VERSION ""

NS_ :

BS_:

BU_:

BO_ 2364613630 DCDC4OS: 8 Vector__XXX
 SG_ DCDC4HVILStatus : 4|2@1+ (1,0) [0|3] "" Vector__XXX
 SG_ DCDC4LoadshedRequest : 6|2@1+ (1,0) [0|3] "" Vector__XXX
 SG_ DCDC4OperationalStatus : 0|4@1+ (1,0) [0|15] "" Vector__XXX
 SG_ DCDC4PwrLmtdtCnvrtrTmprtr : 20|2@1+ (1,0) [0|3] "" Vector__XXX
 SG_ DCDC4PwrLmtdtEltrnFltrTmprtr : 22|2@1+ (1,0) [0|3] "" Vector__XXX
 SG_ DCDC4PwrLmtdtHghSdCrrnt : 8|2@1+ (1,0) [0|3] "" Vector__XXX
 SG_ DCDC4PwrLmtdtHghSdVltgMnmm : 12|2@1+ (1,0) [0|3] "" Vector__XXX
 SG_ DCDC4PwrLmtdtHghSdVltgMxmm : 14|2@1+ (1,0) [0|3] "" Vector__XXX
 SG_ DCDC4PwrLmtdtLwSdCrrnt : 10|2@1+ (1,0) [0|3] "" Vector__XXX
 SG_ DCDC4PwrLmtdtLwSdVltgMnmm : 16|2@1+ (1,0) [0|3] "" Vector__XXX
 SG_ DCDC4PwrLmtdtLwSdVltgMxmm : 18|2@1+ (1,0) [0|3] "" Vector__XXX
 SG_ DCDC4PwrLmtdtPwrEltrnsTmprtr : 24|2@1+ (1,0) [0|3] "" Vector__XXX
 SG_ DCDC4PwrLmtdtSLIBttrTrmnlCrrnt : 28|2@1+ (1,0) [0|3] "" Vector__XXX
 SG_ DCDC4PwrLmtdtSLIBttrTrmnlTmprtr : 30|2@1+ (1,0) [0|3] "" Vector__XXX
 SG_ DCDC4PwrLmtdtSLIBttrTrmnlVltg : 26|2@1+ (1,0) [0|3] "" Vector__XXX
 SG_ DCDC4PwrLmtdtUndfndRsn : 32|2@1+ (1,0) [0|3] "" Vector__XXX
 SG_ DCDC4OperatingStatusCounter : 52|4@1+ (1,0) [0|15] "" Vector__XXX
 SG_ DCDC4OperatingStatusCRC : 56|8@1+ (1,0) [0|255] "count" Vector__XXX

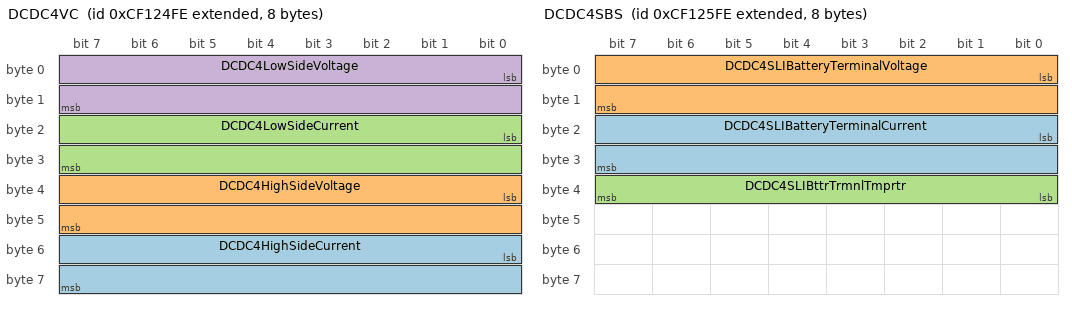
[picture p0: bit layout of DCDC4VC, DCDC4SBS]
BO_ 2364613886 DCDC4VC: 8 Vector__XXX
 SG_ DCDC4HighSideCurrent : 48|16@1+ (0.1,-3212.7) [-3212.7|3212.8] "A" Vector__XXX
 SG_ DCDC4HighSideVoltage : 32|16@1+ (0.05,0) [0|3212.75] "V" Vector__XXX
 SG_ DCDC4LowSideCurrent : 16|16@1+ (0.1,-3212.7) [-3212.7|3212.8] "A" Vector__XXX
 SG_ DCDC4LowSideVoltage : 0|16@1+ (0.01,0) [0|642.55] "V" Vector__XXX

BO_ 2364614142 DCDC4SBS: 8 Vector__XXX
 SG_ DCDC4SLIBatteryTerminalCurrent : 16|16@1+ (0.1,-3212.7) [-3212.7|3212.8] "A" Vector__XXX
 SG_ DCDC4SLIBatteryTerminalVoltage : 0|16@1+ (0.01,0) [0|642.55] "V" Vector__XXX
 SG_ DCDC4SLIBttrTrmnlTmprtr : 32|8@1+ (1,-40) [-40|210] "degC" Vector__XXX

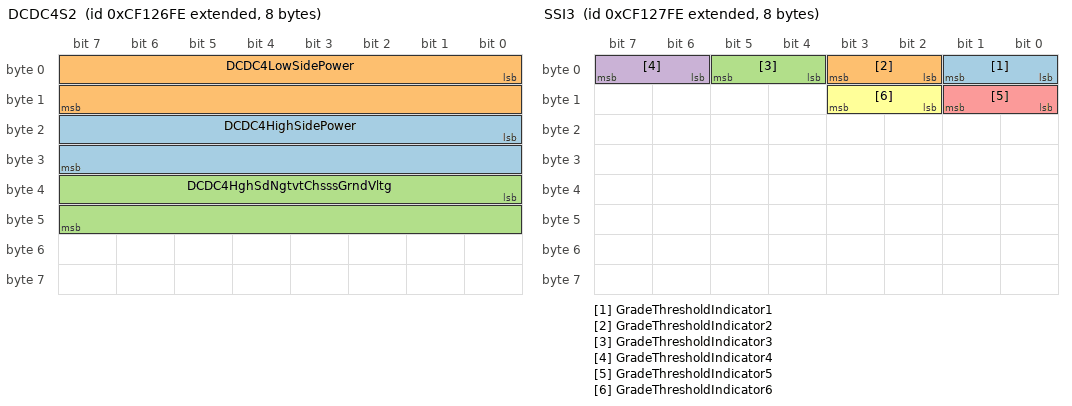
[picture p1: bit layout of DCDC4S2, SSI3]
BO_ 2364614398 DCDC4S2: 8 Vector__XXX
 SG_ DCDC4HighSidePower : 16|16@1+ (0.05,-1600) [-1600|1612.75] "kW" Vector__XXX
 SG_ DCDC4LowSidePower : 0|16@1+ (0.05,-1600) [-1600|1612.75] "kW" Vector__XXX
 SG_ DCDC4HghSdNgtvtChsssGrndVltg : 32|16@1+ (0.05,0) [0|3212.75] "V" Vector__XXX

BO_ 2364614654 SSI3: 8 Vector__XXX
 SG_ GradeThresholdIndicator1 : 0|2@1+ (1,0) [0|3] "" Vector__XXX
 SG_ GradeThresholdIndicator2 : 2|2@1+ (1,0) [0|3] "" Vector__XXX
 SG_ GradeThresholdIndicator3 : 4|2@1+ (1,0) [0|3] "" Vector__XXX
 SG_ GradeThresholdIndicator4 : 6|2@1+ (1,0) [0|3] "" Vector__XXX
 SG_ GradeThresholdIndicator5 : 8|2@1+ (1,0) [0|3] "" Vector__XXX
 SG_ GradeThresholdIndicator6 : 10|2@1+ (1,0) [0|3] "" Vector__XXX

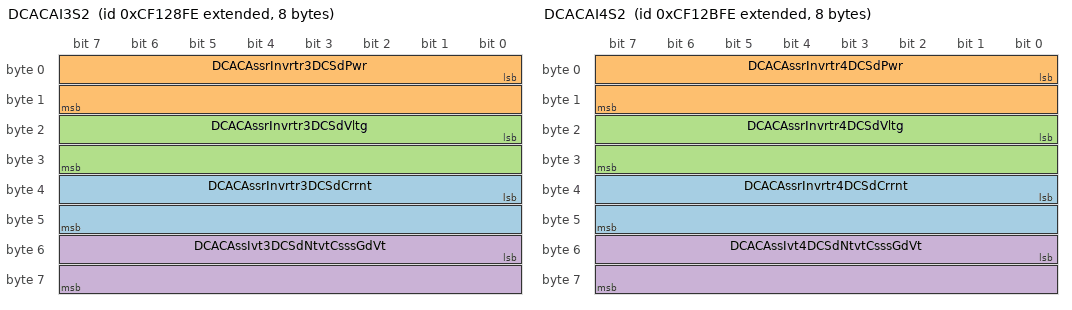
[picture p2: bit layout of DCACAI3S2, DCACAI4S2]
BO_ 2364614910 DCACAI3S2: 8 Vector__XXX
 SG_ DCACAssrInvrtr3DCSdCrrnt : 32|16@1+ (0.0625,0) [0|4015.9375] "A" Vector__XXX
 SG_ DCACAssrInvrtr3DCSdPwr : 0|16@1+ (0.0625,0) [0|4015.9375] "kW" Vector__XXX
 SG_ DCACAssrInvrtr3DCSdVltg : 16|16@1+ (0.05,0) [0|3212.75] "V" Vector__XXX
 SG_ DCACAssIvt3DCSdNtvtCsssGdVt : 48|16@1+ (0.05,0) [0|3212.75] "V" Vector__XXX

BO_ 2364615166 DCACAI3V: 8 Vector__XXX
 SG_ DCACAssrInvrtr3IgntnVltg : 0|16@1+ (0.05,0) [0|3212.75] "V" Vector__XXX
 SG_ DCACAssrInvrtr3UnswthdSLIVltg : 16|16@1+ (0.05,0) [0|3212.75] "V" Vector__XXX

BO_ 2364615678 DCACAI4S2: 8 Vector__XXX
 SG_ DCACAssrInvrtr4DCSdCrrnt : 32|16@1+ (0.0625,0) [0|4015.9375] "A" Vector__XXX
 SG_ DCACAssrInvrtr4DCSdPwr : 0|16@1+ (0.0625,0) [0|4015.9375] "kW" Vector__XXX
 SG_ DCACAssrInvrtr4DCSdVltg : 16|16@1+ (0.05,0) [0|3212.75] "V" Vector__XXX
 SG_ DCACAssIvt4DCSdNtvtCsssGdVt : 48|16@1+ (0.05,0) [0|3212.75] "V" Vector__XXX

BO_ 2364615934 DCACAI4V: 8 Vector__XXX
 SG_ DCACAssrInvrtr4IgntnVltg : 0|16@1+ (0.05,0) [0|3212.75] "V" Vector__XXX
 SG_ DCACAssrInvrtr4UnswthdSLIVltg : 16|16@1+ (0.05,0) [0|3212.75] "V" Vector__XXX

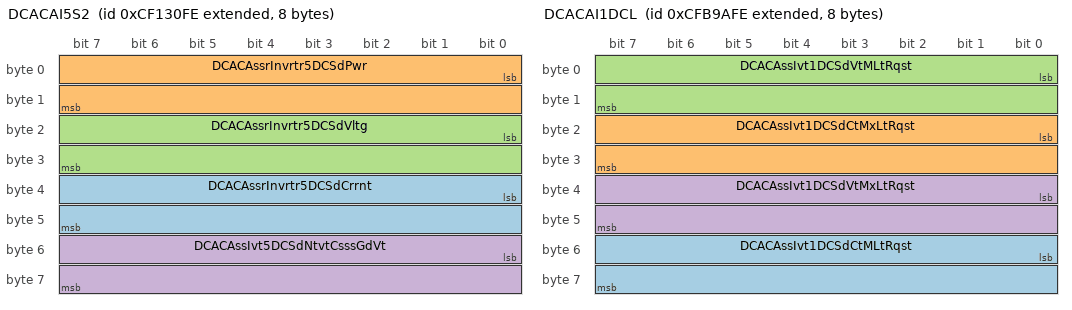
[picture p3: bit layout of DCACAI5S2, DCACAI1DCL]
BO_ 2364616958 DCACAI5S2: 8 Vector__XXX
 SG_ DCACAssrInvrtr5DCSdCrrnt : 32|16@1+ (0.0625,0) [0|4015.9375] "A" Vector__XXX
 SG_ DCACAssrInvrtr5DCSdPwr : 0|16@1+ (0.0625,0) [0|4015.9375] "kW" Vector__XXX
 SG_ DCACAssrInvrtr5DCSdVltg : 16|16@1+ (0.05,0) [0|3212.75] "V" Vector__XXX
 SG_ DCACAssIvt5DCSdNtvtCsssGdVt : 48|16@1+ (0.05,0) [0|3212.75] "V" Vector__XXX

BO_ 2364617214 DCACAI5V: 8 Vector__XXX
 SG_ DCACAssrInvrtr5IgntnVltg : 0|16@1+ (0.05,0) [0|3212.75] "V" Vector__XXX
 SG_ DCACAssrInvrtr5UnswthdSLIVltg : 16|16@1+ (0.05,0) [0|3212.75] "V" Vector__XXX

BO_ 2365296894 DCDC4V: 8 Vector__XXX
 SG_ DCDC4CntrllrInptIgntnVltg : 0|16@1+ (0.05,0) [0|3212.75] "V" Vector__XXX
 SG_ DCDC4CntrllrInptUnswthdSLIVltg : 16|16@1+ (0.05,0) [0|3212.75] "V" Vector__XXX

BO_ 2365297150 DCDC3V: 8 Vector__XXX
 SG_ DCDC3CntrllrInptIgntnVltg : 0|16@1+ (0.05,0) [0|3212.75] "V" Vector__XXX
 SG_ DCDC3CntrllrInptUnswthdSLIVltg : 16|16@1+ (0.05,0) [0|3212.75] "V" Vector__XXX

BO_ 2365297406 DCDC2V: 8 Vector__XXX
 SG_ DCDC2CntrllrInptIgntnVltg : 0|16@1+ (0.05,0) [0|3212.75] "V" Vector__XXX
 SG_ DCDC2CntrllrInptUnswthdSLIVltg : 16|16@1+ (0.05,0) [0|3212.75] "V" Vector__XXX

BO_ 2365297662 DCDC1V: 8 Vector__XXX
 SG_ DCDC1CntrllrInptIgntnVltg : 0|16@1+ (0.05,0) [0|3212.75] "V" Vector__XXX
 SG_ DCDC1CntrllrInptUnswthdSLIVltg : 16|16@1+ (0.05,0) [0|3212.75] "V" Vector__XXX

BO_ 2365299454 DCACAI1DCL: 8 Vector__XXX
 SG_ DCACAssIvt1DCSdCtMLtRqst : 48|16@1+ (0.05,-3212.75) [-3212.75|0] "A" Vector__XXX
 SG_ DCACAssIvt1DCSdCtMxLtRqst : 16|16@1+ (0.05,0) [0|3212.75] "A" Vector__XXX
 SG_ DCACAssIvt1DCSdVtMLtRqst : 0|16@1+ (0.05,0) [0|3212.75] "V" Vector__XXX
 SG_ DCACAssIvt1DCSdVtMxLtRqst : 32|16@1+ (0.05,0) [0|3212.75] "V" Vector__XXX

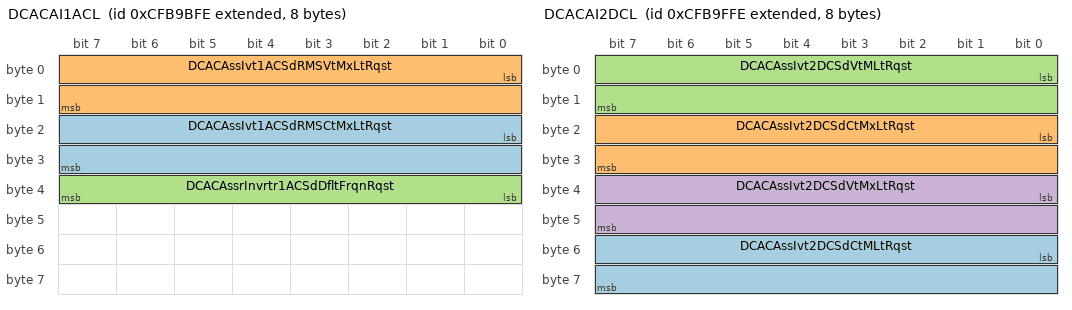
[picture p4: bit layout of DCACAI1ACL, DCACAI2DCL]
BO_ 2365299710 DCACAI1ACL: 8 Vector__XXX
 SG_ DCACAssIvt1ACSdRMSCtMxLtRqst : 16|16@1+ (0.03125,0) [0|2007.96875] "A" Vector__XXX
 SG_ DCACAssIvt1ACSdRMSVtMxLtRqst : 0|16@1+ (0.03125,0) [0|2007.96875] "V" Vector__XXX
 SG_ DCACAssrInvrtr1ACSdDfltFrqnRqst : 32|8@1+ (1,0) [0|250] "Hz" Vector__XXX

BO_ 2365300734 DCACAI2DCL: 8 Vector__XXX
 SG_ DCACAssIvt2DCSdCtMLtRqst : 48|16@1+ (0.05,-3212.75) [-3212.75|0] "A" Vector__XXX
 SG_ DCACAssIvt2DCSdCtMxLtRqst : 16|16@1+ (0.05,0) [0|3212.75] "A" Vector__XXX
 SG_ DCACAssIvt2DCSdVtMLtRqst : 0|16@1+ (0.05,0) [0|3212.75] "V" Vector__XXX
 SG_ DCACAssIvt2DCSdVtMxLtRqst : 32|16@1+ (0.05,0) [0|3212.75] "V" Vector__XXX

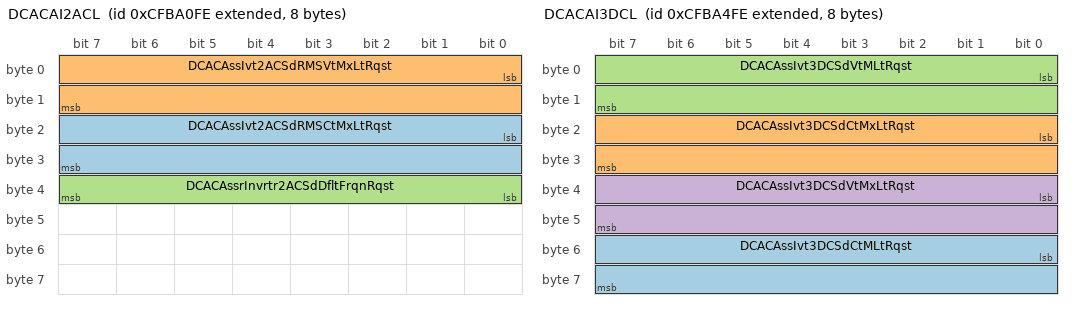
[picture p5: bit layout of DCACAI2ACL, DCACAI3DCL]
BO_ 2365300990 DCACAI2ACL: 8 Vector__XXX
 SG_ DCACAssIvt2ACSdRMSCtMxLtRqst : 16|16@1+ (0.03125,0) [0|2007.96875] "A" Vector__XXX
 SG_ DCACAssIvt2ACSdRMSVtMxLtRqst : 0|16@1+ (0.03125,0) [0|2007.96875] "V" Vector__XXX
 SG_ DCACAssrInvrtr2ACSdDfltFrqnRqst : 32|8@1+ (1,0) [0|250] "Hz" Vector__XXX

BO_ 2365302014 DCACAI3DCL: 8 Vector__XXX
 SG_ DCACAssIvt3DCSdCtMLtRqst : 48|16@1+ (0.05,-3212.75) [-3212.75|0] "A" Vector__XXX
 SG_ DCACAssIvt3DCSdCtMxLtRqst : 16|16@1+ (0.05,0) [0|3212.75] "A" Vector__XXX
 SG_ DCACAssIvt3DCSdVtMLtRqst : 0|16@1+ (0.05,0) [0|3212.75] "V" Vector__XXX
 SG_ DCACAssIvt3DCSdVtMxLtRqst : 32|16@1+ (0.05,0) [0|3212.75] "V" Vector__XXX

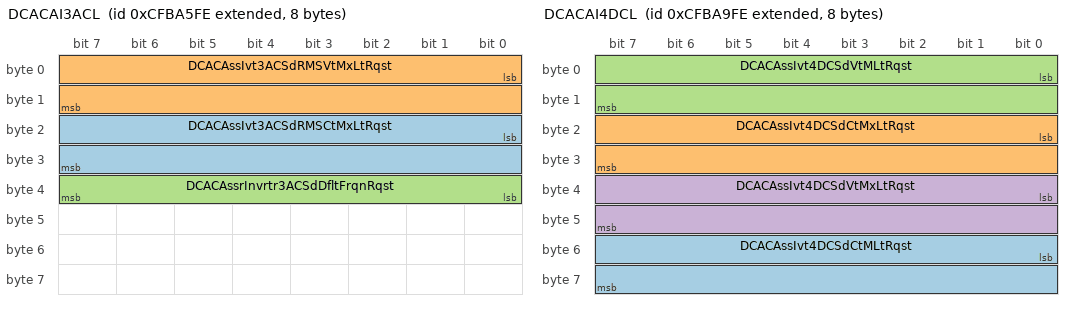
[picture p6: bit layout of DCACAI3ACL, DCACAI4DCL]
BO_ 2365302270 DCACAI3ACL: 8 Vector__XXX
 SG_ DCACAssIvt3ACSdRMSCtMxLtRqst : 16|16@1+ (0.03125,0) [0|2007.96875] "A" Vector__XXX
 SG_ DCACAssIvt3ACSdRMSVtMxLtRqst : 0|16@1+ (0.03125,0) [0|2007.96875] "V" Vector__XXX
 SG_ DCACAssrInvrtr3ACSdDfltFrqnRqst : 32|8@1+ (1,0) [0|250] "Hz" Vector__XXX

BO_ 2365303294 DCACAI4DCL: 8 Vector__XXX
 SG_ DCACAssIvt4DCSdCtMLtRqst : 48|16@1+ (0.05,-3212.75) [-3212.75|0] "A" Vector__XXX
 SG_ DCACAssIvt4DCSdCtMxLtRqst : 16|16@1+ (0.05,0) [0|3212.75] "A" Vector__XXX
 SG_ DCACAssIvt4DCSdVtMLtRqst : 0|16@1+ (0.05,0) [0|3212.75] "V" Vector__XXX
 SG_ DCACAssIvt4DCSdVtMxLtRqst : 32|16@1+ (0.05,0) [0|3212.75] "V" Vector__XXX

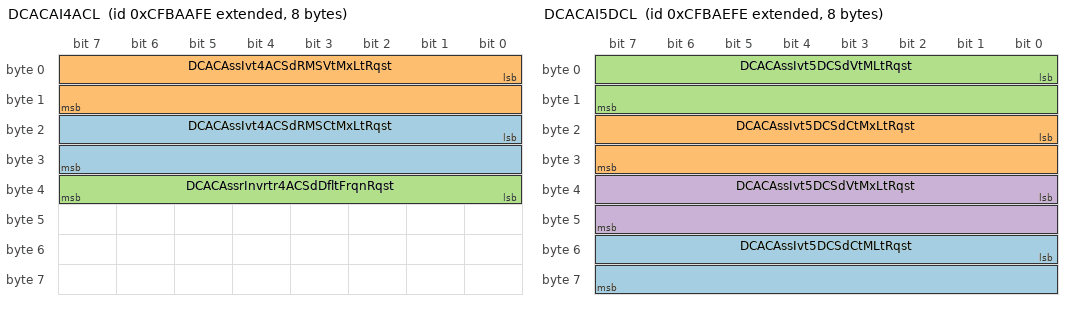
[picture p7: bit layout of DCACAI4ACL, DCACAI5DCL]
BO_ 2365303550 DCACAI4ACL: 8 Vector__XXX
 SG_ DCACAssIvt4ACSdRMSCtMxLtRqst : 16|16@1+ (0.03125,0) [0|2007.96875] "A" Vector__XXX
 SG_ DCACAssIvt4ACSdRMSVtMxLtRqst : 0|16@1+ (0.03125,0) [0|2007.96875] "V" Vector__XXX
 SG_ DCACAssrInvrtr4ACSdDfltFrqnRqst : 32|8@1+ (1,0) [0|250] "Hz" Vector__XXX

BO_ 2365304574 DCACAI5DCL: 8 Vector__XXX
 SG_ DCACAssIvt5DCSdCtMLtRqst : 48|16@1+ (0.05,-3212.75) [-3212.75|0] "A" Vector__XXX
 SG_ DCACAssIvt5DCSdCtMxLtRqst : 16|16@1+ (0.05,0) [0|3212.75] "A" Vector__XXX
 SG_ DCACAssIvt5DCSdVtMLtRqst : 0|16@1+ (0.05,0) [0|3212.75] "V" Vector__XXX
 SG_ DCACAssIvt5DCSdVtMxLtRqst : 32|16@1+ (0.05,0) [0|3212.75] "V" Vector__XXX

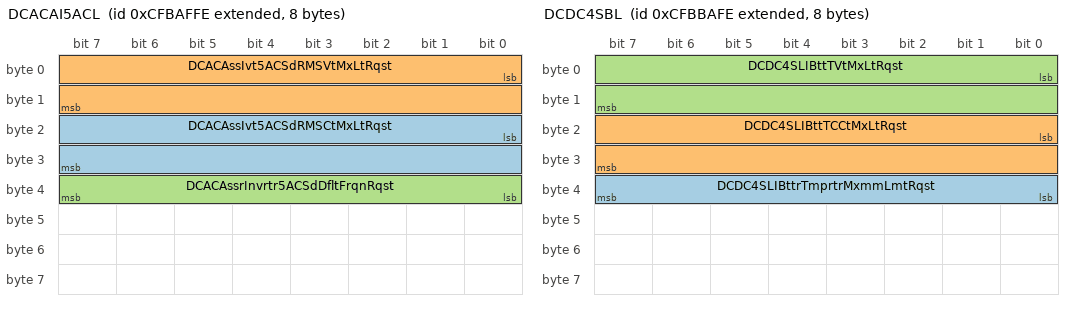
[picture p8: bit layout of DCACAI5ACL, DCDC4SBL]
BO_ 2365304830 DCACAI5ACL: 8 Vector__XXX
 SG_ DCACAssIvt5ACSdRMSCtMxLtRqst : 16|16@1+ (0.03125,0) [0|2007.96875] "A" Vector__XXX
 SG_ DCACAssIvt5ACSdRMSVtMxLtRqst : 0|16@1+ (0.03125,0) [0|2007.96875] "V" Vector__XXX
 SG_ DCACAssrInvrtr5ACSdDfltFrqnRqst : 32|8@1+ (1,0) [0|250] "Hz" Vector__XXX

BO_ 2365307646 DCDC4SBL: 8 Vector__XXX
 SG_ DCDC4SLIBttrTmprtrMxmmLmtRqst : 32|8@1+ (1,-40) [-40|210] "degC" Vector__XXX
 SG_ DCDC4SLIBttTCCtMxLtRqst : 16|16@1+ (0.05,0) [0|3212.75] "A" Vector__XXX
 SG_ DCDC4SLIBttTVtMxLtRqst : 0|16@1+ (0.01,0) [0|642.55] "V" Vector__XXX

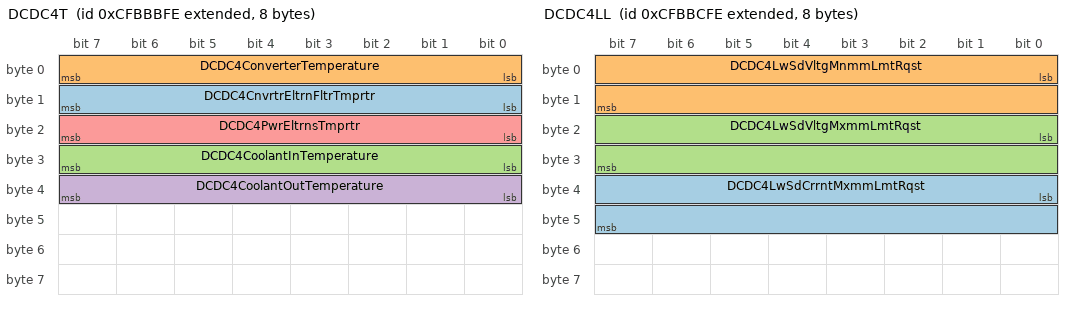
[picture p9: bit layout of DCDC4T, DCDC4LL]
BO_ 2365307902 DCDC4T: 8 Vector__XXX
 SG_ DCDC4CnvrtrEltrnFltrTmprtr : 8|8@1+ (1,-40) [-40|210] "degC" Vector__XXX
 SG_ DCDC4ConverterTemperature : 0|8@1+ (1,-40) [-40|210] "degC" Vector__XXX
 SG_ DCDC4CoolantInTemperature : 24|8@1+ (1,-40) [-40|210] "degC" Vector__XXX
 SG_ DCDC4CoolantOutTemperature : 32|8@1+ (1,-40) [-40|210] "degC" Vector__XXX
 SG_ DCDC4PwrEltrnsTmprtr : 16|8@1+ (1,-40) [-40|210] "degC" Vector__XXX

BO_ 2365308158 DCDC4LL: 8 Vector__XXX
 SG_ DCDC4LwSdCrrntMxmmLmtRqst : 32|16@1+ (0.05,0) [0|3212.75] "A" Vector__XXX
 SG_ DCDC4LwSdVltgMnmmLmtRqst : 0|16@1+ (0.01,0) [0|642.55] "V" Vector__XXX
 SG_ DCDC4LwSdVltgMxmmLmtRqst : 16|16@1+ (0.01,0) [0|642.55] "V" Vector__XXX

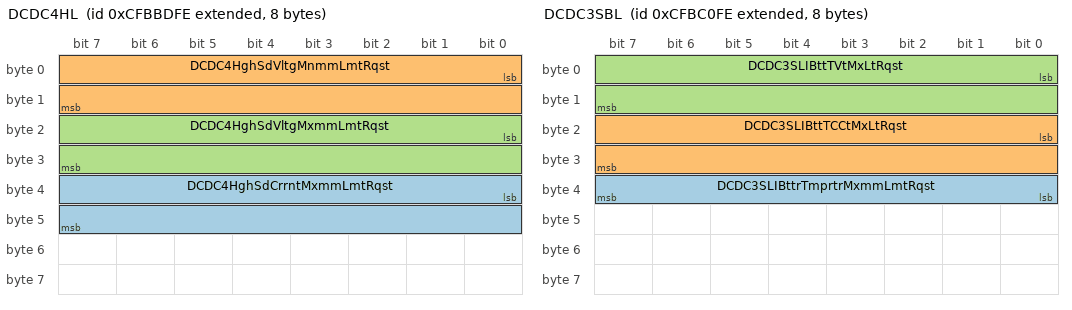
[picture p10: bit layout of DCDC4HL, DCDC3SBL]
BO_ 2365308414 DCDC4HL: 8 Vector__XXX
 SG_ DCDC4HghSdCrrntMxmmLmtRqst : 32|16@1+ (0.05,0) [0|3212.75] "A" Vector__XXX
 SG_ DCDC4HghSdVltgMnmmLmtRqst : 0|16@1+ (0.05,0) [0|3212.75] "V" Vector__XXX
 SG_ DCDC4HghSdVltgMxmmLmtRqst : 16|16@1+ (0.05,0) [0|3212.75] "V" Vector__XXX

BO_ 2365309182 DCDC3SBL: 8 Vector__XXX
 SG_ DCDC3SLIBttrTmprtrMxmmLmtRqst : 32|8@1+ (1,-40) [-40|210] "degC" Vector__XXX
 SG_ DCDC3SLIBttTCCtMxLtRqst : 16|16@1+ (0.05,0) [0|3212.75] "A" Vector__XXX
 SG_ DCDC3SLIBttTVtMxLtRqst : 0|16@1+ (0.01,0) [0|642.55] "V" Vector__XXX

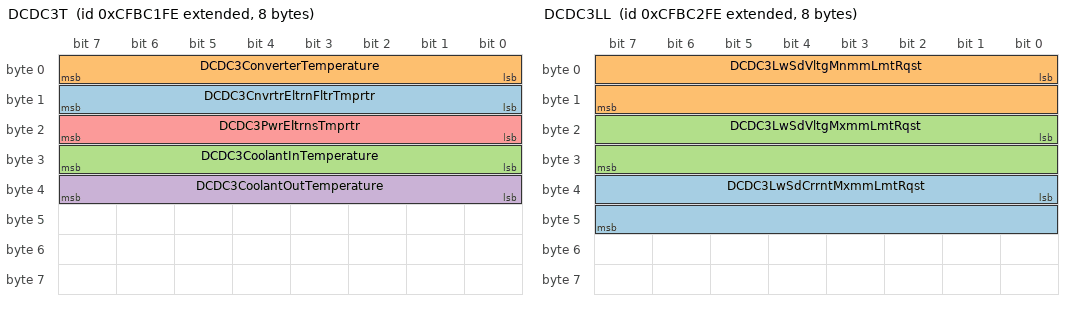
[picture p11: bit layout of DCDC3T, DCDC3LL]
BO_ 2365309438 DCDC3T: 8 Vector__XXX
 SG_ DCDC3CnvrtrEltrnFltrTmprtr : 8|8@1+ (1,-40) [-40|210] "degC" Vector__XXX
 SG_ DCDC3ConverterTemperature : 0|8@1+ (1,-40) [-40|210] "degC" Vector__XXX
 SG_ DCDC3CoolantInTemperature : 24|8@1+ (1,-40) [-40|210] "degC" Vector__XXX
 SG_ DCDC3CoolantOutTemperature : 32|8@1+ (1,-40) [-40|210] "degC" Vector__XXX
 SG_ DCDC3PwrEltrnsTmprtr : 16|8@1+ (1,-40) [-40|210] "degC" Vector__XXX

BO_ 2365309694 DCDC3LL: 8 Vector__XXX
 SG_ DCDC3LwSdCrrntMxmmLmtRqst : 32|16@1+ (0.05,0) [0|3212.75] "A" Vector__XXX
 SG_ DCDC3LwSdVltgMnmmLmtRqst : 0|16@1+ (0.01,0) [0|642.55] "V" Vector__XXX
 SG_ DCDC3LwSdVltgMxmmLmtRqst : 16|16@1+ (0.01,0) [0|642.55] "V" Vector__XXX

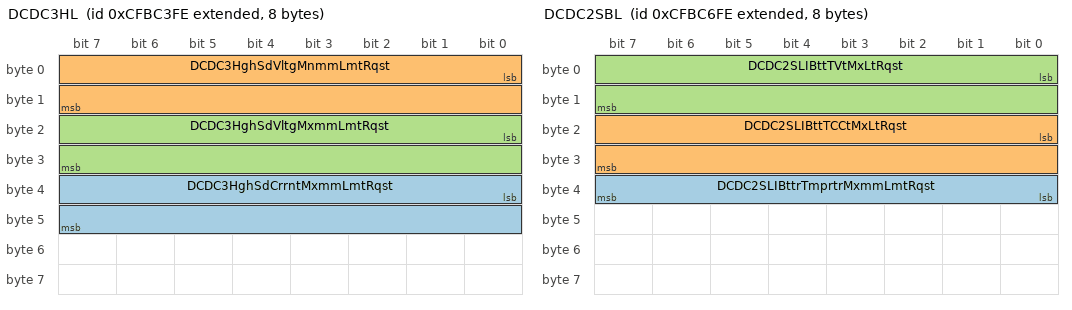
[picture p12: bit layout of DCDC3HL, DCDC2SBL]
BO_ 2365309950 DCDC3HL: 8 Vector__XXX
 SG_ DCDC3HghSdCrrntMxmmLmtRqst : 32|16@1+ (0.05,0) [0|3212.75] "A" Vector__XXX
 SG_ DCDC3HghSdVltgMnmmLmtRqst : 0|16@1+ (0.05,0) [0|3212.75] "V" Vector__XXX
 SG_ DCDC3HghSdVltgMxmmLmtRqst : 16|16@1+ (0.05,0) [0|3212.75] "V" Vector__XXX

BO_ 2365310718 DCDC2SBL: 8 Vector__XXX
 SG_ DCDC2SLIBttrTmprtrMxmmLmtRqst : 32|8@1+ (1,-40) [-40|210] "degC" Vector__XXX
 SG_ DCDC2SLIBttTCCtMxLtRqst : 16|16@1+ (0.05,0) [0|3212.75] "A" Vector__XXX
 SG_ DCDC2SLIBttTVtMxLtRqst : 0|16@1+ (0.01,0) [0|642.55] "V" Vector__XXX

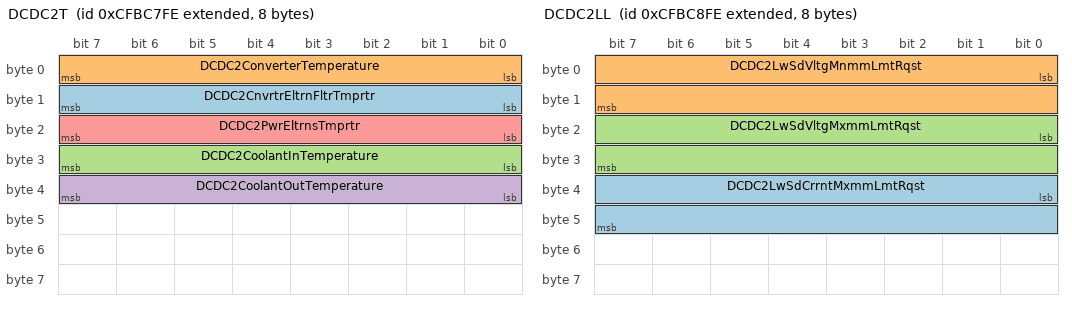
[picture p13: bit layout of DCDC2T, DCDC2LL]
BO_ 2365310974 DCDC2T: 8 Vector__XXX
 SG_ DCDC2CnvrtrEltrnFltrTmprtr : 8|8@1+ (1,-40) [-40|210] "degC" Vector__XXX
 SG_ DCDC2ConverterTemperature : 0|8@1+ (1,-40) [-40|210] "degC" Vector__XXX
 SG_ DCDC2CoolantInTemperature : 24|8@1+ (1,-40) [-40|210] "degC" Vector__XXX
 SG_ DCDC2CoolantOutTemperature : 32|8@1+ (1,-40) [-40|210] "degC" Vector__XXX
 SG_ DCDC2PwrEltrnsTmprtr : 16|8@1+ (1,-40) [-40|210] "degC" Vector__XXX

BO_ 2365311230 DCDC2LL: 8 Vector__XXX
 SG_ DCDC2LwSdCrrntMxmmLmtRqst : 32|16@1+ (0.05,0) [0|3212.75] "A" Vector__XXX
 SG_ DCDC2LwSdVltgMnmmLmtRqst : 0|16@1+ (0.01,0) [0|642.55] "V" Vector__XXX
 SG_ DCDC2LwSdVltgMxmmLmtRqst : 16|16@1+ (0.01,0) [0|642.55] "V" Vector__XXX

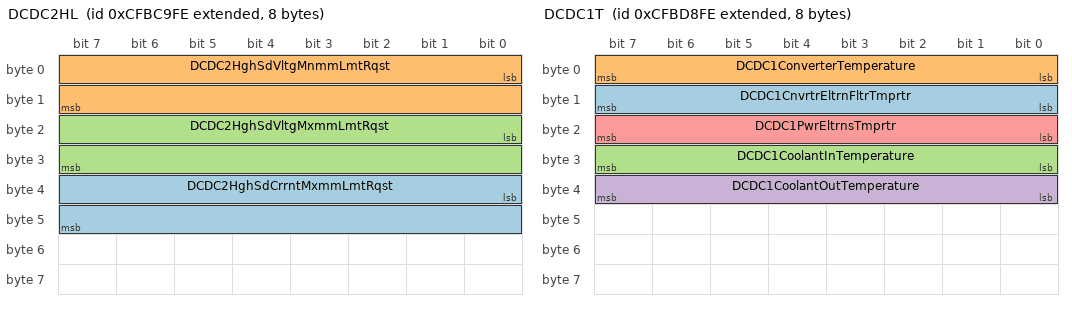
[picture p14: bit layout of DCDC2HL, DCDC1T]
BO_ 2365311486 DCDC2HL: 8 Vector__XXX
 SG_ DCDC2HghSdCrrntMxmmLmtRqst : 32|16@1+ (0.05,0) [0|3212.75] "A" Vector__XXX
 SG_ DCDC2HghSdVltgMnmmLmtRqst : 0|16@1+ (0.05,0) [0|3212.75] "V" Vector__XXX
 SG_ DCDC2HghSdVltgMxmmLmtRqst : 16|16@1+ (0.05,0) [0|3212.75] "V" Vector__XXX

BO_ 2365313534 DCDC1SBL: 8 Vector__XXX
 SG_ DCDC1SLIBttrTmprtrMxmmLmtRqst : 32|8@1+ (1,-40) [-40|210] "degC" Vector__XXX
 SG_ DCDC1SLIBttTCCtMxLtRqst : 16|16@1+ (0.05,0) [0|3212.75] "A" Vector__XXX
 SG_ DCDC1SLIBttTVtMxLtRqst : 0|16@1+ (0.01,0) [0|642.55] "V" Vector__XXX

BO_ 2365315326 DCDC1T: 8 Vector__XXX
 SG_ DCDC1CnvrtrEltrnFltrTmprtr : 8|8@1+ (1,-40) [-40|210] "degC" Vector__XXX
 SG_ DCDC1ConverterTemperature : 0|8@1+ (1,-40) [-40|210] "degC" Vector__XXX
 SG_ DCDC1CoolantInTemperature : 24|8@1+ (1,-40) [-40|210] "degC" Vector__XXX
 SG_ DCDC1CoolantOutTemperature : 32|8@1+ (1,-40) [-40|210] "degC" Vector__XXX
 SG_ DCDC1PwrEltrnsTmprtr : 16|8@1+ (1,-40) [-40|210] "degC" Vector__XXX

BO_ 2365315582 DCDC1LL: 8 Vector__XXX
 SG_ DCDC1LwSdCrrntMxmmLmtRqst : 32|16@1+ (0.05,0) [0|3212.75] "A" Vector__XXX
 SG_ DCDC1LwSdVltgMnmmLmtRqst : 0|16@1+ (0.01,0) [0|642.55] "V" Vector__XXX
 SG_ DCDC1LwSdVltgMxmmLmtRqst : 16|16@1+ (0.01,0) [0|642.55] "V" Vector__XXX

BO_ 2365315838 DCDC1HL: 8 Vector__XXX
 SG_ DCDC1HghSdCrrntMxmmLmtRqst : 32|16@1+ (0.05,0) [0|3212.75] "A" Vector__XXX
 SG_ DCDC1HghSdVltgMnmmLmtRqst : 0|16@1+ (0.05,0) [0|3212.75] "V" Vector__XXX
 SG_ DCDC1HghSdVltgMxmmLmtRqst : 16|16@1+ (0.05,0) [0|3212.75] "V" Vector__XXX

BO_ 2365318910 HVESSFC: 8 Vector__XXX
 SG_ HVESSFanEnableCommand : 0|2@1+ (1,0) [0|3] "" Vector__XXX
 SG_ HVESSFanPowerHold : 2|2@1+ (1,0) [0|3] "" Vector__XXX
 SG_ HVESSFanSpeedCommand : 8|16@1+ (0.5,0) [0|32127.5] "rpm" Vector__XXX
 SG_ HVESSFanPercentSpeedCommand : 24|8@1+ (0.4,0) [0|100] "%" Vector__XXX
 SG_ HVESSFanInstance1 : 32|1@1+ (1,0) [0|1] "" Vector__XXX
 SG_ HVESSFanInstance2 : 33|1@1+ (1,0) [0|1] "" Vector__XXX
 SG_ HVESSFanInstance3 : 34|1@1+ (1,0) [0|1] "" Vector__XXX
 SG_ HVESSFanInstance4 : 35|1@1+ (1,0) [0|1] "" Vector__XXX
 SG_ HVESSFanInstance5 : 36|1@1+ (1,0) [0|1] "" Vector__XXX
 SG_ HVESSFanInstance6 : 37|1@1+ (1,0) [0|1] "" Vector__XXX
 SG_ HVESSFanInstance7 : 38|1@1+ (1,0) [0|1] "" Vector__XXX
 SG_ HVESSFanInstance8 : 39|1@1+ (1,0) [0|1] "" Vector__XXX
 SG_ HVESSFanInstance9 : 40|1@1+ (1,0) [0|1] "" Vector__XXX
 SG_ HVESSFanInstance10 : 41|1@1+ (1,0) [0|1] "" Vector__XXX
 SG_ HVESSFanInstance11 : 42|1@1+ (1,0) [0|1] "" Vector__XXX
 SG_ HVESSFanInstance12 : 43|1@1+ (1,0) [0|1] "" Vector__XXX
 SG_ HVESSFanInstance13 : 44|1@1+ (1,0) [0|1] "" Vector__XXX
 SG_ HVESSFanInstance14 : 45|1@1+ (1,0) [0|1] "" Vector__XXX
 SG_ HVESSFanInstance15 : 46|1@1+ (1,0) [0|1] "" Vector__XXX

BO_ 2365322238 CCVS5: 8 Vector__XXX
 SG_ DirectionalVehicleSpeed : 0|16@1+ (0.0078125,-250) [-250|251.992] "km/h" Vector__XXX

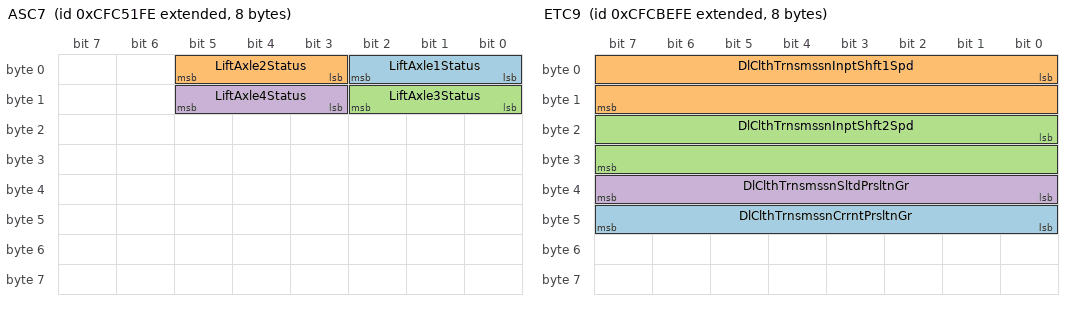
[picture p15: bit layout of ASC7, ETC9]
BO_ 2365346302 ASC7: 8 Vector__XXX
 SG_ LiftAxle1Status : 0|3@1+ (1,0) [0|7] "" Vector__XXX
 SG_ LiftAxle2Status : 3|3@1+ (1,0) [0|7] "" Vector__XXX
 SG_ LiftAxle3Status : 8|3@1+ (1,0) [0|7] "" Vector__XXX
 SG_ LiftAxle4Status : 11|3@1+ (1,0) [0|7] "" Vector__XXX

BO_ 2365348350 ELS: 8 Vector__XXX
 SG_ EngineLoadShareStatus : 2|4@1+ (1,0) [0|15] "" Vector__XXX
 SG_ EngineUnloadStatus : 0|2@1+ (1,0) [0|3] "" Vector__XXX

BO_ 2365363710 ECPMSI: 8 Vector__XXX
 SG_ EngnClndrPrssrMntr1PrlmnrFMI : 0|5@1+ (1,0) [0|31] "binary" Vector__XXX
 SG_ EngnClndrPrssrMntr2PrlmnrFMI : 8|5@1+ (1,0) [0|31] "binary" Vector__XXX

BO_ 2365374206 ETC9: 8 Vector__XXX
 SG_ DlClthTrnsmssnCrrntPrsltnGr : 40|8@1+ (1,-125) [-125|125] "gear value" Vector__XXX
 SG_ DlClthTrnsmssnInptShft1Spd : 0|16@1+ (0.125,0) [0|8031.875] "rpm" Vector__XXX
 SG_ DlClthTrnsmssnInptShft2Spd : 16|16@1+ (0.125,0) [0|8031.875] "rpm" Vector__XXX
 SG_ DlClthTrnsmssnSltdPrsltnGr : 32|8@1+ (1,-125) [-125|125] "gear value" Vector__XXX

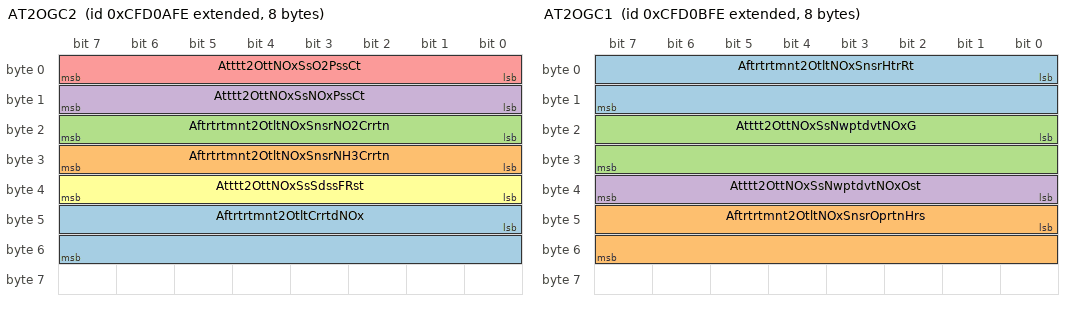
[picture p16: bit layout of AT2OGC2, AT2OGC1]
BO_ 2365393662 AT2OGC2: 8 Vector__XXX
 SG_ Aftrtrtmnt2OtltCrrtdNOx : 40|16@1+ (0.05,-200) [-200|3012.75] "ppm" Vector__XXX
 SG_ Aftrtrtmnt2OtltNOxSnsrNH3Crrtn : 24|8@1+ (0.5,0) [0|125] "%" Vector__XXX
 SG_ Aftrtrtmnt2OtltNOxSnsrNO2Crrtn : 16|8@1+ (0.5,0) [0|125] "%" Vector__XXX
 SG_ Atttt2OttNOxSsNOxPssCt : 8|8@1+ (0.5,0) [0|125] "%/bar" Vector__XXX
 SG_ Atttt2OttNOxSsO2PssCt : 0|8@1+ (0.5,0) [0|125] "%/bar" Vector__XXX
 SG_ Atttt2OttNOxSsSdssFRst : 32|8@1+ (1,0) [0|250] "Ratio" Vector__XXX

BO_ 2365393918 AT2OGC1: 8 Vector__XXX
 SG_ Aftrtrtmnt2OtltNOxSnsrHtrRt : 0|16@1+ (0.001,0) [0|64.255] "Ratio" Vector__XXX
 SG_ Aftrtrtmnt2OtltNOxSnsrOprtnHrs : 40|16@1+ (1,0) [0|64255] "h" Vector__XXX
 SG_ Atttt2OttNOxSsNwptdvtNOxG : 16|16@1+ (0.1,-100) [-100|6325.5] "%" Vector__XXX
 SG_ Atttt2OttNOxSsNwptdvtNOxOst : 32|8@1+ (1,-125) [-125|125] "ppm" Vector__XXX

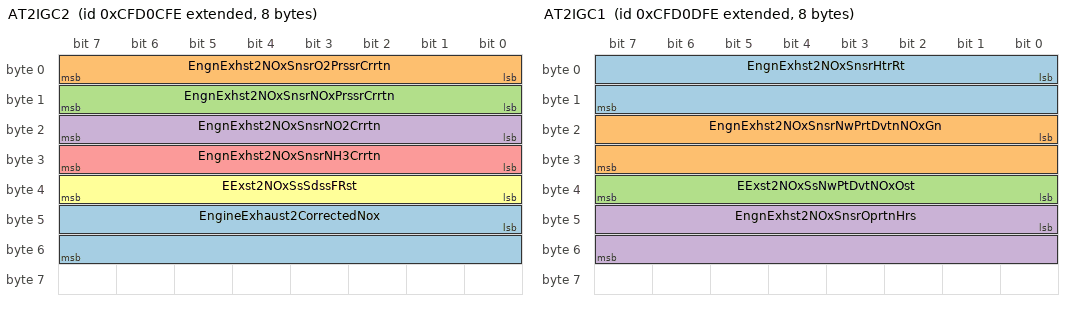
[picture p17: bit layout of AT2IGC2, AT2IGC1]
BO_ 2365394174 AT2IGC2: 8 Vector__XXX
 SG_ EngineExhaust2CorrectedNox : 40|16@1+ (0.05,-200) [-200|3012.75] "ppm" Vector__XXX
 SG_ EngnExhst2NOxSnsrO2PrssrCrrtn : 0|8@1+ (0.5,0) [0|125] "%/bar" Vector__XXX
 SG_ EngnExhst2NOxSnsrNOxPrssrCrrtn : 8|8@1+ (0.5,0) [0|125] "%/bar" Vector__XXX
 SG_ EngnExhst2NOxSnsrNO2Crrtn : 16|8@1+ (0.5,0) [0|125] "%" Vector__XXX
 SG_ EngnExhst2NOxSnsrNH3Crrtn : 24|8@1+ (0.5,0) [0|125] "%" Vector__XXX
 SG_ EExst2NOxSsSdssFRst : 32|8@1+ (1,0) [0|250] "Ratio" Vector__XXX

BO_ 2365394430 AT2IGC1: 8 Vector__XXX
 SG_ EngnExhst2NOxSnsrHtrRt : 0|16@1+ (0.001,0) [0|64.255] "Ratio" Vector__XXX
 SG_ EngnExhst2NOxSnsrNwPrtDvtnNOxGn : 16|16@1+ (0.1,-100) [-100|6325.5] "%" Vector__XXX
 SG_ EExst2NOxSsNwPtDvtNOxOst : 32|8@1+ (1,-125) [-125|125] "ppm" Vector__XXX
 SG_ EngnExhst2NOxSnsrOprtnHrs : 40|16@1+ (1,0) [0|64255] "h" Vector__XXX

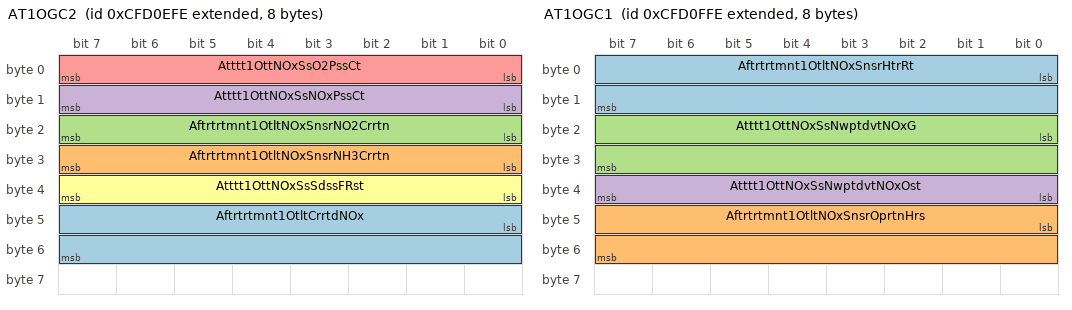
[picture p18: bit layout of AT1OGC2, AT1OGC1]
BO_ 2365394686 AT1OGC2: 8 Vector__XXX
 SG_ Aftrtrtmnt1OtltCrrtdNOx : 40|16@1+ (0.05,-200) [-200|3012.75] "ppm" Vector__XXX
 SG_ Aftrtrtmnt1OtltNOxSnsrNH3Crrtn : 24|8@1+ (0.5,0) [0|125] "%" Vector__XXX
 SG_ Aftrtrtmnt1OtltNOxSnsrNO2Crrtn : 16|8@1+ (0.5,0) [0|125] "%" Vector__XXX
 SG_ Atttt1OttNOxSsNOxPssCt : 8|8@1+ (0.5,0) [0|125] "%/bar" Vector__XXX
 SG_ Atttt1OttNOxSsO2PssCt : 0|8@1+ (0.5,0) [0|125] "%/bar" Vector__XXX
 SG_ Atttt1OttNOxSsSdssFRst : 32|8@1+ (1,0) [0|250] "Ratio" Vector__XXX

BO_ 2365394942 AT1OGC1: 8 Vector__XXX
 SG_ Aftrtrtmnt1OtltNOxSnsrHtrRt : 0|16@1+ (0.001,0) [0|64.255] "Ratio" Vector__XXX
 SG_ Aftrtrtmnt1OtltNOxSnsrOprtnHrs : 40|16@1+ (1,0) [0|64255] "h" Vector__XXX
 SG_ Atttt1OttNOxSsNwptdvtNOxG : 16|16@1+ (0.1,-100) [-100|6325.5] "%" Vector__XXX
 SG_ Atttt1OttNOxSsNwptdvtNOxOst : 32|8@1+ (1,-125) [-125|125] "ppm" Vector__XXX

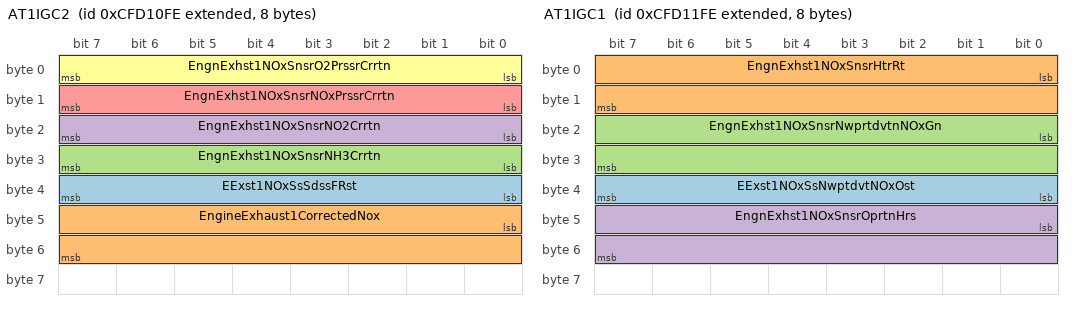
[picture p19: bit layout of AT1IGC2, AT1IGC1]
BO_ 2365395198 AT1IGC2: 8 Vector__XXX
 SG_ EExst1NOxSsSdssFRst : 32|8@1+ (1,0) [0|250] "Ratio" Vector__XXX
 SG_ EngineExhaust1CorrectedNox : 40|16@1+ (0.05,-200) [-200|3012.75] "ppm" Vector__XXX
 SG_ EngnExhst1NOxSnsrNH3Crrtn : 24|8@1+ (0.5,0) [0|125] "%" Vector__XXX
 SG_ EngnExhst1NOxSnsrNO2Crrtn : 16|8@1+ (0.5,0) [0|125] "%" Vector__XXX
 SG_ EngnExhst1NOxSnsrNOxPrssrCrrtn : 8|8@1+ (0.5,0) [0|125] "%/bar" Vector__XXX
 SG_ EngnExhst1NOxSnsrO2PrssrCrrtn : 0|8@1+ (0.5,0) [0|125] "%/bar" Vector__XXX

BO_ 2365395454 AT1IGC1: 8 Vector__XXX
 SG_ EExst1NOxSsNwptdvtNOxOst : 32|8@1+ (1,-125) [-125|125] "ppm" Vector__XXX
 SG_ EngnExhst1NOxSnsrHtrRt : 0|16@1+ (0.001,0) [0|64.255] "Ratio" Vector__XXX
 SG_ EngnExhst1NOxSnsrNwprtdvtnNOxGn : 16|16@1+ (0.1,-100) [-100|6325.5] "%" Vector__XXX
 SG_ EngnExhst1NOxSnsrOprtnHrs : 40|16@1+ (1,0) [0|64255] "h" Vector__XXX

BO_ 2365400062 EJM10: 8 Vector__XXX
 SG_ Joystick10Button13PressedStatus : 62|2@1+ (1,0) [0|3] "" Vector__XXX
 SG_ Joystick10Button14PressedStatus : 60|2@1+ (1,0) [0|3] "" Vector__XXX
 SG_ Joystick10Button15PressedStatus : 58|2@1+ (1,0) [0|3] "" Vector__XXX
 SG_ Joystick10Button16PressedStatus : 56|2@1+ (1,0) [0|3] "" Vector__XXX
 SG_ Joystick10GripXAxisPosition : 6|10@1+ (0.1,0) [0|102] "%" Vector__XXX
 SG_ Joystick10GripYAxisPosition : 22|10@1+ (0.1,0) [0|102] "%" Vector__XXX
 SG_ Joystick10ThetaAxisPosition : 38|10@1+ (0.1,0) [0|102] "%" Vector__XXX
 SG_ Jst10GpXAxsLvRtPstvPstStts : 4|2@1+ (1,0) [0|3] "" Vector__XXX
 SG_ Jst10GpYAxsLvFwdPstvPstStts : 20|2@1+ (1,0) [0|3] "" Vector__XXX
 SG_ Jst10TtAxsCtCwsNtvPstStts : 34|2@1+ (1,0) [0|3] "" Vector__XXX
 SG_ Jstk10GrpXAxsDtntPstnStts : 54|2@1+ (1,0) [0|3] "" Vector__XXX
 SG_ Jstk10GrpXAxsLvrLftNgtvPstnStts : 2|2@1+ (1,0) [0|3] "" Vector__XXX
 SG_ Jstk10GrpXAxsNtrlPstnStts : 0|2@1+ (1,0) [0|3] "" Vector__XXX
 SG_ Jstk10GrpYAxsDtntPstnStts : 52|2@1+ (1,0) [0|3] "" Vector__XXX
 SG_ Jstk10GrpYAxsLvrBkNgtvPstnStts : 18|2@1+ (1,0) [0|3] "" Vector__XXX
 SG_ Jstk10GrpYAxsNtrlPstnStts : 16|2@1+ (1,0) [0|3] "" Vector__XXX
 SG_ Jstk10ThtAxsClkwsPstvPstnStts : 36|2@1+ (1,0) [0|3] "" Vector__XXX
 SG_ Jstk10ThtAxsDtntPstnStts : 50|2@1+ (1,0) [0|3] "" Vector__XXX
 SG_ Jstk10ThtAxsNtrlPstnStts : 32|2@1+ (1,0) [0|3] "" Vector__XXX

BO_ 2365400318 BJM10: 8 Vector__XXX
 SG_ Joystick10Button10PressedStatus : 60|2@1+ (1,0) [0|3] "" Vector__XXX
 SG_ Joystick10Button11PressedStatus : 58|2@1+ (1,0) [0|3] "" Vector__XXX
 SG_ Joystick10Button12PressedStatus : 56|2@1+ (1,0) [0|3] "" Vector__XXX
 SG_ Joystick10Button1PressedStatus : 46|2@1+ (1,0) [0|3] "" Vector__XXX
 SG_ Joystick10Button2PressedStatus : 44|2@1+ (1,0) [0|3] "" Vector__XXX
 SG_ Joystick10Button3PressedStatus : 42|2@1+ (1,0) [0|3] "" Vector__XXX
 SG_ Joystick10Button4PressedStatus : 40|2@1+ (1,0) [0|3] "" Vector__XXX
 SG_ Joystick10Button5PressedStatus : 54|2@1+ (1,0) [0|3] "" Vector__XXX
 SG_ Joystick10Button6PressedStatus : 52|2@1+ (1,0) [0|3] "" Vector__XXX
 SG_ Joystick10Button7PressedStatus : 50|2@1+ (1,0) [0|3] "" Vector__XXX
 SG_ Joystick10Button8PressedStatus : 48|2@1+ (1,0) [0|3] "" Vector__XXX
 SG_ Joystick10Button9PressedStatus : 62|2@1+ (1,0) [0|3] "" Vector__XXX
 SG_ Joystick10XAxisPosition : 6|10@1+ (0.1,0) [0|102] "%" Vector__XXX
 SG_ Joystick10YAxisPosition : 22|10@1+ (0.1,0) [0|102] "%" Vector__XXX
 SG_ Jstk10XAxsDtntPstnStts : 38|2@1+ (1,0) [0|3] "" Vector__XXX
 SG_ Jstk10XAxsLvrLftNgtvPstnStts : 2|2@1+ (1,0) [0|3] "" Vector__XXX
 SG_ Jstk10XAxsLvrRghtPstvPstnStts : 4|2@1+ (1,0) [0|3] "" Vector__XXX
 SG_ Jstk10XAxsNtrlPstnStts : 0|2@1+ (1,0) [0|3] "" Vector__XXX
 SG_ Jstk10YAxsDtntPstnStts : 36|2@1+ (1,0) [0|3] "" Vector__XXX
 SG_ Jstk10YAxsLvrBkNgtvPstnStts : 18|2@1+ (1,0) [0|3] "" Vector__XXX
 SG_ Jstk10YAxsLvrFrwrdPstvPstnStts : 20|2@1+ (1,0) [0|3] "" Vector__XXX
 SG_ Jstk10YAxsNtrlPstnStts : 16|2@1+ (1,0) [0|3] "" Vector__XXX

BO_ 2365400574 EJM9: 8 Vector__XXX
 SG_ Joystick9Button13PressedStatus : 62|2@1+ (1,0) [0|3] "" Vector__XXX
 SG_ Joystick9Button14PressedStatus : 60|2@1+ (1,0) [0|3] "" Vector__XXX
 SG_ Joystick9Button15PressedStatus : 58|2@1+ (1,0) [0|3] "" Vector__XXX
 SG_ Joystick9Button16PressedStatus : 56|2@1+ (1,0) [0|3] "" Vector__XXX
 SG_ Joystick9GripXAxisPosition : 6|10@1+ (0.1,0) [0|102] "%" Vector__XXX
 SG_ Joystick9GripYAxisPosition : 22|10@1+ (0.1,0) [0|102] "%" Vector__XXX
 SG_ Joystick9ThetaAxisPosition : 38|10@1+ (0.1,0) [0|102] "%" Vector__XXX
 SG_ Jst9GpYAxsLvFwdPstvPstStts : 20|2@1+ (1,0) [0|3] "" Vector__XXX
 SG_ Jst9TtAxsCtCwsNtvPstStts : 34|2@1+ (1,0) [0|3] "" Vector__XXX
 SG_ Jstk9GrpXAxsDtntPstnStts : 54|2@1+ (1,0) [0|3] "" Vector__XXX
 SG_ Jstk9GrpXAxsLvrLftNgtvPstnStts : 2|2@1+ (1,0) [0|3] "" Vector__XXX
 SG_ Jstk9GrpXAxsLvrRghtPstvPstnStts : 4|2@1+ (1,0) [0|3] "" Vector__XXX
 SG_ Jstk9GrpXAxsNtrlPstnStts : 0|2@1+ (1,0) [0|3] "" Vector__XXX
 SG_ Jstk9GrpYAxsDtntPstnStts : 52|2@1+ (1,0) [0|3] "" Vector__XXX
 SG_ Jstk9GrpYAxsLvrBkNgtvPstnStts : 18|2@1+ (1,0) [0|3] "" Vector__XXX
 SG_ Jstk9GrpYAxsNtrlPstnStts : 16|2@1+ (1,0) [0|3] "" Vector__XXX
 SG_ Jstk9ThtAxsClkwsPstvPstnStts : 36|2@1+ (1,0) [0|3] "" Vector__XXX
 SG_ Jstk9ThtAxsDtntPstnStts : 50|2@1+ (1,0) [0|3] "" Vector__XXX
 SG_ Jstk9ThtAxsNtrlPstnStts : 32|2@1+ (1,0) [0|3] "" Vector__XXX

BO_ 2365400830 BJM9: 8 Vector__XXX
 SG_ Joystick9Button10PressedStatus : 60|2@1+ (1,0) [0|3] "" Vector__XXX
 SG_ Joystick9Button11PressedStatus : 58|2@1+ (1,0) [0|3] "" Vector__XXX
 SG_ Joystick9Button12PressedStatus : 56|2@1+ (1,0) [0|3] "" Vector__XXX
 SG_ Joystick9Button1PressedStatus : 46|2@1+ (1,0) [0|3] "" Vector__XXX
 SG_ Joystick9Button2PressedStatus : 44|2@1+ (1,0) [0|3] "" Vector__XXX
 SG_ Joystick9Button3PressedStatus : 42|2@1+ (1,0) [0|3] "" Vector__XXX
 SG_ Joystick9Button4PressedStatus : 40|2@1+ (1,0) [0|3] "" Vector__XXX
 SG_ Joystick9Button5PressedStatus : 54|2@1+ (1,0) [0|3] "" Vector__XXX
 SG_ Joystick9Button6PressedStatus : 52|2@1+ (1,0) [0|3] "" Vector__XXX
 SG_ Joystick9Button7PressedStatus : 50|2@1+ (1,0) [0|3] "" Vector__XXX
 SG_ Joystick9Button8PressedStatus : 48|2@1+ (1,0) [0|3] "" Vector__XXX
 SG_ Joystick9Button9PressedStatus : 62|2@1+ (1,0) [0|3] "" Vector__XXX
 SG_ Joystick9XAxisPosition : 6|10@1+ (0.1,0) [0|102] "%" Vector__XXX
 SG_ Joystick9YAxisPosition : 22|10@1+ (0.1,0) [0|102] "%" Vector__XXX
 SG_ Jstk9XAxsDtntPstnStts : 38|2@1+ (1,0) [0|3] "" Vector__XXX
 SG_ Jstk9XAxsLvrLftNgtvPstnStts : 2|2@1+ (1,0) [0|3] "" Vector__XXX
 SG_ Jstk9XAxsLvrRghtPstvPstnStts : 4|2@1+ (1,0) [0|3] "" Vector__XXX
 SG_ Jstk9XAxsNtrlPstnStts : 0|2@1+ (1,0) [0|3] "" Vector__XXX
 SG_ Jstk9YAxsDtntPstnStts : 36|2@1+ (1,0) [0|3] "" Vector__XXX
 SG_ Jstk9YAxsLvrBkNgtvPstnStts : 18|2@1+ (1,0) [0|3] "" Vector__XXX
 SG_ Jstk9YAxsLvrFrwrdPstvPstnStts : 20|2@1+ (1,0) [0|3] "" Vector__XXX
 SG_ Jstk9YAxsNtrlPstnStts : 16|2@1+ (1,0) [0|3] "" Vector__XXX

BO_ 2365401086 EJM8: 8 Vector__XXX
 SG_ Joystick8Button13PressedStatus : 62|2@1+ (1,0) [0|3] "" Vector__XXX
 SG_ Joystick8Button14PressedStatus : 60|2@1+ (1,0) [0|3] "" Vector__XXX
 SG_ Joystick8Button15PressedStatus : 58|2@1+ (1,0) [0|3] "" Vector__XXX
 SG_ Joystick8Button16PressedStatus : 56|2@1+ (1,0) [0|3] "" Vector__XXX
 SG_ Joystick8GripXAxisPosition : 6|10@1+ (0.1,0) [0|102] "%" Vector__XXX
 SG_ Joystick8GripYAxisPosition : 22|10@1+ (0.1,0) [0|102] "%" Vector__XXX
 SG_ Joystick8ThetaAxisPosition : 38|10@1+ (0.1,0) [0|102] "%" Vector__XXX
 SG_ Jst8GpYAxsLvFwdPstvPstStts : 20|2@1+ (1,0) [0|3] "" Vector__XXX
 SG_ Jst8TtAxsCtCwsNtvPstStts : 34|2@1+ (1,0) [0|3] "" Vector__XXX
 SG_ Jstk8GrpXAxsDtntPstnStts : 54|2@1+ (1,0) [0|3] "" Vector__XXX
 SG_ Jstk8GrpXAxsLvrLftNgtvPstnStts : 2|2@1+ (1,0) [0|3] "" Vector__XXX
 SG_ Jstk8GrpXAxsLvrRghtPstvPstnStts : 4|2@1+ (1,0) [0|3] "" Vector__XXX
 SG_ Jstk8GrpXAxsNtrlPstnStts : 0|2@1+ (1,0) [0|3] "" Vector__XXX
 SG_ Jstk8GrpYAxsDtntPstnStts : 52|2@1+ (1,0) [0|3] "" Vector__XXX
 SG_ Jstk8GrpYAxsLvrBkNgtvPstnStts : 18|2@1+ (1,0) [0|3] "" Vector__XXX
 SG_ Jstk8GrpYAxsNtrlPstnStts : 16|2@1+ (1,0) [0|3] "" Vector__XXX
 SG_ Jstk8ThtAxsClkwsPstvPstnStts : 36|2@1+ (1,0) [0|3] "" Vector__XXX
 SG_ Jstk8ThtAxsDtntPstnStts : 50|2@1+ (1,0) [0|3] "" Vector__XXX
 SG_ Jstk8ThtAxsNtrlPstnStts : 32|2@1+ (1,0) [0|3] "" Vector__XXX

BO_ 2365401342 BJM8: 8 Vector__XXX
 SG_ Joystick8Button10PressedStatus : 60|2@1+ (1,0) [0|3] "" Vector__XXX
 SG_ Joystick8Button11PressedStatus : 58|2@1+ (1,0) [0|3] "" Vector__XXX
 SG_ Joystick8Button12PressedStatus : 56|2@1+ (1,0) [0|3] "" Vector__XXX
 SG_ Joystick8Button1PressedStatus : 46|2@1+ (1,0) [0|3] "" Vector__XXX
 SG_ Joystick8Button2PressedStatus : 44|2@1+ (1,0) [0|3] "" Vector__XXX
 SG_ Joystick8Button3PressedStatus : 42|2@1+ (1,0) [0|3] "" Vector__XXX
 SG_ Joystick8Button4PressedStatus : 40|2@1+ (1,0) [0|3] "" Vector__XXX
 SG_ Joystick8Button5PressedStatus : 54|2@1+ (1,0) [0|3] "" Vector__XXX
 SG_ Joystick8Button6PressedStatus : 52|2@1+ (1,0) [0|3] "" Vector__XXX
 SG_ Joystick8Button7PressedStatus : 50|2@1+ (1,0) [0|3] "" Vector__XXX
 SG_ Joystick8Button8PressedStatus : 48|2@1+ (1,0) [0|3] "" Vector__XXX
 SG_ Joystick8Button9PressedStatus : 62|2@1+ (1,0) [0|3] "" Vector__XXX
 SG_ Joystick8XAxisPosition : 6|10@1+ (0.1,0) [0|102] "%" Vector__XXX
 SG_ Joystick8YAxisPosition : 22|10@1+ (0.1,0) [0|102] "%" Vector__XXX
 SG_ Jstk8XAxsDtntPstnStts : 38|2@1+ (1,0) [0|3] "" Vector__XXX
 SG_ Jstk8XAxsLvrLftNgtvPstnStts : 2|2@1+ (1,0) [0|3] "" Vector__XXX
 SG_ Jstk8XAxsLvrRghtPstvPstnStts : 4|2@1+ (1,0) [0|3] "" Vector__XXX
 SG_ Jstk8XAxsNtrlPstnStts : 0|2@1+ (1,0) [0|3] "" Vector__XXX
 SG_ Jstk8YAxsDtntPstnStts : 36|2@1+ (1,0) [0|3] "" Vector__XXX
 SG_ Jstk8YAxsLvrBkNgtvPstnStts : 18|2@1+ (1,0) [0|3] "" Vector__XXX
 SG_ Jstk8YAxsLvrFrwrdPstvPstnStts : 20|2@1+ (1,0) [0|3] "" Vector__XXX
 SG_ Jstk8YAxsNtrlPstnStts : 16|2@1+ (1,0) [0|3] "" Vector__XXX

BO_ 2365401598 EJM7: 8 Vector__XXX
 SG_ Joystick7Button13PressedStatus : 62|2@1+ (1,0) [0|3] "" Vector__XXX
 SG_ Joystick7Button14PressedStatus : 60|2@1+ (1,0) [0|3] "" Vector__XXX
 SG_ Joystick7Button15PressedStatus : 58|2@1+ (1,0) [0|3] "" Vector__XXX
 SG_ Joystick7Button16PressedStatus : 56|2@1+ (1,0) [0|3] "" Vector__XXX
 SG_ Joystick7GripXAxisPosition : 6|10@1+ (0.1,0) [0|102] "%" Vector__XXX
 SG_ Joystick7GripYAxisPosition : 22|10@1+ (0.1,0) [0|102] "%" Vector__XXX
 SG_ Joystick7ThetaAxisPosition : 38|10@1+ (0.1,0) [0|102] "%" Vector__XXX
 SG_ Jst7GpYAxsLvFwdPstvPstStts : 20|2@1+ (1,0) [0|3] "" Vector__XXX
 SG_ Jst7TtAxsCtCwsNtvPstStts : 34|2@1+ (1,0) [0|3] "" Vector__XXX
 SG_ Jstk7GrpXAxsDtntPstnStts : 54|2@1+ (1,0) [0|3] "" Vector__XXX
 SG_ Jstk7GrpXAxsLvrLftNgtvPstnStts : 2|2@1+ (1,0) [0|3] "" Vector__XXX
 SG_ Jstk7GrpXAxsLvrRghtPstvPstnStts : 4|2@1+ (1,0) [0|3] "" Vector__XXX
 SG_ Jstk7GrpXAxsNtrlPstnStts : 0|2@1+ (1,0) [0|3] "" Vector__XXX
 SG_ Jstk7GrpYAxsDtntPstnStts : 52|2@1+ (1,0) [0|3] "" Vector__XXX
 SG_ Jstk7GrpYAxsLvrBkNgtvPstnStts : 18|2@1+ (1,0) [0|3] "" Vector__XXX
 SG_ Jstk7GrpYAxsNtrlPstnStts : 16|2@1+ (1,0) [0|3] "" Vector__XXX
 SG_ Jstk7ThtAxsClkwsPstvPstnStts : 36|2@1+ (1,0) [0|3] "" Vector__XXX
 SG_ Jstk7ThtAxsDtntPstnStts : 50|2@1+ (1,0) [0|3] "" Vector__XXX
 SG_ Jstk7ThtAxsNtrlPstnStts : 32|2@1+ (1,0) [0|3] "" Vector__XXX

BO_ 2365401854 BJM7: 8 Vector__XXX
 SG_ Joystick7Button10PressedStatus : 60|2@1+ (1,0) [0|3] "" Vector__XXX
 SG_ Joystick7Button11PressedStatus : 58|2@1+ (1,0) [0|3] "" Vector__XXX
 SG_ Joystick7Button12PressedStatus : 56|2@1+ (1,0) [0|3] "" Vector__XXX
 SG_ Joystick7Button1PressedStatus : 46|2@1+ (1,0) [0|3] "" Vector__XXX
 SG_ Joystick7Button2PressedStatus : 44|2@1+ (1,0) [0|3] "" Vector__XXX
 SG_ Joystick7Button3PressedStatus : 42|2@1+ (1,0) [0|3] "" Vector__XXX
 SG_ Joystick7Button4PressedStatus : 40|2@1+ (1,0) [0|3] "" Vector__XXX
 SG_ Joystick7Button5PressedStatus : 54|2@1+ (1,0) [0|3] "" Vector__XXX
 SG_ Joystick7Button6PressedStatus : 52|2@1+ (1,0) [0|3] "" Vector__XXX
 SG_ Joystick7Button7PressedStatus : 50|2@1+ (1,0) [0|3] "" Vector__XXX
 SG_ Joystick7Button8PressedStatus : 48|2@1+ (1,0) [0|3] "" Vector__XXX
 SG_ Joystick7Button9PressedStatus : 62|2@1+ (1,0) [0|3] "" Vector__XXX
 SG_ Joystick7XAxisPosition : 6|10@1+ (0.1,0) [0|102] "%" Vector__XXX
 SG_ Joystick7YAxisPosition : 22|10@1+ (0.1,0) [0|102] "%" Vector__XXX
 SG_ Jstk7XAxsDtntPstnStts : 38|2@1+ (1,0) [0|3] "" Vector__XXX
 SG_ Jstk7XAxsLvrLftNgtvPstnStts : 2|2@1+ (1,0) [0|3] "" Vector__XXX
 SG_ Jstk7XAxsLvrRghtPstvPstnStts : 4|2@1+ (1,0) [0|3] "" Vector__XXX
 SG_ Jstk7XAxsNtrlPstnStts : 0|2@1+ (1,0) [0|3] "" Vector__XXX
 SG_ Jstk7YAxsDtntPstnStts : 36|2@1+ (1,0) [0|3] "" Vector__XXX
 SG_ Jstk7YAxsLvrBkNgtvPstnStts : 18|2@1+ (1,0) [0|3] "" Vector__XXX
 SG_ Jstk7YAxsLvrFrwrdPstvPstnStts : 20|2@1+ (1,0) [0|3] "" Vector__XXX
 SG_ Jstk7YAxsNtrlPstnStts : 16|2@1+ (1,0) [0|3] "" Vector__XXX

BO_ 2365402110 EJM6: 8 Vector__XXX
 SG_ Joystick6Button13PressedStatus : 62|2@1+ (1,0) [0|3] "" Vector__XXX
 SG_ Joystick6Button14PressedStatus : 60|2@1+ (1,0) [0|3] "" Vector__XXX
 SG_ Joystick6Button15PressedStatus : 58|2@1+ (1,0) [0|3] "" Vector__XXX
 SG_ Joystick6Button16PressedStatus : 56|2@1+ (1,0) [0|3] "" Vector__XXX
 SG_ Joystick6GripXAxisPosition : 6|10@1+ (0.1,0) [0|102] "%" Vector__XXX
 SG_ Joystick6GripYAxisPosition : 22|10@1+ (0.1,0) [0|102] "%" Vector__XXX
 SG_ Joystick6ThetaAxisPosition : 38|10@1+ (0.1,0) [0|102] "%" Vector__XXX
 SG_ Jst6GpYAxsLvFwdPstvPstStts : 20|2@1+ (1,0) [0|3] "" Vector__XXX
 SG_ Jst6TtAxsCtCwsNtvPstStts : 34|2@1+ (1,0) [0|3] "" Vector__XXX
 SG_ Jstk6GrpXAxsDtntPstnStts : 54|2@1+ (1,0) [0|3] "" Vector__XXX
 SG_ Jstk6GrpXAxsLvrLftNgtvPstnStts : 2|2@1+ (1,0) [0|3] "" Vector__XXX
 SG_ Jstk6GrpXAxsLvrRghtPstvPstnStts : 4|2@1+ (1,0) [0|3] "" Vector__XXX
 SG_ Jstk6GrpXAxsNtrlPstnStts : 0|2@1+ (1,0) [0|3] "" Vector__XXX
 SG_ Jstk6GrpYAxsDtntPstnStts : 52|2@1+ (1,0) [0|3] "" Vector__XXX
 SG_ Jstk6GrpYAxsLvrBkNgtvPstnStts : 18|2@1+ (1,0) [0|3] "" Vector__XXX
 SG_ Jstk6GrpYAxsNtrlPstnStts : 16|2@1+ (1,0) [0|3] "" Vector__XXX
 SG_ Jstk6ThtAxsClkwsPstvPstnStts : 36|2@1+ (1,0) [0|3] "" Vector__XXX
 SG_ Jstk6ThtAxsDtntPstnStts : 50|2@1+ (1,0) [0|3] "" Vector__XXX
 SG_ Jstk6ThtAxsNtrlPstnStts : 32|2@1+ (1,0) [0|3] "" Vector__XXX

BO_ 2365402366 BJM6: 8 Vector__XXX
 SG_ Joystick6Button10PressedStatus : 60|2@1+ (1,0) [0|3] "" Vector__XXX
 SG_ Joystick6Button11PressedStatus : 58|2@1+ (1,0) [0|3] "" Vector__XXX
 SG_ Joystick6Button12PressedStatus : 56|2@1+ (1,0) [0|3] "" Vector__XXX
 SG_ Joystick6Button1PressedStatus : 46|2@1+ (1,0) [0|3] "" Vector__XXX
 SG_ Joystick6Button2PressedStatus : 44|2@1+ (1,0) [0|3] "" Vector__XXX
 SG_ Joystick6Button3PressedStatus : 42|2@1+ (1,0) [0|3] "" Vector__XXX
 SG_ Joystick6Button4PressedStatus : 40|2@1+ (1,0) [0|3] "" Vector__XXX
 SG_ Joystick6Button5PressedStatus : 54|2@1+ (1,0) [0|3] "" Vector__XXX
 SG_ Joystick6Button6PressedStatus : 52|2@1+ (1,0) [0|3] "" Vector__XXX
 SG_ Joystick6Button7PressedStatus : 50|2@1+ (1,0) [0|3] "" Vector__XXX
 SG_ Joystick6Button8PressedStatus : 48|2@1+ (1,0) [0|3] "" Vector__XXX
 SG_ Joystick6Button9PressedStatus : 62|2@1+ (1,0) [0|3] "" Vector__XXX
 SG_ Joystick6XAxisPosition : 6|10@1+ (0.1,0) [0|102] "%" Vector__XXX
 SG_ Joystick6YAxisPosition : 22|10@1+ (0.1,0) [0|102] "%" Vector__XXX
 SG_ Jstk6XAxsDtntPstnStts : 38|2@1+ (1,0) [0|3] "" Vector__XXX
 SG_ Jstk6XAxsLvrLftNgtvPstnStts : 2|2@1+ (1,0) [0|3] "" Vector__XXX
 SG_ Jstk6XAxsLvrRghtPstvPstnStts : 4|2@1+ (1,0) [0|3] "" Vector__XXX
 SG_ Jstk6XAxsNtrlPstnStts : 0|2@1+ (1,0) [0|3] "" Vector__XXX
 SG_ Jstk6YAxsDtntPstnStts : 36|2@1+ (1,0) [0|3] "" Vector__XXX
 SG_ Jstk6YAxsLvrBkNgtvPstnStts : 18|2@1+ (1,0) [0|3] "" Vector__XXX
 SG_ Jstk6YAxsLvrFrwrdPstvPstnStts : 20|2@1+ (1,0) [0|3] "" Vector__XXX
 SG_ Jstk6YAxsNtrlPstnStts : 16|2@1+ (1,0) [0|3] "" Vector__XXX

CM_ BO_ 2364613630 "DC/DC Converter 4 Operating Status";
CM_ SG_ 2364613630 DCDC4HVILStatus "DC/DC 4 HVIL Status: High Voltage Interlock Loop (HVIL) state of the DC/DC Converter.00b = HVIL Closed01b = HVIL Open10b = Error11b = Not Available";
CM_ SG_ 2364613630 DCDC4LoadshedRequest "DC/DC 4 Loadshed Request: The loadshed request is a request to the controlling device to reduce the DC/DC Converter loads.  The Loadshed Requested state is an indication that this DC/DC Converter has a malfunction or is in a limit condition and if th...";
CM_ SG_ 2364613630 DCDC4OperationalStatus "DC/DC 4 Operational Status: Operating state of the DC/DC Converter0000b = Disabled 0001b = Initialization in process.  The device is powering up.  This process may include both internal checks, as well as system checks being run by the DC/DC Converte...";
CM_ SG_ 2364613630 DCDC4PwrLmtdtCnvrtrTmprtr "DC/DC 4 Power Limit due to Converter Temperature: Indicates whether or not output power is being limited due to Converter Temperature (see SPN 9046) approaching or exceeding the maximum limit.00b = No power limit for this reason01b = Power limited fo...";
CM_ SG_ 2364613630 DCDC4PwrLmtdtEltrnFltrTmprtr "DC/DC 4 Power Limit due to Electronic Filter Temperature: Indicates whether or not output power is being limited due to Output Electronic Filter Temperature (see SPN 9047) approaching or exceeding the maximum limit.00b = No power limit for this reaso...";
CM_ SG_ 2364613630 DCDC4PwrLmtdtHghSdCrrnt "DC/DC 4 Power Limit due to High Side Current: Indicates whether or not output power is being limited due to high side current (see SPN 9024) approaching or exceeding the maximum limit (see SPN 9056).00b = No power limit for this reason01b = Power lim...";
CM_ SG_ 2364613630 DCDC4PwrLmtdtHghSdVltgMnmm "DC/DC 4 Power Limit due to High Side Voltage Minimum: Indicates whether or not output power is being limited due to high side voltage (see SPN 9023) approaching or falling below the minimum limit (see SPN 9054).00b = No power limit for this reason01b...";
CM_ SG_ 2364613630 DCDC4PwrLmtdtHghSdVltgMxmm "DC/DC 4 Power Limit due to High Side Voltage Maximum: Indicates whether or not output power is being limited due to high side voltage (see SPN 9023) approaching or exceeding the maximum limit (see SPN 9055).00b = No power limit for this reason01b = P...";
CM_ SG_ 2364613630 DCDC4PwrLmtdtLwSdCrrnt "DC/DC 4 Power Limit due to Low Side Current: Indicates whether or not output power is being limited due to low side current (see SPN 9022) approaching or exceeding the maximum limit (see SPN 9053).00b = No power limit for this reason01b = Power limit...";
CM_ SG_ 2364613630 DCDC4PwrLmtdtLwSdVltgMnmm "DC/DC 4 Power Limit due to Low Side Voltage Minimum: Indicates whether or not output power is being limited due to low side voltage (see SPN 9021) approaching or falling below the minimum limit (see SPN 9051).00b = No power limit for this reason01b =...";
CM_ SG_ 2364613630 DCDC4PwrLmtdtLwSdVltgMxmm "DC/DC 4 Power Limit due to Low Side Voltage Maximum: Indicates whether or not output power is being limited due to low side voltage (see SPN 9021) approaching or exceeding the maximum limit (see SPN 9052).00b = No power limit for this reason01b = Pow...";
CM_ SG_ 2364613630 DCDC4PwrLmtdtPwrEltrnsTmprtr "DC/DC 4 Power Limit due to Power Electronics Temperature: Indicates whether or not output power is being limited due to Power Electronics Temperature (see SPN 9048) approaching or exceeding the maximum limit.00b = No power limit for this reason01b = ...";
CM_ SG_ 2364613630 DCDC4PwrLmtdtSLIBttrTrmnlCrrnt "DC/DC 4 Power Limit due to SLI Battery Terminal Current: Indicates whether or not output power is being limited due to the SLI battery terminal current (see SPN 9026) approaching or exceeding limits (see SPN 9044).00b = No power limit for this reason...";
CM_ SG_ 2364613630 DCDC4PwrLmtdtSLIBttrTrmnlTmprtr "DC/DC 4 Power Limit due to SLI Battery Terminal Temperature: Indicates whether or not output power is being limited due to the SLI battery terminal temperature (see SPN 9027) approaching or exceeding limits (see SPN 9045).00b = No power limit for thi...";
CM_ SG_ 2364613630 DCDC4PwrLmtdtSLIBttrTrmnlVltg "DC/DC 4 Power Limit due to SLI Battery Terminal Voltage: Indicates whether or not output power is being limited due to the SLI battery terminal voltage (see SPN 9025) approaching or exceeding limits (see SPN 9043).00b = No power limit for this reason...";
CM_ SG_ 2364613630 DCDC4PwrLmtdtUndfndRsn "DC/DC 4 Power Limit due to Undefined Reason: Indicates whether or not output power is being limited due to an undefined reason.00b = No power limit for this reason01b = Power limited for this reason10b = Error11b = Not Available";
CM_ SG_ 2364613630 DCDC4OperatingStatusCounter "DCDC 4 Operating Status Counter: The message counter is used to detect situations where the transmitting ECU malfunction repeats the same frame all the time. The receiver of the information may use the counter parameter to detect this situation. The ...";
CM_ SG_ 2364613630 DCDC4OperatingStatusCRC "DCDC 4 Operating Status CRC: The CRC is defined as follows: • Length: 8 bits • Polynomial: x^8+x^5+x^3+x^2+x+1 • Initial Value: FFh • Input Data Reflection: Not reflected • Result Data Reflection: Not reflected • XOR value: FFhSAE makes no claim of t...";
CM_ BO_ 2364613886 "DC/DC Converter 4 Voltage and Current";
CM_ SG_ 2364613886 DCDC4HighSideCurrent "DC/DC 4 High Side Current: Indicates the measured HVES or high side current measured at the point of control inside the DC/DC Converter.  The current is negative if the converter is charging the SLI battery from the hybrid battery.";
CM_ SG_ 2364613886 DCDC4HighSideVoltage "DC/DC 4 High Side Voltage: Indicates the measured HVES or high side voltage measured at the point of control inside the DC/DC Converter.";
CM_ SG_ 2364613886 DCDC4LowSideCurrent "DC/DC 4 Low Side Current: Indicates the measured SLI battery or low side current measured at the point of control inside the DC/DC Converter.  The current is positive if the converter is charging the SLI battery from the hybrid battery.";
CM_ SG_ 2364613886 DCDC4LowSideVoltage "DC/DC 4 Low Side Voltage: Indicates the measured SLI battery or low side voltage measured at the point of control inside the DC/DC Converter.";
CM_ BO_ 2364614142 "DC/DC Converter 4 SLI Battery Status";
CM_ SG_ 2364614142 DCDC4SLIBatteryTerminalCurrent "DC/DC 4 SLI Battery Terminal Current: Parameter indicating the SLI battery terminal current for control use by the DC/DC converter.  The current is positive if the SLI battery or low side voltage source is being charged from the HVES.";
CM_ SG_ 2364614142 DCDC4SLIBatteryTerminalVoltage "DC/DC 4 SLI Battery Terminal Voltage: Parameter indicating the SLI battery terminal voltage for control use by the DC/DC converter.";
CM_ SG_ 2364614142 DCDC4SLIBttrTrmnlTmprtr "DC/DC 4 SLI Battery Terminal Temperature: Parameter indicating the SLI battery terminal temperature for control use by the DC/DC converter.";
CM_ BO_ 2364614398 "DC/DC Converter 4 Status 2";
CM_ SG_ 2364614398 DCDC4HighSidePower "DC/DC 4 High Side Power: Indicates the measured HVES or high side power measured at the DC/DC Converter.  The high side power is positive if the converter is charging the hybrid battery from the SLI battery (i.e. Boost Mode).  The high side power is ...";
CM_ SG_ 2364614398 DCDC4LowSidePower "DC/DC 4 Low Side Power: Indicates the measured SLI battery or low side power measured at the DC/DC Converter.  The low side power is positive if the converter is charging the SLI battery from the hybrid battery (i.e. Buck Mode).  The low side power i...";
CM_ SG_ 2364614398 DCDC4HghSdNgtvtChsssGrndVltg "DC/DC 4 High Side Negative to Chassis Ground Voltage: The voltage level of the high voltage DC side, as measured by the DC/DC between the negative side of the High Voltage DC Side input and the chassis of the DC/DC enclosure.  This voltage can be use...";
CM_ BO_ 2364614654 "Slope Sensor Information 3";
CM_ SG_ 2364614654 GradeThresholdIndicator1 "Grade Threshold Indicator 1: This parameter indicates whether or not the transmitting device has sensed a vehicle grade equal to or exceeding a manufacturer-defined threshold. The manufacturer-defined threshold could be a simple fixed value or a dyna...";
CM_ SG_ 2364614654 GradeThresholdIndicator2 "Grade Threshold Indicator 2: This parameter indicates whether or not the transmitting device has sensed a vehicle grade equal to or exceeding a manufacturer-defined threshold. The manufacturer-defined threshold could be a simple fixed value or a dyna...";
CM_ SG_ 2364614654 GradeThresholdIndicator3 "Grade Threshold Indicator 3: This parameter indicates whether or not the transmitting device has sensed a vehicle grade equal to or exceeding a manufacturer-defined threshold. The manufacturer-defined threshold could be a simple fixed value or a dyna...";
CM_ SG_ 2364614654 GradeThresholdIndicator4 "Grade Threshold Indicator 4: This parameter indicates whether or not the transmitting device has sensed a vehicle grade equal to or exceeding a manufacturer-defined threshold. The manufacturer-defined threshold could be a simple fixed value or a dyna...";
CM_ SG_ 2364614654 GradeThresholdIndicator5 "Grade Threshold Indicator 5: This parameter indicates whether or not the transmitting device has sensed a vehicle grade equal to or exceeding a manufacturer-defined threshold. The manufacturer-defined threshold could be a simple fixed value or a dyna...";
CM_ SG_ 2364614654 GradeThresholdIndicator6 "Grade Threshold Indicator 6: This parameter indicates whether or not the transmitting device has sensed a vehicle grade equal to or exceeding a manufacturer-defined threshold. The manufacturer-defined threshold could be a simple fixed value or a dyna...";
CM_ BO_ 2364614910 "DC/AC Accessory Inverter 3 Status 2";
CM_ SG_ 2364614910 DCACAssrInvrtr3DCSdCrrnt "DC/AC Accessory Inverter 3 DC Side Current: DC Side input current measured at the point of control inside the DC/AC Accessory Inverter.";
CM_ SG_ 2364614910 DCACAssrInvrtr3DCSdPwr "DC/AC Accessory Inverter 3 DC Side Power: Power measured at the DC Side input to the DC/AC Accessory Inverter. ";
CM_ SG_ 2364614910 DCACAssrInvrtr3DCSdVltg "DC/AC Accessory Inverter 3 DC Side Voltage: DC Side input voltage measured at the point of control inside the DC/AC Accessory Inverter.";
CM_ SG_ 2364614910 DCACAssIvt3DCSdNtvtCsssGdVt "DC/AC Accessory Inverter 3 DC Side Negative to Chassis Ground Voltage: The voltage level of the high voltage DC side, as measured by the DC/AC between the negative side of the High Voltage DC Side input and the chassis of the DC/AC enclosure.  This v...";
CM_ BO_ 2364615166 "DC/AC Accessory Inverter 3 Voltage";
CM_ SG_ 2364615166 DCACAssrInvrtr3IgntnVltg "DC/AC Accessory Inverter 3 Ignition Voltage: Ignition voltage supplied to the  DC/AC Accessory Inverter controller.";
CM_ SG_ 2364615166 DCACAssrInvrtr3UnswthdSLIVltg "DC/AC Accessory Inverter 3 Unswitched SLI Voltage: Continuously supplied SLI power to this instance of the DC/AC Accessory Inverter controller.";
CM_ BO_ 2364615678 "DC/AC Accessory Inverter 4 Status 2";
CM_ SG_ 2364615678 DCACAssrInvrtr4DCSdCrrnt "DC/AC Accessory Inverter 4 DC Side Current: DC Side input current measured at the point of control inside the DC/AC Accessory Inverter.";
CM_ SG_ 2364615678 DCACAssrInvrtr4DCSdPwr "DC/AC Accessory Inverter 4 DC Side Power: Power measured at the DC Side input to the DC/AC Accessory Inverter. ";
CM_ SG_ 2364615678 DCACAssrInvrtr4DCSdVltg "DC/AC Accessory Inverter 4 DC Side Voltage: DC Side input voltage measured at the point of control inside the DC/AC Accessory Inverter.";
CM_ SG_ 2364615678 DCACAssIvt4DCSdNtvtCsssGdVt "DC/AC Accessory Inverter 4 DC Side Negative to Chassis Ground Voltage: The voltage level of the high voltage DC side, as measured by the DC/AC between the negative side of the High Voltage DC Side input and the chassis of the DC/AC enclosure.  This v...";
CM_ BO_ 2364615934 "DC/AC Accessory Inverter 4 Voltage";
CM_ SG_ 2364615934 DCACAssrInvrtr4IgntnVltg "DC/AC Accessory Inverter 4 Ignition Voltage: Ignition voltage supplied to the  DC/AC Accessory Inverter controller.";
CM_ SG_ 2364615934 DCACAssrInvrtr4UnswthdSLIVltg "DC/AC Accessory Inverter 4 Unswitched SLI Voltage: Continuously supplied SLI power to this instance of the DC/AC Accessory Inverter controller.";
CM_ BO_ 2364616958 "DC/AC Accessory Inverter 5 Status 2";
CM_ SG_ 2364616958 DCACAssrInvrtr5DCSdCrrnt "DC/AC Accessory Inverter 5 DC Side Current: DC Side input current measured at the point of control inside the DC/AC Accessory Inverter.";
CM_ SG_ 2364616958 DCACAssrInvrtr5DCSdPwr "DC/AC Accessory Inverter 5 DC Side Power: Power measured at the DC Side input to the DC/AC Accessory Inverter. ";
CM_ SG_ 2364616958 DCACAssrInvrtr5DCSdVltg "DC/AC Accessory Inverter 5 DC Side Voltage: DC Side input voltage measured at the point of control inside the DC/AC Accessory Inverter.";
CM_ SG_ 2364616958 DCACAssIvt5DCSdNtvtCsssGdVt "DC/AC Accessory Inverter 5 DC Side Negative to Chassis Ground Voltage: The voltage level of the high voltage DC side, as measured by the DC/AC between the negative side of the High Voltage DC Side input and the chassis of the DC/AC enclosure.  This v...";
CM_ BO_ 2364617214 "DC/AC Accessory Inverter 5 Voltage";
CM_ SG_ 2364617214 DCACAssrInvrtr5IgntnVltg "DC/AC Accessory Inverter 5 Ignition Voltage: Ignition voltage supplied to the  DC/AC Accessory Inverter controller.";
CM_ SG_ 2364617214 DCACAssrInvrtr5UnswthdSLIVltg "DC/AC Accessory Inverter 5 Unswitched SLI Voltage: Continuously supplied SLI power to this instance of the DC/AC Accessory Inverter controller.";
CM_ BO_ 2365296894 "DC/DC Converter 4 Voltage";
CM_ SG_ 2365296894 DCDC4CntrllrInptIgntnVltg "DC/DC 4 Controller Input Ignition Voltage: Ignition voltage (i.e. switched) supplied to the  DC/DC Converter controller.";
CM_ SG_ 2365296894 DCDC4CntrllrInptUnswthdSLIVltg "DC/DC 4 Controller Input Unswitched SLI Voltage: Continuously supplied SLI power to this instance of the DC/DC Converter controller.";
CM_ BO_ 2365297150 "DC/DC Converter 3 Voltage";
CM_ SG_ 2365297150 DCDC3CntrllrInptIgntnVltg "DC/DC 3 Controller Input Ignition Voltage: Ignition voltage (i.e. switched) supplied to the  DC/DC Converter controller.";
CM_ SG_ 2365297150 DCDC3CntrllrInptUnswthdSLIVltg "DC/DC 3 Controller Input Unswitched SLI Voltage: Continuously supplied SLI power to this instance of the DC/DC Converter controller.";
CM_ BO_ 2365297406 "DC/DC Converter 2 Voltage";
CM_ SG_ 2365297406 DCDC2CntrllrInptIgntnVltg "DC/DC 2 Controller Input Ignition Voltage: Ignition voltage (i.e. switched) supplied to the  DC/DC Converter controller.";
CM_ SG_ 2365297406 DCDC2CntrllrInptUnswthdSLIVltg "DC/DC 2 Controller Input Unswitched SLI Voltage: Continuously supplied SLI power to this instance of the DC/DC Converter controller.";
CM_ BO_ 2365297662 "DC/DC Converter 1 Voltage";
CM_ SG_ 2365297662 DCDC1CntrllrInptIgntnVltg "DC/DC 1 Controller Input Ignition Voltage: Ignition voltage (i.e. switched) supplied to the  DC/DC Converter controller.";
CM_ SG_ 2365297662 DCDC1CntrllrInptUnswthdSLIVltg "DC/DC 1 Controller Input Unswitched SLI Voltage: Continuously supplied SLI power to this instance of the DC/DC Converter controller.";
CM_ BO_ 2365299454 "DC/AC Accessory Inverter 1 DC Side Limits ";
CM_ SG_ 2365299454 DCACAssIvt1DCSdCtMLtRqst "DC/AC Accessory Inverter 1 DC Side Current Minimum Limit Request: The minimum allowed DC Side input current requested by a separate device.   Under normal conditions this requested limit would be reflected in SPN 9532.";
CM_ SG_ 2365299454 DCACAssIvt1DCSdCtMxLtRqst "DC/AC Accessory Inverter 1 DC Side Current Maximum Limit Request: The maximum allowed DC Side input current requested by a separate device.   Under normal conditions this requested limit would be reflected in SPN 9226.";
CM_ SG_ 2365299454 DCACAssIvt1DCSdVtMLtRqst "DC/AC Accessory Inverter 1 DC Side Voltage Minimum Limit Request: The minimum allowed DC Side input voltage requested by a separate device.   Under normal conditions this requested limit would be reflected in SPN 9225.";
CM_ SG_ 2365299454 DCACAssIvt1DCSdVtMxLtRqst "DC/AC Accessory Inverter 1 DC Side Voltage Maximum Limit Request: The maximum allowed DC Side input voltage requested by a separate device.   Under normal conditions this requested limit would be reflected in SPN 9531.";
CM_ BO_ 2365299710 "DC/AC Accessory Inverter 1 AC Side Limits ";
CM_ SG_ 2365299710 DCACAssIvt1ACSdRMSCtMxLtRqst "DC/AC Accessory Inverter 1 AC Side RMS Current Maximum Limit Request: The maximum allowed AC Side output RMS line current requested by a separate device.   Under normal conditions this requested limit would be reflected in SPN 9228.";
CM_ SG_ 2365299710 DCACAssIvt1ACSdRMSVtMxLtRqst "DC/AC Accessory Inverter 1 AC Side RMS Voltage Maximum Limit Request: The maximum allowed AC Side line to line RMS voltage requested by a separate device.   Under normal conditions this requested limit would be reflected in SPN 9227.";
CM_ SG_ 2365299710 DCACAssrInvrtr1ACSdDfltFrqnRqst "DC/AC Accessory Inverter 1 AC Side Default Frequency Request: This setting may be used to set a default frequency command for when communication has been lost with the controlling device.  When set to Not Available (FFh), no default setting is provid...";
CM_ BO_ 2365300734 "DC/AC Accessory Inverter 2 DC Side Limits ";
CM_ SG_ 2365300734 DCACAssIvt2DCSdCtMLtRqst "DC/AC Accessory Inverter 2 DC Side Current Minimum Limit Request: The minimum allowed DC Side input current requested by a separate device.   Under normal conditions this requested limit would be reflected in SPN 9538.";
CM_ SG_ 2365300734 DCACAssIvt2DCSdCtMxLtRqst "DC/AC Accessory Inverter 2 DC Side Current Maximum Limit Request: The maximum allowed DC Side input current requested by a separate device.   Under normal conditions this requested limit would be reflected in SPN 9256.";
CM_ SG_ 2365300734 DCACAssIvt2DCSdVtMLtRqst "DC/AC Accessory Inverter 2 DC Side Voltage Minimum Limit Request: The minimum allowed DC Side input voltage requested by a separate device.   Under normal conditions this requested limit would be reflected in SPN 9255.";
CM_ SG_ 2365300734 DCACAssIvt2DCSdVtMxLtRqst "DC/AC Accessory Inverter 2 DC Side Voltage Maximum Limit Request: The maximum allowed DC Side input voltage requested by a separate device.   Under normal conditions this requested limit would be reflected in SPN 9537.";
CM_ BO_ 2365300990 "DC/AC Accessory Inverter 2 AC Side Limits ";
CM_ SG_ 2365300990 DCACAssIvt2ACSdRMSCtMxLtRqst "DC/AC Accessory Inverter 2 AC Side RMS Current Maximum Limit Request: The maximum allowed AC Side output RMS line current requested by a separate device.   Under normal conditions this requested limit would be reflected in SPN 9258.";
CM_ SG_ 2365300990 DCACAssIvt2ACSdRMSVtMxLtRqst "DC/AC Accessory Inverter 2 AC Side RMS Voltage Maximum Limit Request: The maximum allowed AC Side line to line RMS voltage requested by a separate device.   Under normal conditions this requested limit would be reflected in SPN 9257.";
CM_ SG_ 2365300990 DCACAssrInvrtr2ACSdDfltFrqnRqst "DC/AC Accessory Inverter 2 AC Side Default Frequency Request: This setting may be used to set a default frequency command for when communication has been lost with the controlling device.  When set to Not Available (FFh), no default setting is provid...";
CM_ BO_ 2365302014 "DC/AC Accessory Inverter 3 DC Side Limits ";
CM_ SG_ 2365302014 DCACAssIvt3DCSdCtMLtRqst "DC/AC Accessory Inverter 3 DC Side Current Minimum Limit Request: The minimum allowed DC Side input current requested by a separate device.   Under normal conditions this requested limit would be reflected in SPN 9544.";
CM_ SG_ 2365302014 DCACAssIvt3DCSdCtMxLtRqst "DC/AC Accessory Inverter 3 DC Side Current Maximum Limit Request: The maximum allowed DC Side input current requested by a separate device.   Under normal conditions this requested limit would be reflected in SPN 9286.";
CM_ SG_ 2365302014 DCACAssIvt3DCSdVtMLtRqst "DC/AC Accessory Inverter 3 DC Side Voltage Minimum Limit Request: The minimum allowed DC Side input voltage requested by a separate device.   Under normal conditions this requested limit would be reflected in SPN 9285.";
CM_ SG_ 2365302014 DCACAssIvt3DCSdVtMxLtRqst "DC/AC Accessory Inverter 3 DC Side Voltage Maximum Limit Request: The maximum allowed DC Side input voltage requested by a separate device.   Under normal conditions this requested limit would be reflected in SPN 9543.";
CM_ BO_ 2365302270 "DC/AC Accessory Inverter 3 AC Side Limits ";
CM_ SG_ 2365302270 DCACAssIvt3ACSdRMSCtMxLtRqst "DC/AC Accessory Inverter 3 AC Side RMS Current Maximum Limit Request: The maximum allowed AC Side output RMS line current requested by a separate device.   Under normal conditions this requested limit would be reflected in SPN 9288.";
CM_ SG_ 2365302270 DCACAssIvt3ACSdRMSVtMxLtRqst "DC/AC Accessory Inverter 3 AC Side RMS Voltage Maximum Limit Request: The maximum allowed AC Side line to line RMS voltage requested by a separate device.   Under normal conditions this requested limit would be reflected in SPN 9287.";
CM_ SG_ 2365302270 DCACAssrInvrtr3ACSdDfltFrqnRqst "DC/AC Accessory Inverter 3 AC Side Default Frequency Request: This setting may be used to set a default frequency command for when communication has been lost with the controlling device.  When set to Not Available (FFh), no default setting is provid...";
CM_ BO_ 2365303294 "DC/AC Accessory Inverter 4 DC Side Limits ";
CM_ SG_ 2365303294 DCACAssIvt4DCSdCtMLtRqst "DC/AC Accessory Inverter 4 DC Side Current Minimum Limit Request: The minimum allowed DC Side input current requested by a separate device.   Under normal conditions this requested limit would be reflected in SPN 9550.";
CM_ SG_ 2365303294 DCACAssIvt4DCSdCtMxLtRqst "DC/AC Accessory Inverter 4 DC Side Current Maximum Limit Request: The maximum allowed DC Side input current requested by a separate device.   Under normal conditions this requested limit would be reflected in SPN 9316.";
CM_ SG_ 2365303294 DCACAssIvt4DCSdVtMLtRqst "DC/AC Accessory Inverter 4 DC Side Voltage Minimum Limit Request: The minimum allowed DC Side input voltage requested by a separate device.   Under normal conditions this requested limit would be reflected in SPN 9315.";
CM_ SG_ 2365303294 DCACAssIvt4DCSdVtMxLtRqst "DC/AC Accessory Inverter 4 DC Side Voltage Maximum Limit Request: The maximum allowed DC Side input voltage requested by a separate device.   Under normal conditions this requested limit would be reflected in SPN 9549.";
CM_ BO_ 2365303550 "DC/AC Accessory Inverter 4 AC Side Limits ";
CM_ SG_ 2365303550 DCACAssIvt4ACSdRMSCtMxLtRqst "DC/AC Accessory Inverter 4 AC Side RMS Current Maximum Limit Request: The maximum allowed AC Side output RMS line current requested by a separate device.   Under normal conditions this requested limit would be reflected in SPN 9318.";
CM_ SG_ 2365303550 DCACAssIvt4ACSdRMSVtMxLtRqst "DC/AC Accessory Inverter 4 AC Side RMS Voltage Maximum Limit Request: The maximum allowed AC Side line to line RMS voltage requested by a separate device.   Under normal conditions this requested limit would be reflected in SPN 9317.";
CM_ SG_ 2365303550 DCACAssrInvrtr4ACSdDfltFrqnRqst "DC/AC Accessory Inverter 4 AC Side Default Frequency Request: This setting may be used to set a default frequency command for when communication has been lost with the controlling device.  When set to Not Available (FFh), no default setting is provid...";
CM_ BO_ 2365304574 "DC/AC Accessory Inverter 5 DC Side Limits ";
CM_ SG_ 2365304574 DCACAssIvt5DCSdCtMLtRqst "DC/AC Accessory Inverter 5 DC Side Current Minimum Limit Request: The minimum allowed DC Side input current requested by a separate device.   Under normal conditions this requested limit would be reflected in SPN 9556.";
CM_ SG_ 2365304574 DCACAssIvt5DCSdCtMxLtRqst "DC/AC Accessory Inverter 5 DC Side Current Maximum Limit Request: The maximum allowed DC Side input current requested by a separate device.   Under normal conditions this requested limit would be reflected in SPN 9362.";
CM_ SG_ 2365304574 DCACAssIvt5DCSdVtMLtRqst "DC/AC Accessory Inverter 5 DC Side Voltage Minimum Limit Request: The minimum allowed DC Side input voltage requested by a separate device.   Under normal conditions this requested limit would be reflected in SPN 9361.";
CM_ SG_ 2365304574 DCACAssIvt5DCSdVtMxLtRqst "DC/AC Accessory Inverter 5 DC Side Voltage Maximum Limit Request: The maximum allowed DC Side input voltage requested by a separate device.   Under normal conditions this requested limit would be reflected in SPN 9555.";
CM_ BO_ 2365304830 "DC/AC Accessory Inverter 5 AC Side Limits ";
CM_ SG_ 2365304830 DCACAssIvt5ACSdRMSCtMxLtRqst "DC/AC Accessory Inverter 5 AC Side RMS Current Maximum Limit Request: The maximum allowed AC Side output RMS line current requested by a separate device.   Under normal conditions this requested limit would be reflected in SPN 9364.";
CM_ SG_ 2365304830 DCACAssIvt5ACSdRMSVtMxLtRqst "DC/AC Accessory Inverter 5 AC Side RMS Voltage Maximum Limit Request: The maximum allowed AC Side line to line RMS voltage requested by a separate device.   Under normal conditions this requested limit would be reflected in SPN 9363.";
CM_ SG_ 2365304830 DCACAssrInvrtr5ACSdDfltFrqnRqst "DC/AC Accessory Inverter 5 AC Side Default Frequency Request: This setting may be used to set a default frequency command for when communication has been lost with the controlling device.  When set to Not Available (FFh), no default setting is provid...";
CM_ BO_ 2365307646 "DC/DC Converter 4 SLI Battery Limits";
CM_ SG_ 2365307646 DCDC4SLIBttrTmprtrMxmmLmtRqst "DC/DC 4 SLI Battery Temperature Maximum Limit Request: The maximum allowed SLI Battery Temperature requested by a separate device.  ";
CM_ SG_ 2365307646 DCDC4SLIBttTCCtMxLtRqst "DC/DC 4 SLI Battery Terminal Charge Current Maximum Limit Request: The maximum allowed SLI Battery charging current (at the battery terminals) requested by a separate device.  ";
CM_ SG_ 2365307646 DCDC4SLIBttTVtMxLtRqst "DC/DC 4 SLI Battery Terminal Voltage Maximum Limit Request: The maximum allowed SLI Battery Voltage (at the battery terminals) requested by a separate system device.  ";
CM_ BO_ 2365307902 "DC/DC Converter 4 Temperatures";
CM_ SG_ 2365307902 DCDC4CnvrtrEltrnFltrTmprtr "DC/DC 4 Converter Electronic Filter Temperature: Parameter indicating the temperature of the electronic components that make up the DC/DC Converter filter.";
CM_ SG_ 2365307902 DCDC4ConverterTemperature "DC/DC 4 Converter Temperature: Parameter indicating the temperature of the DC/DC Converter (e.g, controller, circuit board, enclosure).";
CM_ SG_ 2365307902 DCDC4CoolantInTemperature "DC/DC 4 Coolant  In Temperature: Parameter indicating the temperature of the DC/DC Converter Coolant measured at the input of the converter";
CM_ SG_ 2365307902 DCDC4CoolantOutTemperature "DC/DC 4 Coolant Out Temperature: Parameter indicating the temperature of the DC/DC Converter Coolant measured at the output of the converter";
CM_ SG_ 2365307902 DCDC4PwrEltrnsTmprtr "DC/DC 4 Power Electronics Temperature: Parameter indicating the temperature of the DC/DC Converter power electronics components (e.g, switch or heatsink).";
CM_ BO_ 2365308158 "DC/DC Converter 4 Low Side Limits";
CM_ SG_ 2365308158 DCDC4LwSdCrrntMxmmLmtRqst "DC/DC 4 Low Side Current Maximum Limit Request: The maximum allowed low side current requested by a separate device.   Under normal conditions this requested limit would be reflected in SPN 9039.";
CM_ SG_ 2365308158 DCDC4LwSdVltgMnmmLmtRqst "DC/DC 4 Low Side Voltage Minimum Limit Request: The minimum allowed low side voltage requested by a separate device.  Under normal conditions this requested limit would be reflected in SPN 9037.";
CM_ SG_ 2365308158 DCDC4LwSdVltgMxmmLmtRqst "DC/DC 4 Low Side Voltage Maximum Limit Request: The maximum allowed low side voltage requested by a separate device.   Under normal conditions this requested limit would be reflected in SPN 9038.";
CM_ BO_ 2365308414 "DC/DC Converter 4 High Side Limits";
CM_ SG_ 2365308414 DCDC4HghSdCrrntMxmmLmtRqst "DC/DC 4 High Side Current Maximum Limit Request: The maximum allowed high side current requested by a separate device.   Under normal conditions this requested limit would be reflected in SPN 9036.";
CM_ SG_ 2365308414 DCDC4HghSdVltgMnmmLmtRqst "DC/DC 4 High Side Voltage Minimum Limit Request: The minimum allowed high side voltage requested by a separate device.   Under normal conditions this requested limit would be reflected in SPN 9034.";
CM_ SG_ 2365308414 DCDC4HghSdVltgMxmmLmtRqst "DC/DC 4 High Side Voltage Maximum Limit Request: The maximum allowed high side voltage requested by a separate device.  Under normal conditions this requested limit would be reflected in SPN 9035.";
CM_ BO_ 2365309182 "DC/DC Converter 3 SLI Battery Limits";
CM_ SG_ 2365309182 DCDC3SLIBttrTmprtrMxmmLmtRqst "DC/DC 3 SLI Battery Temperature Maximum Limit Request: The maximum allowed SLI Battery Temperature requested by a separate device.  ";
CM_ SG_ 2365309182 DCDC3SLIBttTCCtMxLtRqst "DC/DC 3 SLI Battery Terminal Charge Current Maximum Limit Request: The maximum allowed SLI Battery charging current (at the battery terminals) requested by a separate device.  ";
CM_ SG_ 2365309182 DCDC3SLIBttTVtMxLtRqst "DC/DC 3 SLI Battery Terminal Voltage Maximum Limit Request: The maximum allowed SLI Battery Voltage (at the battery terminals) requested by a separate system device.  ";
CM_ BO_ 2365309438 "DC/DC Converter 3 Temperatures";
CM_ SG_ 2365309438 DCDC3CnvrtrEltrnFltrTmprtr "DC/DC 3 Converter Electronic Filter Temperature: Parameter indicating the temperature of the electronic components that make up the DC/DC Converter filter.";
CM_ SG_ 2365309438 DCDC3ConverterTemperature "DC/DC 3 Converter Temperature: Parameter indicating the temperature of the DC/DC Converter (e.g, controller, circuit board, enclosure).";
CM_ SG_ 2365309438 DCDC3CoolantInTemperature "DC/DC 3 Coolant  In Temperature: Parameter indicating the temperature of the DC/DC Converter Coolant measured at the input of the converter";
CM_ SG_ 2365309438 DCDC3CoolantOutTemperature "DC/DC 3 Coolant Out Temperature: Parameter indicating the temperature of the DC/DC Converter Coolant measured at the output of the converter";
CM_ SG_ 2365309438 DCDC3PwrEltrnsTmprtr "DC/DC 3 Power Electronics Temperature: Parameter indicating the temperature of the DC/DC Converter power electronics components (e.g, switch or heatsink).";
CM_ BO_ 2365309694 "DC/DC Converter 3 Low Side Limits";
CM_ SG_ 2365309694 DCDC3LwSdCrrntMxmmLmtRqst "DC/DC 3 Low Side Current Maximum Limit Request: The maximum allowed low side current requested by a separate device.   Under normal conditions this requested limit would be reflected in SPN 8984.";
CM_ SG_ 2365309694 DCDC3LwSdVltgMnmmLmtRqst "DC/DC 3 Low Side Voltage Minimum Limit Request: The minimum allowed low side voltage requested by a separate device.   Under normal conditions this requested limit would be reflected in SPN 8982.";
CM_ SG_ 2365309694 DCDC3LwSdVltgMxmmLmtRqst "DC/DC 3 Low Side Voltage Maximum Limit Request: The maximum allowed low side voltage requested by a separate device.   Under normal conditions this requested limit would be reflected in SPN 8983.";
CM_ BO_ 2365309950 "DC/DC Converter 3 High Side Limits";
CM_ SG_ 2365309950 DCDC3HghSdCrrntMxmmLmtRqst "DC/DC 3 High Side Current Maximum Limit Request: The maximum allowed high side current requested by a separate device.   Under normal conditions this requested limit would be reflected in  SPN 8981.";
CM_ SG_ 2365309950 DCDC3HghSdVltgMnmmLmtRqst "DC/DC 3 High Side Voltage Minimum Limit Request: The minimum allowed high side voltage requested by a separate device.   Under normal conditions this requested limit would be reflected in  SPN 8979.";
CM_ SG_ 2365309950 DCDC3HghSdVltgMxmmLmtRqst "DC/DC 3 High Side Voltage Maximum Limit Request: The maximum allowed high side voltage requested by a separate device.   Under normal conditions this requested limit would be reflected in  SPN 8980.";
CM_ BO_ 2365310718 "DC/DC Converter 2 SLI Battery Limits";
CM_ SG_ 2365310718 DCDC2SLIBttrTmprtrMxmmLmtRqst "DC/DC 2 SLI Battery Temperature Maximum Limit Request: The maximum allowed SLI Battery Temperature requested by a separate device.  ";
CM_ SG_ 2365310718 DCDC2SLIBttTCCtMxLtRqst "DC/DC 2 SLI Battery Terminal Charge Current Maximum Limit Request: The maximum allowed SLI Battery charging current (at the battery terminals) requested by a separate device.  ";
CM_ SG_ 2365310718 DCDC2SLIBttTVtMxLtRqst "DC/DC 2 SLI Battery Terminal Voltage Maximum Limit Request: The maximum allowed SLI Battery Voltage (at the battery terminals) requested by a separate system device.  ";
CM_ BO_ 2365310974 "DC/DC Converter 2 Temperatures";
CM_ SG_ 2365310974 DCDC2CnvrtrEltrnFltrTmprtr "DC/DC 2 Converter Electronic Filter Temperature: Parameter indicating the temperature of the electronic components that make up the DC/DC Converter filter.";
CM_ SG_ 2365310974 DCDC2ConverterTemperature "DC/DC 2 Converter Temperature: Parameter indicating the temperature of the DC/DC Converter (e.g, controller, circuit board, enclosure).";
CM_ SG_ 2365310974 DCDC2CoolantInTemperature "DC/DC 2 Coolant  In Temperature: Parameter indicating the temperature of the DC/DC Converter Coolant measured at the input of the converter";
CM_ SG_ 2365310974 DCDC2CoolantOutTemperature "DC/DC 2 Coolant Out Temperature: Parameter indicating the temperature of the DC/DC Converter Coolant measured at the output of the converter";
CM_ SG_ 2365310974 DCDC2PwrEltrnsTmprtr "DC/DC 2 Power Electronics Temperature: Parameter indicating the temperature of the DC/DC Converter power electronics components (e.g, switch or heatsink).";
CM_ BO_ 2365311230 "DC/DC Converter 2 Low Side Limits";
CM_ SG_ 2365311230 DCDC2LwSdCrrntMxmmLmtRqst "DC/DC 2 Low Side Current Maximum Limit Request: The maximum allowed low side current requested by a separate device.  Under normal conditions this requested limit would be reflected in SPN 8929.";
CM_ SG_ 2365311230 DCDC2LwSdVltgMnmmLmtRqst "DC/DC 2 Low Side Voltage Minimum Limit Request: The minimum allowed low side voltage requested by a separate device.  Under normal conditions this requested limit would be reflected in SPN 8927.";
CM_ SG_ 2365311230 DCDC2LwSdVltgMxmmLmtRqst "DC/DC 2 Low Side Voltage Maximum Limit Request: The maximum allowed low side voltage requested by a separate device.  Under normal conditions this requested limit would be reflected in SPN 8928.";
CM_ BO_ 2365311486 "DC/DC Converter 2 High Side Limits";
CM_ SG_ 2365311486 DCDC2HghSdCrrntMxmmLmtRqst "DC/DC 2 High Side Current Maximum Limit Request: The maximum allowed high side current requested by a separate device. Under normal conditions this requested limit would be reflected in SPN 8926.";
CM_ SG_ 2365311486 DCDC2HghSdVltgMnmmLmtRqst "DC/DC 2 High Side Voltage Minimum Limit Request: The minimum allowed high side voltage requested by a separate device. Under normal conditions this requested limit would be reflected in SPN 8924.";
CM_ SG_ 2365311486 DCDC2HghSdVltgMxmmLmtRqst "DC/DC 2 High Side Voltage Maximum Limit Request: The maximum allowed high side voltage requested by a separate device.  Under normal conditions this requested limit would be reflected in SPN 8925.";
CM_ BO_ 2365313534 "DC/DC Converter 1 SLI Battery Limits";
CM_ SG_ 2365313534 DCDC1SLIBttrTmprtrMxmmLmtRqst "DC/DC 1 SLI Battery Temperature Maximum Limit Request: The maximum allowed SLI Battery Temperature requested by a separate device.  ";
CM_ SG_ 2365313534 DCDC1SLIBttTCCtMxLtRqst "DC/DC 1 SLI Battery Terminal Charge Current Maximum Limit Request: The maximum allowed SLI Battery charging current (at the battery terminals) requested by a separate device.  ";
CM_ SG_ 2365313534 DCDC1SLIBttTVtMxLtRqst "DC/DC 1 SLI Battery Terminal Voltage Maximum Limit Request: The maximum allowed SLI Battery Voltage (at the battery terminals) requested by a separate system device.  ";
CM_ BO_ 2365315326 "DC/DC Converter 1 Temperatures";
CM_ SG_ 2365315326 DCDC1CnvrtrEltrnFltrTmprtr "DC/DC 1 Converter Electronic Filter Temperature: Parameter indicating the temperature of the electronic components that make up the DC/DC Converter filter.";
CM_ SG_ 2365315326 DCDC1ConverterTemperature "DC/DC 1 Converter Temperature: Parameter indicating the temperature of the DC/DC Converter (e.g, controller, circuit board, enclosure).";
CM_ SG_ 2365315326 DCDC1CoolantInTemperature "DC/DC 1 Coolant  In Temperature: Parameter indicating the temperature of the DC/DC Converter Coolant measured at the input of the converter";
CM_ SG_ 2365315326 DCDC1CoolantOutTemperature "DC/DC 1 Coolant Out Temperature: Parameter indicating the temperature of the DC/DC Converter Coolant measured at the output of the converter";
CM_ SG_ 2365315326 DCDC1PwrEltrnsTmprtr "DC/DC 1 Power Electronics Temperature: Parameter indicating the temperature of the DC/DC Converter power electronics components (e.g, switch or heatsink).";
CM_ BO_ 2365315582 "DC/DC Converter 1 Low Side Limits";
CM_ SG_ 2365315582 DCDC1LwSdCrrntMxmmLmtRqst "DC/DC 1 Low Side Current Maximum Limit Request: The maximum allowed low side current requested by a separate device.   Under normal conditions this requested limit would be reflected in SPN 8829.";
CM_ SG_ 2365315582 DCDC1LwSdVltgMnmmLmtRqst "DC/DC 1 Low Side Voltage Minimum Limit Request: The minimum allowed low side voltage requested by a separate device.   Under normal conditions this requested limit would be reflected in SPN 8827.";
CM_ SG_ 2365315582 DCDC1LwSdVltgMxmmLmtRqst "DC/DC 1 Low Side Voltage Maximum Limit Request: The maximum allowed low side voltage requested by a separate device.   Under normal conditions this requested limit would be reflected in SPN 8828.";
CM_ BO_ 2365315838 "DC/DC Converter 1 High Side Limits";
CM_ SG_ 2365315838 DCDC1HghSdCrrntMxmmLmtRqst "DC/DC 1 High Side Current Maximum Limit Request: The maximum allowed high side current requested by a separate device.   Under normal conditions this requested limit would be reflected in SPN 8826.";
CM_ SG_ 2365315838 DCDC1HghSdVltgMnmmLmtRqst "DC/DC 1 High Side Voltage Minimum Limit Request: The minimum allowed high side voltage requested by a separate device.   Under normal conditions this requested limit would be reflected in SPN 8824.";
CM_ SG_ 2365315838 DCDC1HghSdVltgMxmmLmtRqst "DC/DC 1 High Side Voltage Maximum Limit Request: The maximum allowed high side voltage requested by a separate device.   Under normal conditions this requested limit would be reflected in SPN 8825.";
CM_ BO_ 2365318910 "High Voltage Energy Storage System Fan Commands";
CM_ SG_ 2365318910 HVESSFanEnableCommand "HVESS Fan Enable Command: Enable and direction command to this HVES fan.00b = Fan Off01b = Fan On Normal/Default Direction10b = Fan On Reverse Direction11b = Don't Care/Take no action";
CM_ SG_ 2365318910 HVESSFanPowerHold "HVESS Fan Power Hold: Command to allow this HVES fan to remain alive independently of the electrical enable input to the fan.  For example, this could allow continued device operation after the keyswitch has turned off.00b = Power Hold Disabled01b = ...";
CM_ SG_ 2365318910 HVESSFanSpeedCommand "HVESS Fan Speed Command: Speed command to this HVES fan.Note: Both SPN 8386 (HVESS Fan Speed Command) and SPN 8387 (HVESS Fan Percent Speed Command) cannot be used at the same time.  Always set the unused speed command to Not Available.  If both comm...";
CM_ SG_ 2365318910 HVESSFanPercentSpeedCommand "HVESS Fan Percent Speed Command: Speed command to this HVES fan in percentage of maximum speed.Note: Both SPN 8386 (HVESS Fan Speed Command) and SPN 8387 (HVESS Fan Percent Speed Command) cannot be used at the same time.  Always set the unused speed ...";
CM_ SG_ 2365318910 HVESSFanInstance1 "HVESS Fan Instance 1: Indicates the HVES Fan Instance that is being commanded.  Multiple instances can be controlled with the same command PG by setting each unique instance parameter to 0b.0b = Command applied to this Fan Instance1b = No Command app...";
CM_ SG_ 2365318910 HVESSFanInstance2 "HVESS Fan Instance 2: Indicates the HVES Fan Instance that is being commanded.  Multiple instances can be controlled with the same command PG by setting each unique instance parameter to 0b.0b = Command applied to this Fan Instance1b = No Command app...";
CM_ SG_ 2365318910 HVESSFanInstance3 "HVESS Fan Instance 3: Indicates the HVES Fan Instance that is being commanded.  Multiple instances can be controlled with the same command PG by setting each unique instance parameter to 0b.0b = Command applied to this Fan Instance1b = No Command app...";
CM_ SG_ 2365318910 HVESSFanInstance4 "HVESS Fan Instance 4: Indicates the HVES Fan Instance that is being commanded.  Multiple instances can be controlled with the same command PG by setting each unique instance parameter to 0b.0b = Command applied to this Fan Instance1b = No Command app...";
CM_ SG_ 2365318910 HVESSFanInstance5 "HVESS Fan Instance 5: Indicates the HVES Fan Instance that is being commanded.  Multiple instances can be controlled with the same command PG by setting each unique instance parameter to 0b.0b = Command applied to this Fan Instance1b = No Command app...";
CM_ SG_ 2365318910 HVESSFanInstance6 "HVESS Fan Instance 6: Indicates the HVES Fan Instance that is being commanded.  Multiple instances can be controlled with the same command PG by setting each unique instance parameter to 0b.0b = Command applied to this Fan Instance1b = No Command app...";
CM_ SG_ 2365318910 HVESSFanInstance7 "HVESS Fan Instance 7: Indicates the HVES Fan Instance that is being commanded.  Multiple instances can be controlled with the same command PG by setting each unique instance parameter to 0b.0b = Command applied to this Fan Instance1b = No Command app...";
CM_ SG_ 2365318910 HVESSFanInstance8 "HVESS Fan Instance 8: Indicates the HVES Fan Instance that is being commanded.  Multiple instances can be controlled with the same command PG by setting each unique instance parameter to 0b.0b = Command applied to this Fan Instance1b = No Command app...";
CM_ SG_ 2365318910 HVESSFanInstance9 "HVESS Fan Instance 9: Indicates the HVES Fan Instance that is being commanded.  Multiple instances can be controlled with the same command PG by setting each unique instance parameter to 0b.0b = Command applied to this Fan Instance1b = No Command app...";
CM_ SG_ 2365318910 HVESSFanInstance10 "HVESS Fan Instance 10: Indicates the HVES Fan Instance that is being commanded.  Multiple instances can be controlled with the same command PG by setting each unique instance parameter to 0b.0b = Command applied to this Fan Instance1b = No Command ap...";
CM_ SG_ 2365318910 HVESSFanInstance11 "HVESS Fan Instance 11: Indicates the HVES Fan Instance that is being commanded.  Multiple instances can be controlled with the same command PG by setting each unique instance parameter to 0b.0b = Command applied to this Fan Instance1b = No Command ap...";
CM_ SG_ 2365318910 HVESSFanInstance12 "HVESS Fan Instance 12: Indicates the HVES Fan Instance that is being commanded.  Multiple instances can be controlled with the same command PG by setting each unique instance parameter to 0b.0b = Command applied to this Fan Instance1b = No Command ap...";
CM_ SG_ 2365318910 HVESSFanInstance13 "HVESS Fan Instance 13: Indicates the HVES Fan Instance that is being commanded.  Multiple instances can be controlled with the same command PG by setting each unique instance parameter to 0b.0b = Command applied to this Fan Instance1b = No Command ap...";
CM_ SG_ 2365318910 HVESSFanInstance14 "HVESS Fan Instance 14: Indicates the HVES Fan Instance that is being commanded.  Multiple instances can be controlled with the same command PG by setting each unique instance parameter to 0b.0b = Command applied to this Fan Instance1b = No Command ap...";
CM_ SG_ 2365318910 HVESSFanInstance15 "HVESS Fan Instance 15: Indicates the HVES Fan Instance that is being commanded.  Multiple instances can be controlled with the same command PG by setting each unique instance parameter to 0b.0b = Command applied to this Fan Instance1b = No Command ap...";
CM_ BO_ 2365322238 "Cruise Control / Vehicle Speed 5";
CM_ SG_ 2365322238 DirectionalVehicleSpeed "Directional Vehicle Speed: The velocity and direction of the vehicle. Positive values are used for forward vehicle motion, negative values for reverse vehicle motion.  This SP is intended for control purposes where vehicle direction is required.  It ...";
CM_ BO_ 2365346302 "Air Suspension Control 7";
CM_ SG_ 2365346302 LiftAxle1Status "Lift Axle 1 Status: Indicates the status of a tag axle 1.  Numbering of lift/tag axles starts at front axle.  SPN 1743 may be used if less detail is acceptable.000b = Down (tag axle is laden)001b = Unloading (load is being transferred from the tag ax...";
CM_ SG_ 2365346302 LiftAxle2Status "Lift Axle 2 Status: Indicates the status of a tag axle 2.  Numbering of lift/tag axles starts at front axle.  SPN 1822 may be used if less detail is acceptable.000b = Down (tag axle is laden)001b = Unloading (load is being transferred from the tag ax...";
CM_ SG_ 2365346302 LiftAxle3Status "Lift Axle 3 Status: Indicates the status of a tag axle 3. Numbering of lift/tag axles starts at front axle.000b = Down (tag axle is laden)001b = Unloading (load is being transferred from the tag axle)010b = Lifting (tag axle is moving up)011b = Up (t...";
CM_ SG_ 2365346302 LiftAxle4Status "Lift Axle 4 Status: Indicates the status of a tag axle 4. Numbering of lift/tag axles starts at front axle.000b = Down (tag axle is laden)001b = Unloading (load is being transferred from the tag axle)010b = Lifting (tag axle is moving up)011b = Up (t...";
CM_ BO_ 2365348350 "Engine Load Sharing Information";
CM_ SG_ 2365348350 EngineLoadShareStatus "Engine Load Share Status: This signal indicates that the status of an engine load sharing feature.0000b = Offline0001b = Master0010b = Slave0011b = Loading0100b = Unloading0101b to 1101b = Reserved1110b = Error1111b = Unavailable";
CM_ SG_ 2365348350 EngineUnloadStatus "Engine Unload Status: This signal indicates the status of an external request to unload the engine, such as the external unload request switch.00b = Not Requested01b = Requested10b = Error11b = Not Available";
CM_ BO_ 2365363710 "Engine Cylinder Pressure Monitor Status Information";
CM_ SG_ 2365363710 EngnClndrPrssrMntr1PrlmnrFMI "Engine Cylinder Pressure Monitor 1 Preliminary FMI: Used to identify the applicable J1939-73 FMI detected in the Engine Cylinder Pressure Monitor 1. In the case of multiple failures the most severe is communicated.A value of 31 is sent to indicate th...";
CM_ SG_ 2365363710 EngnClndrPrssrMntr2PrlmnrFMI "Engine Cylinder Pressure Monitor 2 Preliminary FMI: Used to identify the applicable J1939-73 FMI detected in the Engine Cylinder Pressure Monitor 2.  In the case of multiple failures the most severe is communicated.A value of 31 is sent to indicate t...";
CM_ BO_ 2365374206 "Electronic Transmission Controller #9";
CM_ SG_ 2365374206 DlClthTrnsmssnCrrntPrsltnGr "Dual Clutch Transmission Current Pre-selection Gear: The gear currently engaged on the non-engaged clutch of a dual clutch transmission (DCT) or the last gear engaged on the non-engaged clutch while the transmission is in the process of pre-selecting...";
CM_ SG_ 2365374206 DlClthTrnsmssnInptShft1Spd "Dual Clutch Transmission Input Shaft 1 Speed: Rotational velocity of the primary shaft transferring power through clutch 1 into the dual clutch transmission (DCT).";
CM_ SG_ 2365374206 DlClthTrnsmssnInptShft2Spd "Dual Clutch Transmission Input Shaft 2 Speed: Rotational velocity of the primary shaft transferring power through clutch 2 into the dual clutch transmission (DCT).";
CM_ SG_ 2365374206 DlClthTrnsmssnSltdPrsltnGr "Dual Clutch Transmission Selected Pre-selection Gear: The gear that the transmission will attempt to achieve during the current pre-selection event (shifting to a new gear on the non-engaged clutch of a dual clutch transmission (DCT)).";
CM_ BO_ 2365393662 "Aftertreatment 2 Outlet Gas NOx Sensor Correction Data 2";
CM_ SG_ 2365393662 Aftrtrtmnt2OtltCrrtdNOx "Aftertreatment 2 Outlet Corrected NOx: The corrected outlet NOx value  for aftertreatment 2 shall include all learned adaptions and offsets that are used to adjust the raw signal.2016 MY and later engines with NOx sensors may be required to output a ...";
CM_ SG_ 2365393662 Aftrtrtmnt2OtltNOxSnsrNH3Crrtn "Aftertreatment 2 Outlet NOx Sensor NH3 Correction: Correction of NH3 at the NOx-signal to correct (recalculate) sensor signal on the Engine ECU side.";
CM_ SG_ 2365393662 Aftrtrtmnt2OtltNOxSnsrNO2Crrtn "Aftertreatment 2 Outlet NOx Sensor NO2 Correction: Correction of NO2 at the NOx-signal to correct (recalculate) sensor signal on the Engine ECU side.";
CM_ SG_ 2365393662 Atttt2OttNOxSsNOxPssCt "Aftertreatment 2 Outlet NOx Sensor NOx Pressure Correction: Correction of pressure NOx-signal to correct (recalculate) sensor signal on the Engine ECU side.";
CM_ SG_ 2365393662 Atttt2OttNOxSsO2PssCt "Aftertreatment 2 Outlet NOx Sensor O2 Pressure Correction: Correction of pressure Lambda-signal to correct (recalculate) sensor signal on the Engine ECU side.";
CM_ SG_ 2365393662 Atttt2OttNOxSsSdssFRst "Aftertreatment 2 Outlet NOx Sensor Self-diagnosis Final Result: Self-diagnosis result for NOx sensor ATO2 (Aftertreatment Outlet Bank 2) as a ratio of detected value to reference value defined by supplier.This result is used to determine if the signa...";
CM_ BO_ 2365393918 "Aftertreatment 2 Outlet Gas NOx Sensor Correction Data 1";
CM_ SG_ 2365393918 Aftrtrtmnt2OtltNOxSnsrHtrRt "Aftertreatment 2 Outlet NOx Sensor Heater Ratio: Heater ratio to determine temperature at sensor tip.";
CM_ SG_ 2365393918 Aftrtrtmnt2OtltNOxSnsrOprtnHrs "Aftertreatment 2 Outlet NOx Sensor Operation Hours: Counted hours that the NOx-sensor was operated with status dewpoint reached";
CM_ SG_ 2365393918 Atttt2OttNOxSsNwptdvtNOxG "Aftertreatment 2 Outlet NOx Sensor New part deviation NOx Gain: New part deviation NOx_Gain to correct (recalculate) sensor signal on the Engine ECU side.";
CM_ SG_ 2365393918 Atttt2OttNOxSsNwptdvtNOxOst "Aftertreatment 2 Outlet NOx Sensor New part deviation NOx Offset: New part deviation NOx_Offset to correct (recalculate) sensor signal on the Engine ECU side.";
CM_ BO_ 2365394174 "Aftertreatment 2 Intake Gas NOx Sensor Correction Data 2";
CM_ SG_ 2365394174 EngineExhaust2CorrectedNox "Engine Exhaust 2 Corrected Nox: The corrected intake Selective Catalytic Reduction NOx value for aftertreatment 2 shall include all learned adaptions and offsets that are used to adjust the raw signal.  This sensor is located at the intake of the SCR...";
CM_ SG_ 2365394174 EngnExhst2NOxSnsrO2PrssrCrrtn "Engine Exhaust 2 NOx Sensor O2 Pressure Correction: Correction of pressure Lambda-signal to correct (recalculate) sensor signal on the Engine ECU side.  This sensor is located at the intake of the aftertreatment system if an aftertreatment system exi...";
CM_ SG_ 2365394174 EngnExhst2NOxSnsrNOxPrssrCrrtn "Engine Exhaust 2 NOx Sensor NOx Pressure Correction: Correction of pressure NOx-signal to correct (recalculate) sensor signal on the Engine ECU side.  This sensor is located at the intake of the aftertreatment system if an aftertreatment system exist...";
CM_ SG_ 2365394174 EngnExhst2NOxSnsrNO2Crrtn "Engine Exhaust 2 NOx Sensor NO2 Correction: Correction of NO2 at the NOx-signal to correct (recalculate) sensor signal on the Engine ECU side.  This sensor is located at the intake of the aftertreatment system if an aftertreatment system exists.";
CM_ SG_ 2365394174 EngnExhst2NOxSnsrNH3Crrtn "Engine Exhaust 2 NOx Sensor NH3 Correction: Correction of NH3 at the NOx-signal to correct (recalculate) sensor signal on the Engine ECU side.  This sensor is located at the intake of the aftertreatment system if an aftertreatment system exists.";
CM_ SG_ 2365394174 EExst2NOxSsSdssFRst "Engine Exhaust 2 NOx Sensor Self-diagnosis Final Result: Self-diagnosis result for NOx sensor Engine Exhaust Bank 2 (EEB2) as a ratio of detected value to reference value defined by supplier.  This sensor is located at the intake of the aftertreatmen...";
CM_ BO_ 2365394430 "Aftertreatment 2 Intake Gas NOx Sensor Correction Data 1";
CM_ SG_ 2365394430 EngnExhst2NOxSnsrHtrRt "Engine Exhaust 2 NOx Sensor Heater Ratio: Heater ratio to determine temperature at sensor tip.  This sensor is located at the intake of the aftertreatment system if an aftertreatment system exists.";
CM_ SG_ 2365394430 EngnExhst2NOxSnsrNwPrtDvtnNOxGn "Engine Exhaust 2 NOx Sensor New Part Deviation NOx Gain: New part deviation NOx_Gain to correct (recalculate) sensor signal on the Engine ECU side.  This sensor is located at the intake of the aftertreatment system if an aftertreatment system exists.";
CM_ SG_ 2365394430 EExst2NOxSsNwPtDvtNOxOst "Engine Exhaust 2 NOx Sensor New Part Deviation NOx Offset: New part deviation NOx_Offset to correct (recalculate) sensor signal on the Engine ECU side.  This sensor is located at the intake of the aftertreatment system if an aftertreatment system exi...";
CM_ SG_ 2365394430 EngnExhst2NOxSnsrOprtnHrs "Engine Exhaust 2 NOx Sensor Operation Hours: Counted hours that the NOx-sensor was operated with status dewpoint reached.  This sensor is located at the intake of the aftertreatment system if an aftertreatment system exists.";
CM_ BO_ 2365394686 "Aftertreatment 1 Outlet Gas NOx Sensor Correction Data 2";
CM_ SG_ 2365394686 Aftrtrtmnt1OtltCrrtdNOx "Aftertreatment 1 Outlet Corrected NOx: The corrected outlet NOx value for aftertreatment 1 shall include all learned adaptions and offsets that are used to adjust the raw signal.2016 MY and later engines with NOx sensors may be required to output a '...";
CM_ SG_ 2365394686 Aftrtrtmnt1OtltNOxSnsrNH3Crrtn "Aftertreatment 1 Outlet NOx Sensor NH3 Correction: Correction of NH3 at the NOx-signal to correct (recalculate) sensor signal on the Engine ECU side.";
CM_ SG_ 2365394686 Aftrtrtmnt1OtltNOxSnsrNO2Crrtn "Aftertreatment 1 Outlet NOx Sensor NO2 Correction: Correction of NO2 at the NOx-signal to correct (recalculate) sensor signal on the Engine ECU side.";
CM_ SG_ 2365394686 Atttt1OttNOxSsNOxPssCt "Aftertreatment 1 Outlet NOx Sensor NOx Pressure Correction: Correction of pressure NOx-signal to correct (recalculate) sensor signal on the Engine ECU side.";
CM_ SG_ 2365394686 Atttt1OttNOxSsO2PssCt "Aftertreatment 1 Outlet NOx Sensor O2 Pressure Correction: Correction of pressure Lambda-signal to correct (recalculate) sensor signal on the Engine ECU side.";
CM_ SG_ 2365394686 Atttt1OttNOxSsSdssFRst "Aftertreatment 1 Outlet NOx Sensor Self-diagnosis Final Result: Self-diagnosis result for NOx sensor ATO1 (Aftertreatment Outlet Bank 1) as a ratio of detected value to reference value defined by supplier.This result is used to determine if the signa...";
CM_ BO_ 2365394942 "Aftertreatment 1 Outlet Gas NOx Sensor Correction Data 1";
CM_ SG_ 2365394942 Aftrtrtmnt1OtltNOxSnsrHtrRt "Aftertreatment 1 Outlet NOx Sensor Heater Ratio: Heater ratio to determine temperature at sensor tip.";
CM_ SG_ 2365394942 Aftrtrtmnt1OtltNOxSnsrOprtnHrs "Aftertreatment 1 Outlet NOx Sensor Operation Hours: Counted hours that the NOx-sensor was operated with status dewpoint reached";
CM_ SG_ 2365394942 Atttt1OttNOxSsNwptdvtNOxG "Aftertreatment 1 Outlet NOx Sensor New part deviation NOx Gain: New part deviation NOx_Gain to correct (recalculate) sensor signal on the Engine ECU side.";
CM_ SG_ 2365394942 Atttt1OttNOxSsNwptdvtNOxOst "Aftertreatment 1 Outlet NOx Sensor New part deviation NOx Offset: New part deviation NOx_Offset to correct (recalculate) sensor signal on the Engine ECU side.";
CM_ BO_ 2365395198 "Aftertreatment 1 Intake Gas NOx Sensor Correction Data 2";
CM_ SG_ 2365395198 EExst1NOxSsSdssFRst "Engine Exhaust 1 NOx Sensor Self-diagnosis Final Result: Self-diagnosis result for NOx sensor Engine Exhaust Bank 1 (EEB1) as a ratio of detected value to reference value defined by supplier.  This sensor is located at the intake of the aftertreatmen...";
CM_ SG_ 2365395198 EngineExhaust1CorrectedNox "Engine Exhaust 1 Corrected Nox: The corrected NOx value for exhaust bank 1 shall include all learned adaptions and offsets that are used to adjust the raw signal.  This sensor is located at the intake of the SCR system if an SCR system exists. 2016 M...";
CM_ SG_ 2365395198 EngnExhst1NOxSnsrNH3Crrtn "Engine Exhaust 1 NOx Sensor NH3 Correction: Correction of NH3 at the NOx-signal to correct (recalculate) sensor signal on the Engine ECU side.  This sensor is located at the intake of the aftertreatment system if an aftertreatment system exists.";
CM_ SG_ 2365395198 EngnExhst1NOxSnsrNO2Crrtn "Engine Exhaust 1 NOx Sensor NO2 Correction: Correction of NO2 at the NOx-signal to correct (recalculate) sensor signal on the Engine ECU side.  This sensor is located at the intake of the aftertreatment system if an aftertreatment system exists.";
CM_ SG_ 2365395198 EngnExhst1NOxSnsrNOxPrssrCrrtn "Engine Exhaust 1 NOx Sensor NOx Pressure Correction: Correction of pressure NOx-signal to correct (recalculate) sensor signal on the Engine ECU side.  This sensor is located at the intake of the aftertreatment system if an aftertreatment system exist...";
CM_ SG_ 2365395198 EngnExhst1NOxSnsrO2PrssrCrrtn "Engine Exhaust 1 NOx Sensor O2 Pressure Correction: Correction of pressure Lambda-signal to correct (recalculate) sensor signal on the Engine ECU side.  This sensor is located at the intake of the aftertreatment system if an aftertreatment system exi...";
CM_ BO_ 2365395454 "Aftertreatment 1 Intake Gas NOx Sensor Correction Data 1";
CM_ SG_ 2365395454 EExst1NOxSsNwptdvtNOxOst "Engine Exhaust 1 NOx Sensor New part deviation NOx Offset: New part deviation NOx_Offset to correct (recalculate) sensor signal on the Engine ECU side.  This sensor is located at the intake of the aftertreatment system if an aftertreatment system exi...";
CM_ SG_ 2365395454 EngnExhst1NOxSnsrHtrRt "Engine Exhaust 1 NOx Sensor Heater Ratio: Heater ratio to determine temperature at sensor tip.  This sensor is located at the intake of the aftertreatment system if an aftertreatment system exists.";
CM_ SG_ 2365395454 EngnExhst1NOxSnsrNwprtdvtnNOxGn "Engine Exhaust 1 NOx Sensor New part deviation NOx Gain: New part deviation NOx_Gain to correct (recalculate) sensor signal on the Engine ECU side.  This sensor is located at the intake of the aftertreatment system if an aftertreatment system exists.";
CM_ SG_ 2365395454 EngnExhst1NOxSnsrOprtnHrs "Engine Exhaust 1 NOx Sensor Operation Hours: Counted hours that the NOx-sensor was operated with status dewpoint reached.  This sensor is located at the intake of the aftertreatment system if an aftertreatment system exists.";
CM_ BO_ 2365400062 "Extended Joystick Message 10";
CM_ SG_ 2365400062 Joystick10Button13PressedStatus "Joystick 10 Button 13 Pressed Status: Reports when the joystick button has been pressed.00b = Button not pressed01b = Button pressed10b = Error Indicator11b = Not Available";
CM_ SG_ 2365400062 Joystick10Button14PressedStatus "Joystick 10 Button 14 Pressed Status: Reports when the joystick button has been pressed.00b = Button not pressed01b = Button pressed10b = Error Indicator11b = Not Available";
CM_ SG_ 2365400062 Joystick10Button15PressedStatus "Joystick 10 Button 15 Pressed Status: Reports when the joystick button has been pressed.00b = Button not pressed01b = Button pressed10b = Error Indicator11b = Not Available";
CM_ SG_ 2365400062 Joystick10Button16PressedStatus "Joystick 10 Button 16 Pressed Status: Reports when the joystick button has been pressed.00b = Button not pressed01b = Button pressed10b = Error Indicator11b = Not Available";
CM_ SG_ 2365400062 Joystick10GripXAxisPosition "Joystick 10 Grip X-Axis Position: The position of the joystick grip in the relative motion of travel from the neutral position.  Position value of 0 is Neutral and position value 1000 (100%) is the end of linear zone.  Value of 1022 indicates an erro...";
CM_ SG_ 2365400062 Joystick10GripYAxisPosition "Joystick 10 Grip Y-Axis Position: The position of the joystick grip in the relative motion of travel from the neutral position.  Position value of 0 is Neutral and position value 1000 (100%) is the end of linear zone.  Value of 1022 indicates an erro...";
CM_ SG_ 2365400062 Joystick10ThetaAxisPosition "Joystick 10 Theta-Axis Position: The position of the joystick in the relative motion of travel from the neutral position.  Position value of 0 is Neutral and position value 1000 (100%) is the end of linear zone.  Value of 1022 indicates an error has ...";
CM_ SG_ 2365400062 Jst10GpXAxsLvRtPstvPstStts "Joystick 10 Grip X-Axis Lever Right Positive Position Status: Reports when the current joystick grip position is on the positive travel side (forward, right, clockwise, up) relative to the neutral position for that axis of travel. 00b = Not on Positi...";
CM_ SG_ 2365400062 Jst10GpYAxsLvFwdPstvPstStts "Joystick 10 Grip Y-Axis Lever Forward Positive Position Status: Reports when the current joystick grip position is on the positive travel side (forward, right, clockwise, up) relative to the neutral position for that axis of travel. 00b = Not on Posi...";
CM_ SG_ 2365400062 Jst10TtAxsCtCwsNtvPstStts "Joystick 10 Theta-Axis Counter Clockwise Negative Position Status: Reports when the current joystick position is on the negative travel side (back, left, counterclockwise, down) relative to the neutral position for that axis of travel. 00b = Not on n...";
CM_ SG_ 2365400062 Jstk10GrpXAxsDtntPstnStts "Joystick 10 Grip X-Axis Detent Position Status: Reports when the current joystick grip position is in the detent position for that axis of travel.00b = Not in the Detent Position01b = In the Detent Position10b = Error Indicator11b = Not Available...";
CM_ SG_ 2365400062 Jstk10GrpXAxsLvrLftNgtvPstnStts "Joystick 10 Grip X-Axis Lever Left Negative Position Status: Reports when the current joystick grip position is on the negative travel side (back, left, counterclockwise, down) relative to the neutral position for that axis of travel. 00b = Not on ne...";
CM_ SG_ 2365400062 Jstk10GrpXAxsNtrlPstnStts "Joystick 10 Grip X-Axis Neutral Position Status: Reports when the current joystick grip position is in the neutral position for that axis of travel.  The neutral position measurement must be determined from some mechanism other than the axis position...";
CM_ SG_ 2365400062 Jstk10GrpYAxsDtntPstnStts "Joystick 10 Grip Y-Axis Detent Position Status: Reports when the current joystick grip position is in the detent position for that axis of travel.00b = Not in the Detent Position01b = In the Detent Position10b = Error Indicator11b = Not Available...";
CM_ SG_ 2365400062 Jstk10GrpYAxsLvrBkNgtvPstnStts "Joystick 10 Grip Y-Axis Lever Back Negative Position Status: Reports when the current joystick grip position is on the negative travel side (back, left, counterclockwise, down) relative to the neutral position for that axis of travel. 00b = Not on ne...";
CM_ SG_ 2365400062 Jstk10GrpYAxsNtrlPstnStts "Joystick 10 Grip Y-Axis Neutral Position Status: Reports when the current joystick grip position is in the neutral position for that axis of travel.  The neutral position measurement must be determined from some mechanism other than the axis position...";
CM_ SG_ 2365400062 Jstk10ThtAxsClkwsPstvPstnStts "Joystick 10 Theta-Axis Clockwise Positive Position Status: Reports when the current joystick position is on the positive travel side (forward, right, clockwise, up) relative to the neutral position for that axis of travel. 00b = Not on Positive side ...";
CM_ SG_ 2365400062 Jstk10ThtAxsDtntPstnStts "Joystick 10 Theta-Axis Detent Position Status: Reports when the current joystick position is in the detent position for that axis of travel.00b = Not in the Detent Position01b = In the Detent Position10b = Error Indicator11b = Not Available";
CM_ SG_ 2365400062 Jstk10ThtAxsNtrlPstnStts "Joystick 10 Theta-Axis Neutral Position Status: Reports when the current joystick position is in the neutral position for that axis of travel.  The neutral position measurement must be determined from some mechanism other than the axis position measu...";
CM_ BO_ 2365400318 "Basic Joystick Message 10";
CM_ SG_ 2365400318 Joystick10Button10PressedStatus "Joystick 10 Button 10 Pressed Status: Reports when the joystick button has been pressed.00b = Button not pressed01b = Button pressed10b = Error Indicator11b = Not Available";
CM_ SG_ 2365400318 Joystick10Button11PressedStatus "Joystick 10 Button 11 Pressed Status: Reports when the joystick button has been pressed.00b = Button not pressed01b = Button pressed10b = Error Indicator11b = Not Available";
CM_ SG_ 2365400318 Joystick10Button12PressedStatus "Joystick 10 Button 12 Pressed Status: Reports when the joystick button has been pressed.00b = Button not pressed01b = Button pressed10b = Error Indicator11b = Not Available";
CM_ SG_ 2365400318 Joystick10Button1PressedStatus "Joystick 10 Button 1 Pressed Status: Reports when the joystick button has been pressed.00b = Button not pressed01b = Button pressed10b = Error Indicator11b = Not Available";
CM_ SG_ 2365400318 Joystick10Button2PressedStatus "Joystick 10 Button 2 Pressed Status: Reports when the joystick button has been pressed.00b = Button not pressed01b = Button pressed10b = Error Indicator11b = Not Available";
CM_ SG_ 2365400318 Joystick10Button3PressedStatus "Joystick 10 Button 3 Pressed Status: Reports when the joystick button has been pressed.00b = Button not pressed01b = Button pressed10b = Error Indicator11b = Not Available";
CM_ SG_ 2365400318 Joystick10Button4PressedStatus "Joystick 10 Button 4 Pressed Status: Reports when the joystick button has been pressed.00b = Button not pressed01b = Button pressed10b = Error Indicator11b = Not Available";
CM_ SG_ 2365400318 Joystick10Button5PressedStatus "Joystick 10 Button 5 Pressed Status: Reports when the joystick button has been pressed.00b = Button not pressed01b = Button pressed10b = Error Indicator11b = Not Available";
CM_ SG_ 2365400318 Joystick10Button6PressedStatus "Joystick 10 Button 6 Pressed Status: Reports when the joystick button has been pressed.00b = Button not pressed01b = Button pressed10b = Error Indicator11b = Not Available";
CM_ SG_ 2365400318 Joystick10Button7PressedStatus "Joystick 10 Button 7 Pressed Status: Reports when the joystick button has been pressed.00b = Button not pressed01b = Button pressed10b = Error Indicator11b = Not Available";
CM_ SG_ 2365400318 Joystick10Button8PressedStatus "Joystick 10 Button 8 Pressed Status: Reports when the joystick button has been pressed.00b = Button not pressed01b = Button pressed10b = Error Indicator11b = Not Available";
CM_ SG_ 2365400318 Joystick10Button9PressedStatus "Joystick 10 Button 9 Pressed Status: Reports when the joystick button has been pressed.00b = Button not pressed01b = Button pressed10b = Error Indicator11b = Not Available";
CM_ SG_ 2365400318 Joystick10XAxisPosition "Joystick 10 X-Axis Position: The position of the joystick in the relative motion of travel from the neutral position.  Position value of 0 is Neutral and position value 1000 (100%) is the end of linear zone.  Value of 1022 indicates an error has occu...";
CM_ SG_ 2365400318 Joystick10YAxisPosition "Joystick 10 Y-Axis Position: The position of the joystick in the relative motion of travel from the neutral position.  Position value of 0 is Neutral and position value 1000 (100%) is the end of linear zone.  Value of 1022 indicates an error has occu...";
CM_ SG_ 2365400318 Jstk10XAxsDtntPstnStts "Joystick 10 X-Axis Detent Position Status: Reports when the current joystick position is in the detent position for that axis of travel.00b = Not in the Detent Position01b = In the Detent Position10b = Error Indicator11b = Not Available";
CM_ SG_ 2365400318 Jstk10XAxsLvrLftNgtvPstnStts "Joystick 10 X-Axis Lever Left Negative Position Status: Reports when the current joystick position is on the negative travel side (back, left, counterclockwise, down) relative to the neutral position for that axis of travel. 00b = Not on negative sid...";
CM_ SG_ 2365400318 Jstk10XAxsLvrRghtPstvPstnStts "Joystick 10 X-Axis Lever Right Positive Position Status: Reports when the current joystick position is on the positive travel side (forward, right, clockwise, up) relative to the neutral position for that axis of travel. 00b = Not on Positive side of...";
CM_ SG_ 2365400318 Jstk10XAxsNtrlPstnStts "Joystick 10 X-Axis Neutral Position Status: Reports when the current joystick position is in the neutral position for that axis of travel.  The neutral position measurement must be determined from some mechanism other than the axis position measureme...";
CM_ SG_ 2365400318 Jstk10YAxsDtntPstnStts "Joystick 10 Y-Axis Detent Position Status: Reports when the current joystick position is in the detent position for that axis of travel.00b = Not in the Detent Position01b = In the Detent Position10b = Error Indicator11b = Not Available";
CM_ SG_ 2365400318 Jstk10YAxsLvrBkNgtvPstnStts "Joystick 10 Y-Axis Lever Back Negative Position Status: Reports when the current joystick position is on the negative travel side (back, left, counterclockwise, down) relative to the neutral position for that axis of travel. 00b = Not on negative sid...";
CM_ SG_ 2365400318 Jstk10YAxsLvrFrwrdPstvPstnStts "Joystick 10 Y-Axis Lever Forward Positive Position Status: Reports when the current joystick position is on the positive travel side (forward, right, clockwise, up) relative to the neutral position for that axis of travel. 00b = Not on Positive side ...";
CM_ SG_ 2365400318 Jstk10YAxsNtrlPstnStts "Joystick 10 Y-Axis Neutral Position Status: Reports when the current joystick position is in the neutral position for that axis of travel.  The neutral position measurement must be determined from some mechanism other than the axis position measureme...";
CM_ BO_ 2365400574 "Extended Joystick Message 9";
CM_ SG_ 2365400574 Joystick9Button13PressedStatus "Joystick 9 Button 13 Pressed Status: Reports when the joystick button has been pressed.00b = Button not pressed01b = Button pressed10b = Error Indicator11b = Not Available";
CM_ SG_ 2365400574 Joystick9Button14PressedStatus "Joystick 9 Button 14 Pressed Status: Reports when the joystick button has been pressed.00b = Button not pressed01b = Button pressed10b = Error Indicator11b = Not Available";
CM_ SG_ 2365400574 Joystick9Button15PressedStatus "Joystick 9 Button 15 Pressed Status: Reports when the joystick button has been pressed.00b = Button not pressed01b = Button pressed10b = Error Indicator11b = Not Available";
CM_ SG_ 2365400574 Joystick9Button16PressedStatus "Joystick 9 Button 16 Pressed Status: Reports when the joystick button has been pressed.00b = Button not pressed01b = Button pressed10b = Error Indicator11b = Not Available";
CM_ SG_ 2365400574 Joystick9GripXAxisPosition "Joystick 9 Grip X-Axis Position: The position of the joystick grip in the relative motion of travel from the neutral position.  Position value of 0 is Neutral and position value 1000 (100%) is the end of linear zone.  Value of 1022 indicates an error...";
CM_ SG_ 2365400574 Joystick9GripYAxisPosition "Joystick 9 Grip Y-Axis Position: The position of the joystick grip in the relative motion of travel from the neutral position.  Position value of 0 is Neutral and position value 1000 (100%) is the end of linear zone.  Value of 1022 indicates an error...";
CM_ SG_ 2365400574 Joystick9ThetaAxisPosition "Joystick 9 Theta-Axis Position: The position of the joystick in the relative motion of travel from the neutral position.  Position value of 0 is Neutral and position value 1000 (100%) is the end of linear zone.  Value of 1022 indicates an error has o...";
CM_ SG_ 2365400574 Jst9GpYAxsLvFwdPstvPstStts "Joystick 9 Grip Y-Axis Lever Forward Positive Position Status: Reports when the current joystick grip position is on the positive travel side (forward, right, clockwise, up) relative to the neutral position for that axis of travel. 00b = Not on Posit...";
CM_ SG_ 2365400574 Jst9TtAxsCtCwsNtvPstStts "Joystick 9 Theta-Axis Counter Clockwise Negative Position Status: Reports when the current joystick position is on the negative travel side (back, left, counterclockwise, down) relative to the neutral position for that axis of travel. 00b = Not on ne...";
CM_ SG_ 2365400574 Jstk9GrpXAxsDtntPstnStts "Joystick 9 Grip X-Axis Detent Position Status: Reports when the current joystick grip position is in the detent position for that axis of travel.00b = Not in the Detent Position01b = In the Detent Position10b = Error Indicator11b = Not Available...";
CM_ SG_ 2365400574 Jstk9GrpXAxsLvrLftNgtvPstnStts "Joystick 9 Grip X-Axis Lever Left Negative Position Status: Reports when the current joystick grip position is on the negative travel side (back, left, counterclockwise, down) relative to the neutral position for that axis of travel. 00b = Not on neg...";
CM_ SG_ 2365400574 Jstk9GrpXAxsLvrRghtPstvPstnStts "Joystick 9 Grip X-Axis Lever Right Positive Position Status: Reports when the current joystick grip position is on the positive travel side (forward, right, clockwise, up) relative to the neutral position for that axis of travel. 00b = Not on Positiv...";
CM_ SG_ 2365400574 Jstk9GrpXAxsNtrlPstnStts "Joystick 9 Grip X-Axis Neutral Position Status: Reports when the current joystick grip position is in the neutral position for that axis of travel.  The neutral position measurement must be determined from some mechanism other than the axis position ...";
CM_ SG_ 2365400574 Jstk9GrpYAxsDtntPstnStts "Joystick 9 Grip Y-Axis Detent Position Status: Reports when the current joystick grip position is in the detent position for that axis of travel.00b = Not in the Detent Position01b = In the Detent Position10b = Error Indicator11b = Not Available...";
CM_ SG_ 2365400574 Jstk9GrpYAxsLvrBkNgtvPstnStts "Joystick 9 Grip Y-Axis Lever Back Negative Position Status: Reports when the current joystick grip position is on the negative travel side (back, left, counterclockwise, down) relative to the neutral position for that axis of travel. 00b = Not on neg...";
CM_ SG_ 2365400574 Jstk9GrpYAxsNtrlPstnStts "Joystick 9 Grip Y-Axis Neutral Position Status: Reports when the current joystick grip position is in the neutral position for that axis of travel.  The neutral position measurement must be determined from some mechanism other than the axis position ...";
CM_ SG_ 2365400574 Jstk9ThtAxsClkwsPstvPstnStts "Joystick 9 Theta-Axis Clockwise Positive Position Status: Reports when the current joystick position is on the positive travel side (forward, right, clockwise, up) relative to the neutral position for that axis of travel. 00b = Not on Positive side o...";
CM_ SG_ 2365400574 Jstk9ThtAxsDtntPstnStts "Joystick 9 Theta-Axis Detent Position Status: Reports when the current joystick position is in the detent position for that axis of travel.00b = Not in the Detent Position01b = In the Detent Position10b = Error Indicator11b = Not Available";
CM_ SG_ 2365400574 Jstk9ThtAxsNtrlPstnStts "Joystick 9 Theta-Axis Neutral Position Status: Reports when the current joystick position is in the neutral position for that axis of travel.  The neutral position measurement must be determined from some mechanism other than the axis position measur...";
CM_ BO_ 2365400830 "Basic Joystick Message 9";
CM_ SG_ 2365400830 Joystick9Button10PressedStatus "Joystick 9 Button 10 Pressed Status: Reports when the joystick button has been pressed.00b = Button not pressed01b = Button pressed10b = Error Indicator11b = Not Available";
CM_ SG_ 2365400830 Joystick9Button11PressedStatus "Joystick 9 Button 11 Pressed Status: Reports when the joystick button has been pressed.00b = Button not pressed01b = Button pressed10b = Error Indicator11b = Not Available";
CM_ SG_ 2365400830 Joystick9Button12PressedStatus "Joystick 9 Button 12 Pressed Status: Reports when the joystick button has been pressed.00b = Button not pressed01b = Button pressed10b = Error Indicator11b = Not Available";
CM_ SG_ 2365400830 Joystick9Button1PressedStatus "Joystick 9 Button 1 Pressed Status: Reports when the joystick button has been pressed.00b = Button not pressed01b = Button pressed10b = Error Indicator11b = Not Available";
CM_ SG_ 2365400830 Joystick9Button2PressedStatus "Joystick 9 Button 2 Pressed Status: Reports when the joystick button has been pressed.00b = Button not pressed01b = Button pressed10b = Error Indicator11b = Not Available";
CM_ SG_ 2365400830 Joystick9Button3PressedStatus "Joystick 9 Button 3 Pressed Status: Reports when the joystick button has been pressed.00b = Button not pressed01b = Button pressed10b = Error Indicator11b = Not Available";
CM_ SG_ 2365400830 Joystick9Button4PressedStatus "Joystick 9 Button 4 Pressed Status: Reports when the joystick button has been pressed.00b = Button not pressed01b = Button pressed10b = Error Indicator11b = Not Available";
CM_ SG_ 2365400830 Joystick9Button5PressedStatus "Joystick 9 Button 5 Pressed Status: Reports when the joystick button has been pressed.00b = Button not pressed01b = Button pressed10b = Error Indicator11b = Not Available";
CM_ SG_ 2365400830 Joystick9Button6PressedStatus "Joystick 9 Button 6 Pressed Status: Reports when the joystick button has been pressed.00b = Button not pressed01b = Button pressed10b = Error Indicator11b = Not Available";
CM_ SG_ 2365400830 Joystick9Button7PressedStatus "Joystick 9 Button 7 Pressed Status: Reports when the joystick button has been pressed.00b = Button not pressed01b = Button pressed10b = Error Indicator11b = Not Available";
CM_ SG_ 2365400830 Joystick9Button8PressedStatus "Joystick 9 Button 8 Pressed Status: Reports when the joystick button has been pressed.00b = Button not pressed01b = Button pressed10b = Error Indicator11b = Not Available";
CM_ SG_ 2365400830 Joystick9Button9PressedStatus "Joystick 9 Button 9 Pressed Status: Reports when the joystick button has been pressed.00b = Button not pressed01b = Button pressed10b = Error Indicator11b = Not Available";
CM_ SG_ 2365400830 Joystick9XAxisPosition "Joystick 9 X-Axis Position: The position of the joystick in the relative motion of travel from the neutral position.  Position value of 0 is Neutral and position value 1000 (100%) is the end of linear zone.  Value of 1022 indicates an error has occur...";
CM_ SG_ 2365400830 Joystick9YAxisPosition "Joystick 9 Y-Axis Position: The position of the joystick in the relative motion of travel from the neutral position.  Position value of 0 is Neutral and position value 1000 (100%) is the end of linear zone.  Value of 1022 indicates an error has occur...";
CM_ SG_ 2365400830 Jstk9XAxsDtntPstnStts "Joystick 9 X-Axis Detent Position Status: Reports when the current joystick position is in the detent position for that axis of travel.00b = Not in the Detent Position01b = In the Detent Position10b = Error Indicator11b = Not Available";
CM_ SG_ 2365400830 Jstk9XAxsLvrLftNgtvPstnStts "Joystick 9 X-Axis Lever Left Negative Position Status: Reports when the current joystick position is on the negative travel side (back, left, counterclockwise, down) relative to the neutral position for that axis of travel. 00b = Not on negative side...";
CM_ SG_ 2365400830 Jstk9XAxsLvrRghtPstvPstnStts "Joystick 9 X-Axis Lever Right Positive Position Status: Reports when the current joystick position is on the positive travel side (forward, right, clockwise, up) relative to the neutral position for that axis of travel. 00b = Not on Positive side of ...";
CM_ SG_ 2365400830 Jstk9XAxsNtrlPstnStts "Joystick 9 X-Axis Neutral Position Status: Reports when the current joystick position is in the neutral position for that axis of travel.  The neutral position measurement must be determined from some mechanism other than the axis position measuremen...";
CM_ SG_ 2365400830 Jstk9YAxsDtntPstnStts "Joystick 9 Y-Axis Detent Position Status: Reports when the current joystick position is in the detent position for that axis of travel.00b = Not in the Detent Position01b = In the Detent Position10b = Error Indicator11b = Not Available";
CM_ SG_ 2365400830 Jstk9YAxsLvrBkNgtvPstnStts "Joystick 9 Y-Axis Lever Back Negative Position Status: Reports when the current joystick position is on the negative travel side (back, left, counterclockwise, down) relative to the neutral position for that axis of travel. 00b = Not on negative side...";
CM_ SG_ 2365400830 Jstk9YAxsLvrFrwrdPstvPstnStts "Joystick 9 Y-Axis Lever Forward Positive Position Status: Reports when the current joystick position is on the positive travel side (forward, right, clockwise, up) relative to the neutral position for that axis of travel. 00b = Not on Positive side o...";
CM_ SG_ 2365400830 Jstk9YAxsNtrlPstnStts "Joystick 9 Y-Axis Neutral Position Status: Reports when the current joystick position is in the neutral position for that axis of travel.  The neutral position measurement must be determined from some mechanism other than the axis position measuremen...";
CM_ BO_ 2365401086 "Extended Joystick Message 8";
CM_ SG_ 2365401086 Joystick8Button13PressedStatus "Joystick 8 Button 13 Pressed Status: Reports when the joystick button has been pressed.00b = Button not pressed01b = Button pressed10b = Error Indicator11b = Not Available";
CM_ SG_ 2365401086 Joystick8Button14PressedStatus "Joystick 8 Button 14 Pressed Status: Reports when the joystick button has been pressed.00b = Button not pressed01b = Button pressed10b = Error Indicator11b = Not Available";
CM_ SG_ 2365401086 Joystick8Button15PressedStatus "Joystick 8 Button 15 Pressed Status: Reports when the joystick button has been pressed.00b = Button not pressed01b = Button pressed10b = Error Indicator11b = Not Available";
CM_ SG_ 2365401086 Joystick8Button16PressedStatus "Joystick 8 Button 16 Pressed Status: Reports when the joystick button has been pressed.00b = Button not pressed01b = Button pressed10b = Error Indicator11b = Not Available";
CM_ SG_ 2365401086 Joystick8GripXAxisPosition "Joystick 8 Grip X-Axis Position: The position of the joystick grip in the relative motion of travel from the neutral position.  Position value of 0 is Neutral and position value 1000 (100%) is the end of linear zone.  Value of 1022 indicates an error...";
CM_ SG_ 2365401086 Joystick8GripYAxisPosition "Joystick 8 Grip Y-Axis Position: The position of the joystick grip in the relative motion of travel from the neutral position.  Position value of 0 is Neutral and position value 1000 (100%) is the end of linear zone.  Value of 1022 indicates an error...";
CM_ SG_ 2365401086 Joystick8ThetaAxisPosition "Joystick 8 Theta-Axis Position: The position of the joystick in the relative motion of travel from the neutral position.  Position value of 0 is Neutral and position value 1000 (100%) is the end of linear zone.  Value of 1022 indicates an error has o...";
CM_ SG_ 2365401086 Jst8GpYAxsLvFwdPstvPstStts "Joystick 8 Grip Y-Axis Lever Forward Positive Position Status: Reports when the current joystick grip position is on the positive travel side (forward, right, clockwise, up) relative to the neutral position for that axis of travel. 00b = Not on Posit...";
CM_ SG_ 2365401086 Jst8TtAxsCtCwsNtvPstStts "Joystick 8 Theta-Axis Counter Clockwise Negative Position Status: Reports when the current joystick position is on the negative travel side (back, left, counterclockwise, down) relative to the neutral position for that axis of travel. 00b = Not on ne...";
CM_ SG_ 2365401086 Jstk8GrpXAxsDtntPstnStts "Joystick 8 Grip X-Axis Detent Position Status: Reports when the current joystick grip position is in the detent position for that axis of travel.00b = Not in the Detent Position01b = In the Detent Position10b = Error Indicator11b = Not Available...";
CM_ SG_ 2365401086 Jstk8GrpXAxsLvrLftNgtvPstnStts "Joystick 8 Grip X-Axis Lever Left Negative Position Status: Reports when the current joystick grip position is on the negative travel side (back, left, counterclockwise, down) relative to the neutral position for that axis of travel. 00b = Not on neg...";
CM_ SG_ 2365401086 Jstk8GrpXAxsLvrRghtPstvPstnStts "Joystick 8 Grip X-Axis Lever Right Positive Position Status: Reports when the current joystick grip position is on the positive travel side (forward, right, clockwise, up) relative to the neutral position for that axis of travel. 00b = Not on Positiv...";
CM_ SG_ 2365401086 Jstk8GrpXAxsNtrlPstnStts "Joystick 8 Grip X-Axis Neutral Position Status: Reports when the current joystick grip position is in the neutral position for that axis of travel.  The neutral position measurement must be determined from some mechanism other than the axis position ...";
CM_ SG_ 2365401086 Jstk8GrpYAxsDtntPstnStts "Joystick 8 Grip Y-Axis Detent Position Status: Reports when the current joystick grip position is in the detent position for that axis of travel.00b = Not in the Detent Position01b = In the Detent Position10b = Error Indicator11b = Not Available...";
CM_ SG_ 2365401086 Jstk8GrpYAxsLvrBkNgtvPstnStts "Joystick 8 Grip Y-Axis Lever Back Negative Position Status: Reports when the current joystick grip position is on the negative travel side (back, left, counterclockwise, down) relative to the neutral position for that axis of travel. 00b = Not on neg...";
CM_ SG_ 2365401086 Jstk8GrpYAxsNtrlPstnStts "Joystick 8 Grip Y-Axis Neutral Position Status: Reports when the current joystick grip position is in the neutral position for that axis of travel.  The neutral position measurement must be determined from some mechanism other than the axis position ...";
CM_ SG_ 2365401086 Jstk8ThtAxsClkwsPstvPstnStts "Joystick 8 Theta-Axis Clockwise Positive Position Status: Reports when the current joystick position is on the positive travel side (forward, right, clockwise, up) relative to the neutral position for that axis of travel. 00b = Not on Positive side o...";
CM_ SG_ 2365401086 Jstk8ThtAxsDtntPstnStts "Joystick 8 Theta-Axis Detent Position Status: Reports when the current joystick position is in the detent position for that axis of travel.00b = Not in the Detent Position01b = In the Detent Position10b = Error Indicator11b = Not Available";
CM_ SG_ 2365401086 Jstk8ThtAxsNtrlPstnStts "Joystick 8 Theta-Axis Neutral Position Status: Reports when the current joystick position is in the neutral position for that axis of travel.  The neutral position measurement must be determined from some mechanism other than the axis position measur...";
CM_ BO_ 2365401342 "Basic Joystick Message 8";
CM_ SG_ 2365401342 Joystick8Button10PressedStatus "Joystick 8 Button 10 Pressed Status: Reports when the joystick button has been pressed.00b = Button not pressed01b = Button pressed10b = Error Indicator11b = Not Available";
CM_ SG_ 2365401342 Joystick8Button11PressedStatus "Joystick 8 Button 11 Pressed Status: Reports when the joystick button has been pressed.00b = Button not pressed01b = Button pressed10b = Error Indicator11b = Not Available";
CM_ SG_ 2365401342 Joystick8Button12PressedStatus "Joystick 8 Button 12 Pressed Status: Reports when the joystick button has been pressed.00b = Button not pressed01b = Button pressed10b = Error Indicator11b = Not Available";
CM_ SG_ 2365401342 Joystick8Button1PressedStatus "Joystick 8 Button 1 Pressed Status: Reports when the joystick button has been pressed.00b = Button not pressed01b = Button pressed10b = Error Indicator11b = Not Available";
CM_ SG_ 2365401342 Joystick8Button2PressedStatus "Joystick 8 Button 2 Pressed Status: Reports when the joystick button has been pressed.00b = Button not pressed01b = Button pressed10b = Error Indicator11b = Not Available";
CM_ SG_ 2365401342 Joystick8Button3PressedStatus "Joystick 8 Button 3 Pressed Status: Reports when the joystick button has been pressed.00b = Button not pressed01b = Button pressed10b = Error Indicator11b = Not Available";
CM_ SG_ 2365401342 Joystick8Button4PressedStatus "Joystick 8 Button 4 Pressed Status: Reports when the joystick button has been pressed.00b = Button not pressed01b = Button pressed10b = Error Indicator11b = Not Available";
CM_ SG_ 2365401342 Joystick8Button5PressedStatus "Joystick 8 Button 5 Pressed Status: Reports when the joystick button has been pressed.00b = Button not pressed01b = Button pressed10b = Error Indicator11b = Not Available";
CM_ SG_ 2365401342 Joystick8Button6PressedStatus "Joystick 8 Button 6 Pressed Status: Reports when the joystick button has been pressed.00b = Button not pressed01b = Button pressed10b = Error Indicator11b = Not Available";
CM_ SG_ 2365401342 Joystick8Button7PressedStatus "Joystick 8 Button 7 Pressed Status: Reports when the joystick button has been pressed.00b = Button not pressed01b = Button pressed10b = Error Indicator11b = Not Available";
CM_ SG_ 2365401342 Joystick8Button8PressedStatus "Joystick 8 Button 8 Pressed Status: Reports when the joystick button has been pressed.00b = Button not pressed01b = Button pressed10b = Error Indicator11b = Not Available";
CM_ SG_ 2365401342 Joystick8Button9PressedStatus "Joystick 8 Button 9 Pressed Status: Reports when the joystick button has been pressed.00b = Button not pressed01b = Button pressed10b = Error Indicator11b = Not Available";
CM_ SG_ 2365401342 Joystick8XAxisPosition "Joystick 8 X-Axis Position: The position of the joystick in the relative motion of travel from the neutral position.  Position value of 0 is Neutral and position value 1000 (100%) is the end of linear zone.  Value of 1022 indicates an error has occur...";
CM_ SG_ 2365401342 Joystick8YAxisPosition "Joystick 8 Y-Axis Position: The position of the joystick in the relative motion of travel from the neutral position.  Position value of 0 is Neutral and position value 1000 (100%) is the end of linear zone.  Value of 1022 indicates an error has occur...";
CM_ SG_ 2365401342 Jstk8XAxsDtntPstnStts "Joystick 8 X-Axis Detent Position Status: Reports when the current joystick position is in the detent position for that axis of travel.00b = Not in the Detent Position01b = In the Detent Position10b = Error Indicator11b = Not Available";
CM_ SG_ 2365401342 Jstk8XAxsLvrLftNgtvPstnStts "Joystick 8 X-Axis Lever Left Negative Position Status: Reports when the current joystick position is on the negative travel side (back, left, counterclockwise, down) relative to the neutral position for that axis of travel. 00b = Not on negative side...";
CM_ SG_ 2365401342 Jstk8XAxsLvrRghtPstvPstnStts "Joystick 8 X-Axis Lever Right Positive Position Status: Reports when the current joystick position is on the positive travel side (forward, right, clockwise, up) relative to the neutral position for that axis of travel. 00b = Not on Positive side of ...";
CM_ SG_ 2365401342 Jstk8XAxsNtrlPstnStts "Joystick 8 X-Axis Neutral Position Status: Reports when the current joystick position is in the neutral position for that axis of travel.  The neutral position measurement must be determined from some mechanism other than the axis position measuremen...";
CM_ SG_ 2365401342 Jstk8YAxsDtntPstnStts "Joystick 8 Y-Axis Detent Position Status: Reports when the current joystick position is in the detent position for that axis of travel.00b = Not in the Detent Position01b = In the Detent Position10b = Error Indicator11b = Not Available";
CM_ SG_ 2365401342 Jstk8YAxsLvrBkNgtvPstnStts "Joystick 8 Y-Axis Lever Back Negative Position Status: Reports when the current joystick position is on the negative travel side (back, left, counterclockwise, down) relative to the neutral position for that axis of travel. 00b = Not on negative side...";
CM_ SG_ 2365401342 Jstk8YAxsLvrFrwrdPstvPstnStts "Joystick 8 Y-Axis Lever Forward Positive Position Status: Reports when the current joystick position is on the positive travel side (forward, right, clockwise, up) relative to the neutral position for that axis of travel. 00b = Not on Positive side o...";
CM_ SG_ 2365401342 Jstk8YAxsNtrlPstnStts "Joystick 8 Y-Axis Neutral Position Status: Reports when the current joystick position is in the neutral position for that axis of travel.  The neutral position measurement must be determined from some mechanism other than the axis position measuremen...";
CM_ BO_ 2365401598 "Extended Joystick Message 7";
CM_ SG_ 2365401598 Joystick7Button13PressedStatus "Joystick 7 Button 13 Pressed Status: Reports when the joystick button has been pressed.00b = Button not pressed01b = Button pressed10b = Error Indicator11b = Not Available";
CM_ SG_ 2365401598 Joystick7Button14PressedStatus "Joystick 7 Button 14 Pressed Status: Reports when the joystick button has been pressed.00b = Button not pressed01b = Button pressed10b = Error Indicator11b = Not Available";
CM_ SG_ 2365401598 Joystick7Button15PressedStatus "Joystick 7 Button 15 Pressed Status: Reports when the joystick button has been pressed.00b = Button not pressed01b = Button pressed10b = Error Indicator11b = Not Available";
CM_ SG_ 2365401598 Joystick7Button16PressedStatus "Joystick 7 Button 16 Pressed Status: Reports when the joystick button has been pressed.00b = Button not pressed01b = Button pressed10b = Error Indicator11b = Not Available";
CM_ SG_ 2365401598 Joystick7GripXAxisPosition "Joystick 7 Grip X-Axis Position: The position of the joystick grip in the relative motion of travel from the neutral position.  Position value of 0 is Neutral and position value 1000 (100%) is the end of linear zone.  Value of 1022 indicates an error...";
CM_ SG_ 2365401598 Joystick7GripYAxisPosition "Joystick 7 Grip Y-Axis Position: The position of the joystick grip in the relative motion of travel from the neutral position.  Position value of 0 is Neutral and position value 1000 (100%) is the end of linear zone.  Value of 1022 indicates an error...";
CM_ SG_ 2365401598 Joystick7ThetaAxisPosition "Joystick 7 Theta-Axis Position: The position of the joystick in the relative motion of travel from the neutral position.  Position value of 0 is Neutral and position value 1000 (100%) is the end of linear zone.  Value of 1022 indicates an error has o...";
CM_ SG_ 2365401598 Jst7GpYAxsLvFwdPstvPstStts "Joystick 7 Grip Y-Axis Lever Forward Positive Position Status: Reports when the current joystick grip position is on the positive travel side (forward, right, clockwise, up) relative to the neutral position for that axis of travel. 00b = Not on Posit...";
CM_ SG_ 2365401598 Jst7TtAxsCtCwsNtvPstStts "Joystick 7 Theta-Axis Counter Clockwise Negative Position Status: Reports when the current joystick position is on the negative travel side (back, left, counterclockwise, down) relative to the neutral position for that axis of travel. 00b = Not on ne...";
CM_ SG_ 2365401598 Jstk7GrpXAxsDtntPstnStts "Joystick 7 Grip X-Axis Detent Position Status: Reports when the current joystick grip position is in the detent position for that axis of travel.00b = Not in the Detent Position01b = In the Detent Position10b = Error Indicator11b = Not Available...";
CM_ SG_ 2365401598 Jstk7GrpXAxsLvrLftNgtvPstnStts "Joystick 7 Grip X-Axis Lever Left Negative Position Status: Reports when the current joystick grip position is on the negative travel side (back, left, counterclockwise, down) relative to the neutral position for that axis of travel. 00b = Not on neg...";
CM_ SG_ 2365401598 Jstk7GrpXAxsLvrRghtPstvPstnStts "Joystick 7 Grip X-Axis Lever Right Positive Position Status: Reports when the current joystick grip position is on the positive travel side (forward, right, clockwise, up) relative to the neutral position for that axis of travel. 00b = Not on Positiv...";
CM_ SG_ 2365401598 Jstk7GrpXAxsNtrlPstnStts "Joystick 7 Grip X-Axis Neutral Position Status: Reports when the current joystick grip position is in the neutral position for that axis of travel.  The neutral position measurement must be determined from some mechanism other than the axis position ...";
CM_ SG_ 2365401598 Jstk7GrpYAxsDtntPstnStts "Joystick 7 Grip Y-Axis Detent Position Status: Reports when the current joystick grip position is in the detent position for that axis of travel.00b = Not in the Detent Position01b = In the Detent Position10b = Error Indicator11b = Not Available...";
CM_ SG_ 2365401598 Jstk7GrpYAxsLvrBkNgtvPstnStts "Joystick 7 Grip Y-Axis Lever Back Negative Position Status: Reports when the current joystick grip position is on the negative travel side (back, left, counterclockwise, down) relative to the neutral position for that axis of travel. 00b = Not on neg...";
CM_ SG_ 2365401598 Jstk7GrpYAxsNtrlPstnStts "Joystick 7 Grip Y-Axis Neutral Position Status: Reports when the current joystick grip position is in the neutral position for that axis of travel.  The neutral position measurement must be determined from some mechanism other than the axis position ...";
CM_ SG_ 2365401598 Jstk7ThtAxsClkwsPstvPstnStts "Joystick 7 Theta-Axis Clockwise Positive Position Status: Reports when the current joystick position is on the positive travel side (forward, right, clockwise, up) relative to the neutral position for that axis of travel. 00b = Not on Positive side o...";
CM_ SG_ 2365401598 Jstk7ThtAxsDtntPstnStts "Joystick 7 Theta-Axis Detent Position Status: Reports when the current joystick position is in the detent position for that axis of travel.00b = Not in the Detent Position01b = In the Detent Position10b = Error Indicator11b = Not Available";
CM_ SG_ 2365401598 Jstk7ThtAxsNtrlPstnStts "Joystick 7 Theta-Axis Neutral Position Status: Reports when the current joystick position is in the neutral position for that axis of travel.  The neutral position measurement must be determined from some mechanism other than the axis position measur...";
CM_ BO_ 2365401854 "Basic Joystick Message 7";
CM_ SG_ 2365401854 Joystick7Button10PressedStatus "Joystick 7 Button 10 Pressed Status: Reports when the joystick button has been pressed.00b = Button not pressed01b = Button pressed10b = Error Indicator11b = Not Available";
CM_ SG_ 2365401854 Joystick7Button11PressedStatus "Joystick 7 Button 11 Pressed Status: Reports when the joystick button has been pressed.00b = Button not pressed01b = Button pressed10b = Error Indicator11b = Not Available";
CM_ SG_ 2365401854 Joystick7Button12PressedStatus "Joystick 7 Button 12 Pressed Status: Reports when the joystick button has been pressed.00b = Button not pressed01b = Button pressed10b = Error Indicator11b = Not Available";
CM_ SG_ 2365401854 Joystick7Button1PressedStatus "Joystick 7 Button 1 Pressed Status: Reports when the joystick button has been pressed.00b = Button not pressed01b = Button pressed10b = Error Indicator11b = Not Available";
CM_ SG_ 2365401854 Joystick7Button2PressedStatus "Joystick 7 Button 2 Pressed Status: Reports when the joystick button has been pressed.00b = Button not pressed01b = Button pressed10b = Error Indicator11b = Not Available";
CM_ SG_ 2365401854 Joystick7Button3PressedStatus "Joystick 7 Button 3 Pressed Status: Reports when the joystick button has been pressed.00b = Button not pressed01b = Button pressed10b = Error Indicator11b = Not Available";
CM_ SG_ 2365401854 Joystick7Button4PressedStatus "Joystick 7 Button 4 Pressed Status: Reports when the joystick button has been pressed.00b = Button not pressed01b = Button pressed10b = Error Indicator11b = Not Available";
CM_ SG_ 2365401854 Joystick7Button5PressedStatus "Joystick 7 Button 5 Pressed Status: Reports when the joystick button has been pressed.00b = Button not pressed01b = Button pressed10b = Error Indicator11b = Not Available";
CM_ SG_ 2365401854 Joystick7Button6PressedStatus "Joystick 7 Button 6 Pressed Status: Reports when the joystick button has been pressed.00b = Button not pressed01b = Button pressed10b = Error Indicator11b = Not Available";
CM_ SG_ 2365401854 Joystick7Button7PressedStatus "Joystick 7 Button 7 Pressed Status: Reports when the joystick button has been pressed.00b = Button not pressed01b = Button pressed10b = Error Indicator11b = Not Available";
CM_ SG_ 2365401854 Joystick7Button8PressedStatus "Joystick 7 Button 8 Pressed Status: Reports when the joystick button has been pressed.00b = Button not pressed01b = Button pressed10b = Error Indicator11b = Not Available";
CM_ SG_ 2365401854 Joystick7Button9PressedStatus "Joystick 7 Button 9 Pressed Status: Reports when the joystick button has been pressed.00b = Button not pressed01b = Button pressed10b = Error Indicator11b = Not Available";
CM_ SG_ 2365401854 Joystick7XAxisPosition "Joystick 7 X-Axis Position: The position of the joystick in the relative motion of travel from the neutral position.  Position value of 0 is Neutral and position value 1000 (100%) is the end of linear zone.  Value of 1022 indicates an error has occur...";
CM_ SG_ 2365401854 Joystick7YAxisPosition "Joystick 7 Y-Axis Position: The position of the joystick in the relative motion of travel from the neutral position.  Position value of 0 is Neutral and position value 1000 (100%) is the end of linear zone.  Value of 1022 indicates an error has occur...";
CM_ SG_ 2365401854 Jstk7XAxsDtntPstnStts "Joystick 7 X-Axis Detent Position Status: Reports when the current joystick position is in the detent position for that axis of travel.00b = Not in the Detent Position01b = In the Detent Position10b = Error Indicator11b = Not Available";
CM_ SG_ 2365401854 Jstk7XAxsLvrLftNgtvPstnStts "Joystick 7 X-Axis Lever Left Negative Position Status: Reports when the current joystick position is on the negative travel side (back, left, counterclockwise, down) relative to the neutral position for that axis of travel. 00b = Not on negative side...";
CM_ SG_ 2365401854 Jstk7XAxsLvrRghtPstvPstnStts "Joystick 7 X-Axis Lever Right Positive Position Status: Reports when the current joystick position is on the positive travel side (forward, right, clockwise, up) relative to the neutral position for that axis of travel. 00b = Not on Positive side of ...";
CM_ SG_ 2365401854 Jstk7XAxsNtrlPstnStts "Joystick 7 X-Axis Neutral Position Status: Reports when the current joystick position is in the neutral position for that axis of travel.  The neutral position measurement must be determined from some mechanism other than the axis position measuremen...";
CM_ SG_ 2365401854 Jstk7YAxsDtntPstnStts "Joystick 7 Y-Axis Detent Position Status: Reports when the current joystick position is in the detent position for that axis of travel.00b = Not in the Detent Position01b = In the Detent Position10b = Error Indicator11b = Not Available";
CM_ SG_ 2365401854 Jstk7YAxsLvrBkNgtvPstnStts "Joystick 7 Y-Axis Lever Back Negative Position Status: Reports when the current joystick position is on the negative travel side (back, left, counterclockwise, down) relative to the neutral position for that axis of travel. 00b = Not on negative side...";
CM_ SG_ 2365401854 Jstk7YAxsLvrFrwrdPstvPstnStts "Joystick 7 Y-Axis Lever Forward Positive Position Status: Reports when the current joystick position is on the positive travel side (forward, right, clockwise, up) relative to the neutral position for that axis of travel. 00b = Not on Positive side o...";
CM_ SG_ 2365401854 Jstk7YAxsNtrlPstnStts "Joystick 7 Y-Axis Neutral Position Status: Reports when the current joystick position is in the neutral position for that axis of travel.  The neutral position measurement must be determined from some mechanism other than the axis position measuremen...";
CM_ BO_ 2365402110 "Extended Joystick Message 6";
CM_ SG_ 2365402110 Joystick6Button13PressedStatus "Joystick 6 Button 13 Pressed Status: Reports when the joystick button has been pressed.00b = Button not pressed01b = Button pressed10b = Error Indicator11b = Not Available";
CM_ SG_ 2365402110 Joystick6Button14PressedStatus "Joystick 6 Button 14 Pressed Status: Reports when the joystick button has been pressed.00b = Button not pressed01b = Button pressed10b = Error Indicator11b = Not Available";
CM_ SG_ 2365402110 Joystick6Button15PressedStatus "Joystick 6 Button 15 Pressed Status: Reports when the joystick button has been pressed.00b = Button not pressed01b = Button pressed10b = Error Indicator11b = Not Available";
CM_ SG_ 2365402110 Joystick6Button16PressedStatus "Joystick 6 Button 16 Pressed Status: Reports when the joystick button has been pressed.00b = Button not pressed01b = Button pressed10b = Error Indicator11b = Not Available";
CM_ SG_ 2365402110 Joystick6GripXAxisPosition "Joystick 6 Grip X-Axis Position: The position of the joystick grip in the relative motion of travel from the neutral position.  Position value of 0 is Neutral and position value 1000 (100%) is the end of linear zone.  Value of 1022 indicates an error...";
CM_ SG_ 2365402110 Joystick6GripYAxisPosition "Joystick 6 Grip Y-Axis Position: The position of the joystick grip in the relative motion of travel from the neutral position.  Position value of 0 is Neutral and position value 1000 (100%) is the end of linear zone.  Value of 1022 indicates an error...";
CM_ SG_ 2365402110 Joystick6ThetaAxisPosition "Joystick 6 Theta-Axis Position: The position of the joystick in the relative motion of travel from the neutral position.  Position value of 0 is Neutral and position value 1000 (100%) is the end of linear zone.  Value of 1022 indicates an error has o...";
CM_ SG_ 2365402110 Jst6GpYAxsLvFwdPstvPstStts "Joystick 6 Grip Y-Axis Lever Forward Positive Position Status: Reports when the current joystick grip position is on the positive travel side (forward, right, clockwise, up) relative to the neutral position for that axis of travel. 00b = Not on Posit...";
CM_ SG_ 2365402110 Jst6TtAxsCtCwsNtvPstStts "Joystick 6 Theta-Axis Counter Clockwise Negative Position Status: Reports when the current joystick position is on the negative travel side (back, left, counterclockwise, down) relative to the neutral position for that axis of travel. 00b = Not on ne...";
CM_ SG_ 2365402110 Jstk6GrpXAxsDtntPstnStts "Joystick 6 Grip X-Axis Detent Position Status: Reports when the current joystick grip position is in the detent position for that axis of travel.00b = Not in the Detent Position01b = In the Detent Position10b = Error Indicator11b = Not Available...";
CM_ SG_ 2365402110 Jstk6GrpXAxsLvrLftNgtvPstnStts "Joystick 6 Grip X-Axis Lever Left Negative Position Status: Reports when the current joystick grip position is on the negative travel side (back, left, counterclockwise, down) relative to the neutral position for that axis of travel. 00b = Not on neg...";
CM_ SG_ 2365402110 Jstk6GrpXAxsLvrRghtPstvPstnStts "Joystick 6 Grip X-Axis Lever Right Positive Position Status: Reports when the current joystick grip position is on the positive travel side (forward, right, clockwise, up) relative to the neutral position for that axis of travel. 00b = Not on Positiv...";
CM_ SG_ 2365402110 Jstk6GrpXAxsNtrlPstnStts "Joystick 6 Grip X-Axis Neutral Position Status: Reports when the current joystick grip position is in the neutral position for that axis of travel.  The neutral position measurement must be determined from some mechanism other than the axis position ...";
CM_ SG_ 2365402110 Jstk6GrpYAxsDtntPstnStts "Joystick 6 Grip Y-Axis Detent Position Status: Reports when the current joystick grip position is in the detent position for that axis of travel.00b = Not in the Detent Position01b = In the Detent Position10b = Error Indicator11b = Not Available...";
CM_ SG_ 2365402110 Jstk6GrpYAxsLvrBkNgtvPstnStts "Joystick 6 Grip Y-Axis Lever Back Negative Position Status: Reports when the current joystick grip position is on the negative travel side (back, left, counterclockwise, down) relative to the neutral position for that axis of travel. 00b = Not on neg...";
CM_ SG_ 2365402110 Jstk6GrpYAxsNtrlPstnStts "Joystick 6 Grip Y-Axis Neutral Position Status: Reports when the current joystick grip position is in the neutral position for that axis of travel.  The neutral position measurement must be determined from some mechanism other than the axis position ...";
CM_ SG_ 2365402110 Jstk6ThtAxsClkwsPstvPstnStts "Joystick 6 Theta-Axis Clockwise Positive Position Status: Reports when the current joystick position is on the positive travel side (forward, right, clockwise, up) relative to the neutral position for that axis of travel. 00b = Not on Positive side o...";
CM_ SG_ 2365402110 Jstk6ThtAxsDtntPstnStts "Joystick 6 Theta-Axis Detent Position Status: Reports when the current joystick position is in the detent position for that axis of travel.00b = Not in the Detent Position01b = In the Detent Position10b = Error Indicator11b = Not Available";
CM_ SG_ 2365402110 Jstk6ThtAxsNtrlPstnStts "Joystick 6 Theta-Axis Neutral Position Status: Reports when the current joystick position is in the neutral position for that axis of travel.  The neutral position measurement must be determined from some mechanism other than the axis position measur...";
CM_ BO_ 2365402366 "Basic Joystick Message 6";
CM_ SG_ 2365402366 Joystick6Button10PressedStatus "Joystick 6 Button 10 Pressed Status: Reports when the joystick button has been pressed.00b = Button not pressed01b = Button pressed10b = Error Indicator11b = Not Available";
CM_ SG_ 2365402366 Joystick6Button11PressedStatus "Joystick 6 Button 11 Pressed Status: Reports when the joystick button has been pressed.00b = Button not pressed01b = Button pressed10b = Error Indicator11b = Not Available";
CM_ SG_ 2365402366 Joystick6Button12PressedStatus "Joystick 6 Button 12 Pressed Status: Reports when the joystick button has been pressed.00b = Button not pressed01b = Button pressed10b = Error Indicator11b = Not Available";
CM_ SG_ 2365402366 Joystick6Button1PressedStatus "Joystick 6 Button 1 Pressed Status: Reports when the joystick button has been pressed.00b = Button not pressed01b = Button pressed10b = Error Indicator11b = Not Available";
CM_ SG_ 2365402366 Joystick6Button2PressedStatus "Joystick 6 Button 2 Pressed Status: Reports when the joystick button has been pressed.00b = Button not pressed01b = Button pressed10b = Error Indicator11b = Not Available";
CM_ SG_ 2365402366 Joystick6Button3PressedStatus "Joystick 6 Button 3 Pressed Status: Reports when the joystick button has been pressed.00b = Button not pressed01b = Button pressed10b = Error Indicator11b = Not Available";
CM_ SG_ 2365402366 Joystick6Button4PressedStatus "Joystick 6 Button 4 Pressed Status: Reports when the joystick button has been pressed.00b = Button not pressed01b = Button pressed10b = Error Indicator11b = Not Available";
CM_ SG_ 2365402366 Joystick6Button5PressedStatus "Joystick 6 Button 5 Pressed Status: Reports when the joystick button has been pressed.00b = Button not pressed01b = Button pressed10b = Error Indicator11b = Not Available";
CM_ SG_ 2365402366 Joystick6Button6PressedStatus "Joystick 6 Button 6 Pressed Status: Reports when the joystick button has been pressed.00b = Button not pressed01b = Button pressed10b = Error Indicator11b = Not Available";
CM_ SG_ 2365402366 Joystick6Button7PressedStatus "Joystick 6 Button 7 Pressed Status: Reports when the joystick button has been pressed.00b = Button not pressed01b = Button pressed10b = Error Indicator11b = Not Available";
CM_ SG_ 2365402366 Joystick6Button8PressedStatus "Joystick 6 Button 8 Pressed Status: Reports when the joystick button has been pressed.00b = Button not pressed01b = Button pressed10b = Error Indicator11b = Not Available";
CM_ SG_ 2365402366 Joystick6Button9PressedStatus "Joystick 6 Button 9 Pressed Status: Reports when the joystick button has been pressed.00b = Button not pressed01b = Button pressed10b = Error Indicator11b = Not Available";
CM_ SG_ 2365402366 Joystick6XAxisPosition "Joystick 6 X-Axis Position: The position of the joystick in the relative motion of travel from the neutral position.  Position value of 0 is Neutral and position value 1000 (100%) is the end of linear zone.  Value of 1022 indicates an error has occur...";
CM_ SG_ 2365402366 Joystick6YAxisPosition "Joystick 6 Y-Axis Position: The position of the joystick in the relative motion of travel from the neutral position.  Position value of 0 is Neutral and position value 1000 (100%) is the end of linear zone.  Value of 1022 indicates an error has occur...";
CM_ SG_ 2365402366 Jstk6XAxsDtntPstnStts "Joystick 6 X-Axis Detent Position Status: Reports when the current joystick position is in the detent position for that axis of travel.00b = Not in the Detent Position01b = In the Detent Position10b = Error Indicator11b = Not Available";
CM_ SG_ 2365402366 Jstk6XAxsLvrLftNgtvPstnStts "Joystick 6 X-Axis Lever Left Negative Position Status: Reports when the current joystick position is on the negative travel side (back, left, counterclockwise, down) relative to the neutral position for that axis of travel. 00b = Not on negative side...";
CM_ SG_ 2365402366 Jstk6XAxsLvrRghtPstvPstnStts "Joystick 6 X-Axis Lever Right Positive Position Status: Reports when the current joystick position is on the positive travel side (forward, right, clockwise, up) relative to the neutral position for that axis of travel. 00b = Not on Positive side of ...";
CM_ SG_ 2365402366 Jstk6XAxsNtrlPstnStts "Joystick 6 X-Axis Neutral Position Status: Reports when the current joystick position is in the neutral position for that axis of travel.  The neutral position measurement must be determined from some mechanism other than the axis position measuremen...";
CM_ SG_ 2365402366 Jstk6YAxsDtntPstnStts "Joystick 6 Y-Axis Detent Position Status: Reports when the current joystick position is in the detent position for that axis of travel.00b = Not in the Detent Position01b = In the Detent Position10b = Error Indicator11b = Not Available";
CM_ SG_ 2365402366 Jstk6YAxsLvrBkNgtvPstnStts "Joystick 6 Y-Axis Lever Back Negative Position Status: Reports when the current joystick position is on the negative travel side (back, left, counterclockwise, down) relative to the neutral position for that axis of travel. 00b = Not on negative side...";
CM_ SG_ 2365402366 Jstk6YAxsLvrFrwrdPstvPstnStts "Joystick 6 Y-Axis Lever Forward Positive Position Status: Reports when the current joystick position is on the positive travel side (forward, right, clockwise, up) relative to the neutral position for that axis of travel. 00b = Not on Positive side o...";
CM_ SG_ 2365402366 Jstk6YAxsNtrlPstnStts "Joystick 6 Y-Axis Neutral Position Status: Reports when the current joystick position is in the neutral position for that axis of travel.  The neutral position measurement must be determined from some mechanism other than the axis position measuremen...";
BA_DEF_ SG_  "SPN" INT 0 524287;
BA_DEF_ BO_  "VFrameFormat" ENUM  "StandardCAN","ExtendedCAN","reserved","J1939PG";
BA_DEF_DEF_  "SPN" 0;
BA_DEF_DEF_  "VFrameFormat" "J1939PG";
BA_ "SPN" SG_ 2364613630 DCDC4HVILStatus 9006;
BA_ "SPN" SG_ 2364613630 DCDC4LoadshedRequest 9007;
BA_ "SPN" SG_ 2364613630 DCDC4OperationalStatus 9005;
BA_ "SPN" SG_ 2364613630 DCDC4PwrLmtdtCnvrtrTmprtr 9014;
BA_ "SPN" SG_ 2364613630 DCDC4PwrLmtdtEltrnFltrTmprtr 9015;
BA_ "SPN" SG_ 2364613630 DCDC4PwrLmtdtHghSdCrrnt 9008;
BA_ "SPN" SG_ 2364613630 DCDC4PwrLmtdtHghSdVltgMnmm 9010;
BA_ "SPN" SG_ 2364613630 DCDC4PwrLmtdtHghSdVltgMxmm 9011;
BA_ "SPN" SG_ 2364613630 DCDC4PwrLmtdtLwSdCrrnt 9009;
BA_ "SPN" SG_ 2364613630 DCDC4PwrLmtdtLwSdVltgMnmm 9012;
BA_ "SPN" SG_ 2364613630 DCDC4PwrLmtdtLwSdVltgMxmm 9013;
BA_ "SPN" SG_ 2364613630 DCDC4PwrLmtdtPwrEltrnsTmprtr 9016;
BA_ "SPN" SG_ 2364613630 DCDC4PwrLmtdtSLIBttrTrmnlCrrnt 9018;
BA_ "SPN" SG_ 2364613630 DCDC4PwrLmtdtSLIBttrTrmnlTmprtr 9019;
BA_ "SPN" SG_ 2364613630 DCDC4PwrLmtdtSLIBttrTrmnlVltg 9017;
BA_ "SPN" SG_ 2364613630 DCDC4PwrLmtdtUndfndRsn 9020;
BA_ "SPN" SG_ 2364613630 DCDC4OperatingStatusCounter 8627;
BA_ "SPN" SG_ 2364613630 DCDC4OperatingStatusCRC 8628;
BA_ "SPN" SG_ 2364613886 DCDC4HighSideCurrent 9024;
BA_ "SPN" SG_ 2364613886 DCDC4HighSideVoltage 9023;
BA_ "SPN" SG_ 2364613886 DCDC4LowSideCurrent 9022;
BA_ "SPN" SG_ 2364613886 DCDC4LowSideVoltage 9021;
BA_ "SPN" SG_ 2364614142 DCDC4SLIBatteryTerminalCurrent 9026;
BA_ "SPN" SG_ 2364614142 DCDC4SLIBatteryTerminalVoltage 9025;
BA_ "SPN" SG_ 2364614142 DCDC4SLIBttrTrmnlTmprtr 9027;
BA_ "SPN" SG_ 2364614398 DCDC4HighSidePower 9029;
BA_ "SPN" SG_ 2364614398 DCDC4LowSidePower 9028;
BA_ "SPN" SG_ 2364614398 DCDC4HghSdNgtvtChsssGrndVltg 9590;
BA_ "SPN" SG_ 2364614654 GradeThresholdIndicator1 9181;
BA_ "SPN" SG_ 2364614654 GradeThresholdIndicator2 9182;
BA_ "SPN" SG_ 2364614654 GradeThresholdIndicator3 9183;
BA_ "SPN" SG_ 2364614654 GradeThresholdIndicator4 9184;
BA_ "SPN" SG_ 2364614654 GradeThresholdIndicator5 9185;
BA_ "SPN" SG_ 2364614654 GradeThresholdIndicator6 9186;
BA_ "SPN" SG_ 2364614910 DCACAssrInvrtr3DCSdCrrnt 9268;
BA_ "SPN" SG_ 2364614910 DCACAssrInvrtr3DCSdPwr 9266;
BA_ "SPN" SG_ 2364614910 DCACAssrInvrtr3DCSdVltg 9267;
BA_ "SPN" SG_ 2364614910 DCACAssIvt3DCSdNtvtCsssGdVt 9584;
BA_ "SPN" SG_ 2364615166 DCACAssrInvrtr3IgntnVltg 9269;
BA_ "SPN" SG_ 2364615166 DCACAssrInvrtr3UnswthdSLIVltg 9270;
BA_ "SPN" SG_ 2364615678 DCACAssrInvrtr4DCSdCrrnt 9298;
BA_ "SPN" SG_ 2364615678 DCACAssrInvrtr4DCSdPwr 9296;
BA_ "SPN" SG_ 2364615678 DCACAssrInvrtr4DCSdVltg 9297;
BA_ "SPN" SG_ 2364615678 DCACAssIvt4DCSdNtvtCsssGdVt 9585;
BA_ "SPN" SG_ 2364615934 DCACAssrInvrtr4IgntnVltg 9299;
BA_ "SPN" SG_ 2364615934 DCACAssrInvrtr4UnswthdSLIVltg 9300;
BA_ "SPN" SG_ 2364616958 DCACAssrInvrtr5DCSdCrrnt 9344;
BA_ "SPN" SG_ 2364616958 DCACAssrInvrtr5DCSdPwr 9342;
BA_ "SPN" SG_ 2364616958 DCACAssrInvrtr5DCSdVltg 9343;
BA_ "SPN" SG_ 2364616958 DCACAssIvt5DCSdNtvtCsssGdVt 9586;
BA_ "SPN" SG_ 2364617214 DCACAssrInvrtr5IgntnVltg 9345;
BA_ "SPN" SG_ 2364617214 DCACAssrInvrtr5UnswthdSLIVltg 9346;
BA_ "SPN" SG_ 2365296894 DCDC4CntrllrInptIgntnVltg 9564;
BA_ "SPN" SG_ 2365296894 DCDC4CntrllrInptUnswthdSLIVltg 9565;
BA_ "SPN" SG_ 2365297150 DCDC3CntrllrInptIgntnVltg 9562;
BA_ "SPN" SG_ 2365297150 DCDC3CntrllrInptUnswthdSLIVltg 9563;
BA_ "SPN" SG_ 2365297406 DCDC2CntrllrInptIgntnVltg 9560;
BA_ "SPN" SG_ 2365297406 DCDC2CntrllrInptUnswthdSLIVltg 9561;
BA_ "SPN" SG_ 2365297662 DCDC1CntrllrInptIgntnVltg 9558;
BA_ "SPN" SG_ 2365297662 DCDC1CntrllrInptUnswthdSLIVltg 9559;
BA_ "SPN" SG_ 2365299454 DCACAssIvt1DCSdCtMLtRqst 9530;
BA_ "SPN" SG_ 2365299454 DCACAssIvt1DCSdCtMxLtRqst 9222;
BA_ "SPN" SG_ 2365299454 DCACAssIvt1DCSdVtMLtRqst 9221;
BA_ "SPN" SG_ 2365299454 DCACAssIvt1DCSdVtMxLtRqst 9529;
BA_ "SPN" SG_ 2365299710 DCACAssIvt1ACSdRMSCtMxLtRqst 9224;
BA_ "SPN" SG_ 2365299710 DCACAssIvt1ACSdRMSVtMxLtRqst 9223;
BA_ "SPN" SG_ 2365299710 DCACAssrInvrtr1ACSdDfltFrqnRqst 9523;
BA_ "SPN" SG_ 2365300734 DCACAssIvt2DCSdCtMLtRqst 9536;
BA_ "SPN" SG_ 2365300734 DCACAssIvt2DCSdCtMxLtRqst 9252;
BA_ "SPN" SG_ 2365300734 DCACAssIvt2DCSdVtMLtRqst 9251;
BA_ "SPN" SG_ 2365300734 DCACAssIvt2DCSdVtMxLtRqst 9535;
BA_ "SPN" SG_ 2365300990 DCACAssIvt2ACSdRMSCtMxLtRqst 9254;
BA_ "SPN" SG_ 2365300990 DCACAssIvt2ACSdRMSVtMxLtRqst 9253;
BA_ "SPN" SG_ 2365300990 DCACAssrInvrtr2ACSdDfltFrqnRqst 9524;
BA_ "SPN" SG_ 2365302014 DCACAssIvt3DCSdCtMLtRqst 9542;
BA_ "SPN" SG_ 2365302014 DCACAssIvt3DCSdCtMxLtRqst 9282;
BA_ "SPN" SG_ 2365302014 DCACAssIvt3DCSdVtMLtRqst 9281;
BA_ "SPN" SG_ 2365302014 DCACAssIvt3DCSdVtMxLtRqst 9541;
BA_ "SPN" SG_ 2365302270 DCACAssIvt3ACSdRMSCtMxLtRqst 9284;
BA_ "SPN" SG_ 2365302270 DCACAssIvt3ACSdRMSVtMxLtRqst 9283;
BA_ "SPN" SG_ 2365302270 DCACAssrInvrtr3ACSdDfltFrqnRqst 9525;
BA_ "SPN" SG_ 2365303294 DCACAssIvt4DCSdCtMLtRqst 9548;
BA_ "SPN" SG_ 2365303294 DCACAssIvt4DCSdCtMxLtRqst 9312;
BA_ "SPN" SG_ 2365303294 DCACAssIvt4DCSdVtMLtRqst 9311;
BA_ "SPN" SG_ 2365303294 DCACAssIvt4DCSdVtMxLtRqst 9547;
BA_ "SPN" SG_ 2365303550 DCACAssIvt4ACSdRMSCtMxLtRqst 9314;
BA_ "SPN" SG_ 2365303550 DCACAssIvt4ACSdRMSVtMxLtRqst 9313;
BA_ "SPN" SG_ 2365303550 DCACAssrInvrtr4ACSdDfltFrqnRqst 9526;
BA_ "SPN" SG_ 2365304574 DCACAssIvt5DCSdCtMLtRqst 9554;
BA_ "SPN" SG_ 2365304574 DCACAssIvt5DCSdCtMxLtRqst 9358;
BA_ "SPN" SG_ 2365304574 DCACAssIvt5DCSdVtMLtRqst 9357;
BA_ "SPN" SG_ 2365304574 DCACAssIvt5DCSdVtMxLtRqst 9553;
BA_ "SPN" SG_ 2365304830 DCACAssIvt5ACSdRMSCtMxLtRqst 9360;
BA_ "SPN" SG_ 2365304830 DCACAssIvt5ACSdRMSVtMxLtRqst 9359;
BA_ "SPN" SG_ 2365304830 DCACAssrInvrtr5ACSdDfltFrqnRqst 9527;
BA_ "SPN" SG_ 2365307646 DCDC4SLIBttrTmprtrMxmmLmtRqst 9045;
BA_ "SPN" SG_ 2365307646 DCDC4SLIBttTCCtMxLtRqst 9044;
BA_ "SPN" SG_ 2365307646 DCDC4SLIBttTVtMxLtRqst 9043;
BA_ "SPN" SG_ 2365307902 DCDC4CnvrtrEltrnFltrTmprtr 9047;
BA_ "SPN" SG_ 2365307902 DCDC4ConverterTemperature 9046;
BA_ "SPN" SG_ 2365307902 DCDC4CoolantInTemperature 9049;
BA_ "SPN" SG_ 2365307902 DCDC4CoolantOutTemperature 9050;
BA_ "SPN" SG_ 2365307902 DCDC4PwrEltrnsTmprtr 9048;
BA_ "SPN" SG_ 2365308158 DCDC4LwSdCrrntMxmmLmtRqst 9053;
BA_ "SPN" SG_ 2365308158 DCDC4LwSdVltgMnmmLmtRqst 9051;
BA_ "SPN" SG_ 2365308158 DCDC4LwSdVltgMxmmLmtRqst 9052;
BA_ "SPN" SG_ 2365308414 DCDC4HghSdCrrntMxmmLmtRqst 9056;
BA_ "SPN" SG_ 2365308414 DCDC4HghSdVltgMnmmLmtRqst 9054;
BA_ "SPN" SG_ 2365308414 DCDC4HghSdVltgMxmmLmtRqst 9055;
BA_ "SPN" SG_ 2365309182 DCDC3SLIBttrTmprtrMxmmLmtRqst 8990;
BA_ "SPN" SG_ 2365309182 DCDC3SLIBttTCCtMxLtRqst 8989;
BA_ "SPN" SG_ 2365309182 DCDC3SLIBttTVtMxLtRqst 8988;
BA_ "SPN" SG_ 2365309438 DCDC3CnvrtrEltrnFltrTmprtr 8992;
BA_ "SPN" SG_ 2365309438 DCDC3ConverterTemperature 8991;
BA_ "SPN" SG_ 2365309438 DCDC3CoolantInTemperature 8994;
BA_ "SPN" SG_ 2365309438 DCDC3CoolantOutTemperature 8995;
BA_ "SPN" SG_ 2365309438 DCDC3PwrEltrnsTmprtr 8993;
BA_ "SPN" SG_ 2365309694 DCDC3LwSdCrrntMxmmLmtRqst 8998;
BA_ "SPN" SG_ 2365309694 DCDC3LwSdVltgMnmmLmtRqst 8996;
BA_ "SPN" SG_ 2365309694 DCDC3LwSdVltgMxmmLmtRqst 8997;
BA_ "SPN" SG_ 2365309950 DCDC3HghSdCrrntMxmmLmtRqst 9001;
BA_ "SPN" SG_ 2365309950 DCDC3HghSdVltgMnmmLmtRqst 8999;
BA_ "SPN" SG_ 2365309950 DCDC3HghSdVltgMxmmLmtRqst 9000;
BA_ "SPN" SG_ 2365310718 DCDC2SLIBttrTmprtrMxmmLmtRqst 8935;
BA_ "SPN" SG_ 2365310718 DCDC2SLIBttTCCtMxLtRqst 8934;
BA_ "SPN" SG_ 2365310718 DCDC2SLIBttTVtMxLtRqst 8933;
BA_ "SPN" SG_ 2365310974 DCDC2CnvrtrEltrnFltrTmprtr 8937;
BA_ "SPN" SG_ 2365310974 DCDC2ConverterTemperature 8936;
BA_ "SPN" SG_ 2365310974 DCDC2CoolantInTemperature 8939;
BA_ "SPN" SG_ 2365310974 DCDC2CoolantOutTemperature 8940;
BA_ "SPN" SG_ 2365310974 DCDC2PwrEltrnsTmprtr 8938;
BA_ "SPN" SG_ 2365311230 DCDC2LwSdCrrntMxmmLmtRqst 8943;
BA_ "SPN" SG_ 2365311230 DCDC2LwSdVltgMnmmLmtRqst 8941;
BA_ "SPN" SG_ 2365311230 DCDC2LwSdVltgMxmmLmtRqst 8942;
BA_ "SPN" SG_ 2365311486 DCDC2HghSdCrrntMxmmLmtRqst 8946;
BA_ "SPN" SG_ 2365311486 DCDC2HghSdVltgMnmmLmtRqst 8944;
BA_ "SPN" SG_ 2365311486 DCDC2HghSdVltgMxmmLmtRqst 8945;
BA_ "SPN" SG_ 2365313534 DCDC1SLIBttrTmprtrMxmmLmtRqst 8819;
BA_ "SPN" SG_ 2365313534 DCDC1SLIBttTCCtMxLtRqst 8818;
BA_ "SPN" SG_ 2365313534 DCDC1SLIBttTVtMxLtRqst 8817;
BA_ "SPN" SG_ 2365315326 DCDC1CnvrtrEltrnFltrTmprtr 8593;
BA_ "SPN" SG_ 2365315326 DCDC1ConverterTemperature 8592;
BA_ "SPN" SG_ 2365315326 DCDC1CoolantInTemperature 8822;
BA_ "SPN" SG_ 2365315326 DCDC1CoolantOutTemperature 8823;
BA_ "SPN" SG_ 2365315326 DCDC1PwrEltrnsTmprtr 8594;
BA_ "SPN" SG_ 2365315582 DCDC1LwSdCrrntMxmmLmtRqst 8568;
BA_ "SPN" SG_ 2365315582 DCDC1LwSdVltgMnmmLmtRqst 8566;
BA_ "SPN" SG_ 2365315582 DCDC1LwSdVltgMxmmLmtRqst 8567;
BA_ "SPN" SG_ 2365315838 DCDC1HghSdCrrntMxmmLmtRqst 8565;
BA_ "SPN" SG_ 2365315838 DCDC1HghSdVltgMnmmLmtRqst 8563;
BA_ "SPN" SG_ 2365315838 DCDC1HghSdVltgMxmmLmtRqst 8564;
BA_ "SPN" SG_ 2365318910 HVESSFanEnableCommand 8384;
BA_ "SPN" SG_ 2365318910 HVESSFanPowerHold 8385;
BA_ "SPN" SG_ 2365318910 HVESSFanSpeedCommand 8386;
BA_ "SPN" SG_ 2365318910 HVESSFanPercentSpeedCommand 8387;
BA_ "SPN" SG_ 2365318910 HVESSFanInstance1 8388;
BA_ "SPN" SG_ 2365318910 HVESSFanInstance2 8389;
BA_ "SPN" SG_ 2365318910 HVESSFanInstance3 8390;
BA_ "SPN" SG_ 2365318910 HVESSFanInstance4 8391;
BA_ "SPN" SG_ 2365318910 HVESSFanInstance5 8392;
BA_ "SPN" SG_ 2365318910 HVESSFanInstance6 8393;
BA_ "SPN" SG_ 2365318910 HVESSFanInstance7 8394;
BA_ "SPN" SG_ 2365318910 HVESSFanInstance8 8395;
BA_ "SPN" SG_ 2365318910 HVESSFanInstance9 8396;
BA_ "SPN" SG_ 2365318910 HVESSFanInstance10 8397;
BA_ "SPN" SG_ 2365318910 HVESSFanInstance11 8398;
BA_ "SPN" SG_ 2365318910 HVESSFanInstance12 8399;
BA_ "SPN" SG_ 2365318910 HVESSFanInstance13 8400;
BA_ "SPN" SG_ 2365318910 HVESSFanInstance14 8401;
BA_ "SPN" SG_ 2365318910 HVESSFanInstance15 8402;
BA_ "SPN" SG_ 2365322238 DirectionalVehicleSpeed 8166;
BA_ "SPN" SG_ 2365346302 LiftAxle1Status 6843;
BA_ "SPN" SG_ 2365346302 LiftAxle2Status 6844;
BA_ "SPN" SG_ 2365346302 LiftAxle3Status 12298;
BA_ "SPN" SG_ 2365346302 LiftAxle4Status 12299;
BA_ "SPN" SG_ 2365348350 EngineLoadShareStatus 6794;
BA_ "SPN" SG_ 2365348350 EngineUnloadStatus 6793;
BA_ "SPN" SG_ 2365363710 EngnClndrPrssrMntr1PrlmnrFMI 6390;
BA_ "SPN" SG_ 2365363710 EngnClndrPrssrMntr2PrlmnrFMI 6391;
BA_ "SPN" SG_ 2365374206 DlClthTrnsmssnCrrntPrsltnGr 5958;
BA_ "SPN" SG_ 2365374206 DlClthTrnsmssnInptShft1Spd 5960;
BA_ "SPN" SG_ 2365374206 DlClthTrnsmssnInptShft2Spd 5961;
BA_ "SPN" SG_ 2365374206 DlClthTrnsmssnSltdPrsltnGr 5957;
BA_ "SPN" SG_ 2365393662 Aftrtrtmnt2OtltCrrtdNOx 7352;
BA_ "SPN" SG_ 2365393662 Aftrtrtmnt2OtltNOxSnsrNH3Crrtn 5051;
BA_ "SPN" SG_ 2365393662 Aftrtrtmnt2OtltNOxSnsrNO2Crrtn 5050;
BA_ "SPN" SG_ 2365393662 Atttt2OttNOxSsNOxPssCt 5049;
BA_ "SPN" SG_ 2365393662 Atttt2OttNOxSsO2PssCt 5048;
BA_ "SPN" SG_ 2365393662 Atttt2OttNOxSsSdssFRst 5719;
BA_ "SPN" SG_ 2365393918 Aftrtrtmnt2OtltNOxSnsrHtrRt 5045;
BA_ "SPN" SG_ 2365393918 Aftrtrtmnt2OtltNOxSnsrOprtnHrs 5723;
BA_ "SPN" SG_ 2365393918 Atttt2OttNOxSsNwptdvtNOxG 5046;
BA_ "SPN" SG_ 2365393918 Atttt2OttNOxSsNwptdvtNOxOst 5047;
BA_ "SPN" SG_ 2365394174 EngineExhaust2CorrectedNox 7354;
BA_ "SPN" SG_ 2365394174 EngnExhst2NOxSnsrO2PrssrCrrtn 5041;
BA_ "SPN" SG_ 2365394174 EngnExhst2NOxSnsrNOxPrssrCrrtn 5042;
BA_ "SPN" SG_ 2365394174 EngnExhst2NOxSnsrNO2Crrtn 5043;
BA_ "SPN" SG_ 2365394174 EngnExhst2NOxSnsrNH3Crrtn 5044;
BA_ "SPN" SG_ 2365394174 EExst2NOxSsSdssFRst 5720;
BA_ "SPN" SG_ 2365394430 EngnExhst2NOxSnsrHtrRt 5038;
BA_ "SPN" SG_ 2365394430 EngnExhst2NOxSnsrNwPrtDvtnNOxGn 5039;
BA_ "SPN" SG_ 2365394430 EExst2NOxSsNwPtDvtNOxOst 5040;
BA_ "SPN" SG_ 2365394430 EngnExhst2NOxSnsrOprtnHrs 5724;
BA_ "SPN" SG_ 2365394686 Aftrtrtmnt1OtltCrrtdNOx 7351;
BA_ "SPN" SG_ 2365394686 Aftrtrtmnt1OtltNOxSnsrNH3Crrtn 5037;
BA_ "SPN" SG_ 2365394686 Aftrtrtmnt1OtltNOxSnsrNO2Crrtn 5036;
BA_ "SPN" SG_ 2365394686 Atttt1OttNOxSsNOxPssCt 5035;
BA_ "SPN" SG_ 2365394686 Atttt1OttNOxSsO2PssCt 5034;
BA_ "SPN" SG_ 2365394686 Atttt1OttNOxSsSdssFRst 5717;
BA_ "SPN" SG_ 2365394942 Aftrtrtmnt1OtltNOxSnsrHtrRt 5031;
BA_ "SPN" SG_ 2365394942 Aftrtrtmnt1OtltNOxSnsrOprtnHrs 5721;
BA_ "SPN" SG_ 2365394942 Atttt1OttNOxSsNwptdvtNOxG 5032;
BA_ "SPN" SG_ 2365394942 Atttt1OttNOxSsNwptdvtNOxOst 5033;
BA_ "SPN" SG_ 2365395198 EExst1NOxSsSdssFRst 5718;
BA_ "SPN" SG_ 2365395198 EngineExhaust1CorrectedNox 7353;
BA_ "SPN" SG_ 2365395198 EngnExhst1NOxSnsrNH3Crrtn 5030;
BA_ "SPN" SG_ 2365395198 EngnExhst1NOxSnsrNO2Crrtn 5029;
BA_ "SPN" SG_ 2365395198 EngnExhst1NOxSnsrNOxPrssrCrrtn 5028;
BA_ "SPN" SG_ 2365395198 EngnExhst1NOxSnsrO2PrssrCrrtn 5027;
BA_ "SPN" SG_ 2365395454 EExst1NOxSsNwptdvtNOxOst 5026;
BA_ "SPN" SG_ 2365395454 EngnExhst1NOxSnsrHtrRt 5024;
BA_ "SPN" SG_ 2365395454 EngnExhst1NOxSnsrNwprtdvtnNOxGn 5025;
BA_ "SPN" SG_ 2365395454 EngnExhst1NOxSnsrOprtnHrs 5722;
BA_ "SPN" SG_ 2365400062 Joystick10Button13PressedStatus 6767;
BA_ "SPN" SG_ 2365400062 Joystick10Button14PressedStatus 6768;
BA_ "SPN" SG_ 2365400062 Joystick10Button15PressedStatus 6769;
BA_ "SPN" SG_ 2365400062 Joystick10Button16PressedStatus 6770;
BA_ "SPN" SG_ 2365400062 Joystick10GripXAxisPosition 4738;
BA_ "SPN" SG_ 2365400062 Joystick10GripYAxisPosition 4742;
BA_ "SPN" SG_ 2365400062 Joystick10ThetaAxisPosition 4746;
BA_ "SPN" SG_ 2365400062 Jst10GpXAxsLvRtPstvPstStts 4737;
BA_ "SPN" SG_ 2365400062 Jst10GpYAxsLvFwdPstvPstStts 4741;
BA_ "SPN" SG_ 2365400062 Jst10TtAxsCtCwsNtvPstStts 4744;
BA_ "SPN" SG_ 2365400062 Jstk10GrpXAxsDtntPstnStts 4749;
BA_ "SPN" SG_ 2365400062 Jstk10GrpXAxsLvrLftNgtvPstnStts 4736;
BA_ "SPN" SG_ 2365400062 Jstk10GrpXAxsNtrlPstnStts 4735;
BA_ "SPN" SG_ 2365400062 Jstk10GrpYAxsDtntPstnStts 4748;
BA_ "SPN" SG_ 2365400062 Jstk10GrpYAxsLvrBkNgtvPstnStts 4740;
BA_ "SPN" SG_ 2365400062 Jstk10GrpYAxsNtrlPstnStts 4739;
BA_ "SPN" SG_ 2365400062 Jstk10ThtAxsClkwsPstvPstnStts 4745;
BA_ "SPN" SG_ 2365400062 Jstk10ThtAxsDtntPstnStts 4747;
BA_ "SPN" SG_ 2365400062 Jstk10ThtAxsNtrlPstnStts 4743;
BA_ "SPN" SG_ 2365400318 Joystick10Button10PressedStatus 4733;
BA_ "SPN" SG_ 2365400318 Joystick10Button11PressedStatus 4732;
BA_ "SPN" SG_ 2365400318 Joystick10Button12PressedStatus 4731;
BA_ "SPN" SG_ 2365400318 Joystick10Button1PressedStatus 4726;
BA_ "SPN" SG_ 2365400318 Joystick10Button2PressedStatus 4725;
BA_ "SPN" SG_ 2365400318 Joystick10Button3PressedStatus 4724;
BA_ "SPN" SG_ 2365400318 Joystick10Button4PressedStatus 4723;
BA_ "SPN" SG_ 2365400318 Joystick10Button5PressedStatus 4730;
BA_ "SPN" SG_ 2365400318 Joystick10Button6PressedStatus 4729;
BA_ "SPN" SG_ 2365400318 Joystick10Button7PressedStatus 4728;
BA_ "SPN" SG_ 2365400318 Joystick10Button8PressedStatus 4727;
BA_ "SPN" SG_ 2365400318 Joystick10Button9PressedStatus 4734;
BA_ "SPN" SG_ 2365400318 Joystick10XAxisPosition 4716;
BA_ "SPN" SG_ 2365400318 Joystick10YAxisPosition 4720;
BA_ "SPN" SG_ 2365400318 Jstk10XAxsDtntPstnStts 4722;
BA_ "SPN" SG_ 2365400318 Jstk10XAxsLvrLftNgtvPstnStts 4714;
BA_ "SPN" SG_ 2365400318 Jstk10XAxsLvrRghtPstvPstnStts 4715;
BA_ "SPN" SG_ 2365400318 Jstk10XAxsNtrlPstnStts 4713;
BA_ "SPN" SG_ 2365400318 Jstk10YAxsDtntPstnStts 4721;
BA_ "SPN" SG_ 2365400318 Jstk10YAxsLvrBkNgtvPstnStts 4718;
BA_ "SPN" SG_ 2365400318 Jstk10YAxsLvrFrwrdPstvPstnStts 4719;
BA_ "SPN" SG_ 2365400318 Jstk10YAxsNtrlPstnStts 4717;
BA_ "SPN" SG_ 2365400574 Joystick9Button13PressedStatus 6763;
BA_ "SPN" SG_ 2365400574 Joystick9Button14PressedStatus 6764;
BA_ "SPN" SG_ 2365400574 Joystick9Button15PressedStatus 6765;
BA_ "SPN" SG_ 2365400574 Joystick9Button16PressedStatus 6766;
BA_ "SPN" SG_ 2365400574 Joystick9GripXAxisPosition 4701;
BA_ "SPN" SG_ 2365400574 Joystick9GripYAxisPosition 4705;
BA_ "SPN" SG_ 2365400574 Joystick9ThetaAxisPosition 4709;
BA_ "SPN" SG_ 2365400574 Jst9GpYAxsLvFwdPstvPstStts 4704;
BA_ "SPN" SG_ 2365400574 Jst9TtAxsCtCwsNtvPstStts 4707;
BA_ "SPN" SG_ 2365400574 Jstk9GrpXAxsDtntPstnStts 4712;
BA_ "SPN" SG_ 2365400574 Jstk9GrpXAxsLvrLftNgtvPstnStts 4699;
BA_ "SPN" SG_ 2365400574 Jstk9GrpXAxsLvrRghtPstvPstnStts 4700;
BA_ "SPN" SG_ 2365400574 Jstk9GrpXAxsNtrlPstnStts 4698;
BA_ "SPN" SG_ 2365400574 Jstk9GrpYAxsDtntPstnStts 4711;
BA_ "SPN" SG_ 2365400574 Jstk9GrpYAxsLvrBkNgtvPstnStts 4703;
BA_ "SPN" SG_ 2365400574 Jstk9GrpYAxsNtrlPstnStts 4702;
BA_ "SPN" SG_ 2365400574 Jstk9ThtAxsClkwsPstvPstnStts 4708;
BA_ "SPN" SG_ 2365400574 Jstk9ThtAxsDtntPstnStts 4710;
BA_ "SPN" SG_ 2365400574 Jstk9ThtAxsNtrlPstnStts 4706;
BA_ "SPN" SG_ 2365400830 Joystick9Button10PressedStatus 4696;
BA_ "SPN" SG_ 2365400830 Joystick9Button11PressedStatus 4695;
BA_ "SPN" SG_ 2365400830 Joystick9Button12PressedStatus 4694;
BA_ "SPN" SG_ 2365400830 Joystick9Button1PressedStatus 4689;
BA_ "SPN" SG_ 2365400830 Joystick9Button2PressedStatus 4688;
BA_ "SPN" SG_ 2365400830 Joystick9Button3PressedStatus 4687;
BA_ "SPN" SG_ 2365400830 Joystick9Button4PressedStatus 4686;
BA_ "SPN" SG_ 2365400830 Joystick9Button5PressedStatus 4693;
BA_ "SPN" SG_ 2365400830 Joystick9Button6PressedStatus 4692;
BA_ "SPN" SG_ 2365400830 Joystick9Button7PressedStatus 4691;
BA_ "SPN" SG_ 2365400830 Joystick9Button8PressedStatus 4690;
BA_ "SPN" SG_ 2365400830 Joystick9Button9PressedStatus 4697;
BA_ "SPN" SG_ 2365400830 Joystick9XAxisPosition 4679;
BA_ "SPN" SG_ 2365400830 Joystick9YAxisPosition 4683;
BA_ "SPN" SG_ 2365400830 Jstk9XAxsDtntPstnStts 4685;
BA_ "SPN" SG_ 2365400830 Jstk9XAxsLvrLftNgtvPstnStts 4677;
BA_ "SPN" SG_ 2365400830 Jstk9XAxsLvrRghtPstvPstnStts 4678;
BA_ "SPN" SG_ 2365400830 Jstk9XAxsNtrlPstnStts 4676;
BA_ "SPN" SG_ 2365400830 Jstk9YAxsDtntPstnStts 4684;
BA_ "SPN" SG_ 2365400830 Jstk9YAxsLvrBkNgtvPstnStts 4681;
BA_ "SPN" SG_ 2365400830 Jstk9YAxsLvrFrwrdPstvPstnStts 4682;
BA_ "SPN" SG_ 2365400830 Jstk9YAxsNtrlPstnStts 4680;
BA_ "SPN" SG_ 2365401086 Joystick8Button13PressedStatus 6759;
BA_ "SPN" SG_ 2365401086 Joystick8Button14PressedStatus 6760;
BA_ "SPN" SG_ 2365401086 Joystick8Button15PressedStatus 6761;
BA_ "SPN" SG_ 2365401086 Joystick8Button16PressedStatus 6762;
BA_ "SPN" SG_ 2365401086 Joystick8GripXAxisPosition 4664;
BA_ "SPN" SG_ 2365401086 Joystick8GripYAxisPosition 4668;
BA_ "SPN" SG_ 2365401086 Joystick8ThetaAxisPosition 4672;
BA_ "SPN" SG_ 2365401086 Jst8GpYAxsLvFwdPstvPstStts 4667;
BA_ "SPN" SG_ 2365401086 Jst8TtAxsCtCwsNtvPstStts 4670;
BA_ "SPN" SG_ 2365401086 Jstk8GrpXAxsDtntPstnStts 4675;
BA_ "SPN" SG_ 2365401086 Jstk8GrpXAxsLvrLftNgtvPstnStts 4662;
BA_ "SPN" SG_ 2365401086 Jstk8GrpXAxsLvrRghtPstvPstnStts 4663;
BA_ "SPN" SG_ 2365401086 Jstk8GrpXAxsNtrlPstnStts 4661;
BA_ "SPN" SG_ 2365401086 Jstk8GrpYAxsDtntPstnStts 4674;
BA_ "SPN" SG_ 2365401086 Jstk8GrpYAxsLvrBkNgtvPstnStts 4666;
BA_ "SPN" SG_ 2365401086 Jstk8GrpYAxsNtrlPstnStts 4665;
BA_ "SPN" SG_ 2365401086 Jstk8ThtAxsClkwsPstvPstnStts 4671;
BA_ "SPN" SG_ 2365401086 Jstk8ThtAxsDtntPstnStts 4673;
BA_ "SPN" SG_ 2365401086 Jstk8ThtAxsNtrlPstnStts 4669;
BA_ "SPN" SG_ 2365401342 Joystick8Button10PressedStatus 4659;
BA_ "SPN" SG_ 2365401342 Joystick8Button11PressedStatus 4658;
BA_ "SPN" SG_ 2365401342 Joystick8Button12PressedStatus 4657;
BA_ "SPN" SG_ 2365401342 Joystick8Button1PressedStatus 4652;
BA_ "SPN" SG_ 2365401342 Joystick8Button2PressedStatus 4651;
BA_ "SPN" SG_ 2365401342 Joystick8Button3PressedStatus 4650;
BA_ "SPN" SG_ 2365401342 Joystick8Button4PressedStatus 4649;
BA_ "SPN" SG_ 2365401342 Joystick8Button5PressedStatus 4656;
BA_ "SPN" SG_ 2365401342 Joystick8Button6PressedStatus 4655;
BA_ "SPN" SG_ 2365401342 Joystick8Button7PressedStatus 4654;
BA_ "SPN" SG_ 2365401342 Joystick8Button8PressedStatus 4653;
BA_ "SPN" SG_ 2365401342 Joystick8Button9PressedStatus 4660;
BA_ "SPN" SG_ 2365401342 Joystick8XAxisPosition 4642;
BA_ "SPN" SG_ 2365401342 Joystick8YAxisPosition 4646;
BA_ "SPN" SG_ 2365401342 Jstk8XAxsDtntPstnStts 4648;
BA_ "SPN" SG_ 2365401342 Jstk8XAxsLvrLftNgtvPstnStts 4640;
BA_ "SPN" SG_ 2365401342 Jstk8XAxsLvrRghtPstvPstnStts 4641;
BA_ "SPN" SG_ 2365401342 Jstk8XAxsNtrlPstnStts 4639;
BA_ "SPN" SG_ 2365401342 Jstk8YAxsDtntPstnStts 4647;
BA_ "SPN" SG_ 2365401342 Jstk8YAxsLvrBkNgtvPstnStts 4644;
BA_ "SPN" SG_ 2365401342 Jstk8YAxsLvrFrwrdPstvPstnStts 4645;
BA_ "SPN" SG_ 2365401342 Jstk8YAxsNtrlPstnStts 4643;
BA_ "SPN" SG_ 2365401598 Joystick7Button13PressedStatus 6755;
BA_ "SPN" SG_ 2365401598 Joystick7Button14PressedStatus 6756;
BA_ "SPN" SG_ 2365401598 Joystick7Button15PressedStatus 6757;
BA_ "SPN" SG_ 2365401598 Joystick7Button16PressedStatus 6758;
BA_ "SPN" SG_ 2365401598 Joystick7GripXAxisPosition 4627;
BA_ "SPN" SG_ 2365401598 Joystick7GripYAxisPosition 4631;
BA_ "SPN" SG_ 2365401598 Joystick7ThetaAxisPosition 4635;
BA_ "SPN" SG_ 2365401598 Jst7GpYAxsLvFwdPstvPstStts 4630;
BA_ "SPN" SG_ 2365401598 Jst7TtAxsCtCwsNtvPstStts 4633;
BA_ "SPN" SG_ 2365401598 Jstk7GrpXAxsDtntPstnStts 4638;
BA_ "SPN" SG_ 2365401598 Jstk7GrpXAxsLvrLftNgtvPstnStts 4625;
BA_ "SPN" SG_ 2365401598 Jstk7GrpXAxsLvrRghtPstvPstnStts 4626;
BA_ "SPN" SG_ 2365401598 Jstk7GrpXAxsNtrlPstnStts 4624;
BA_ "SPN" SG_ 2365401598 Jstk7GrpYAxsDtntPstnStts 4637;
BA_ "SPN" SG_ 2365401598 Jstk7GrpYAxsLvrBkNgtvPstnStts 4629;
BA_ "SPN" SG_ 2365401598 Jstk7GrpYAxsNtrlPstnStts 4628;
BA_ "SPN" SG_ 2365401598 Jstk7ThtAxsClkwsPstvPstnStts 4634;
BA_ "SPN" SG_ 2365401598 Jstk7ThtAxsDtntPstnStts 4636;
BA_ "SPN" SG_ 2365401598 Jstk7ThtAxsNtrlPstnStts 4632;
BA_ "SPN" SG_ 2365401854 Joystick7Button10PressedStatus 4622;
BA_ "SPN" SG_ 2365401854 Joystick7Button11PressedStatus 4621;
BA_ "SPN" SG_ 2365401854 Joystick7Button12PressedStatus 4620;
BA_ "SPN" SG_ 2365401854 Joystick7Button1PressedStatus 4615;
BA_ "SPN" SG_ 2365401854 Joystick7Button2PressedStatus 4614;
BA_ "SPN" SG_ 2365401854 Joystick7Button3PressedStatus 4613;
BA_ "SPN" SG_ 2365401854 Joystick7Button4PressedStatus 4612;
BA_ "SPN" SG_ 2365401854 Joystick7Button5PressedStatus 4619;
BA_ "SPN" SG_ 2365401854 Joystick7Button6PressedStatus 4618;
BA_ "SPN" SG_ 2365401854 Joystick7Button7PressedStatus 4617;
BA_ "SPN" SG_ 2365401854 Joystick7Button8PressedStatus 4616;
BA_ "SPN" SG_ 2365401854 Joystick7Button9PressedStatus 4623;
BA_ "SPN" SG_ 2365401854 Joystick7XAxisPosition 4605;
BA_ "SPN" SG_ 2365401854 Joystick7YAxisPosition 4609;
BA_ "SPN" SG_ 2365401854 Jstk7XAxsDtntPstnStts 4611;
BA_ "SPN" SG_ 2365401854 Jstk7XAxsLvrLftNgtvPstnStts 4603;
BA_ "SPN" SG_ 2365401854 Jstk7XAxsLvrRghtPstvPstnStts 4604;
BA_ "SPN" SG_ 2365401854 Jstk7XAxsNtrlPstnStts 4602;
BA_ "SPN" SG_ 2365401854 Jstk7YAxsDtntPstnStts 4610;
BA_ "SPN" SG_ 2365401854 Jstk7YAxsLvrBkNgtvPstnStts 4607;
BA_ "SPN" SG_ 2365401854 Jstk7YAxsLvrFrwrdPstvPstnStts 4608;
BA_ "SPN" SG_ 2365401854 Jstk7YAxsNtrlPstnStts 4606;
BA_ "SPN" SG_ 2365402110 Joystick6Button13PressedStatus 6751;
BA_ "SPN" SG_ 2365402110 Joystick6Button14PressedStatus 6752;
BA_ "SPN" SG_ 2365402110 Joystick6Button15PressedStatus 6753;
BA_ "SPN" SG_ 2365402110 Joystick6Button16PressedStatus 6754;
BA_ "SPN" SG_ 2365402110 Joystick6GripXAxisPosition 4590;
BA_ "SPN" SG_ 2365402110 Joystick6GripYAxisPosition 4594;
BA_ "SPN" SG_ 2365402110 Joystick6ThetaAxisPosition 4598;
BA_ "SPN" SG_ 2365402110 Jst6GpYAxsLvFwdPstvPstStts 4593;
BA_ "SPN" SG_ 2365402110 Jst6TtAxsCtCwsNtvPstStts 4596;
BA_ "SPN" SG_ 2365402110 Jstk6GrpXAxsDtntPstnStts 4601;
BA_ "SPN" SG_ 2365402110 Jstk6GrpXAxsLvrLftNgtvPstnStts 4588;
BA_ "SPN" SG_ 2365402110 Jstk6GrpXAxsLvrRghtPstvPstnStts 4589;
BA_ "SPN" SG_ 2365402110 Jstk6GrpXAxsNtrlPstnStts 4587;
BA_ "SPN" SG_ 2365402110 Jstk6GrpYAxsDtntPstnStts 4600;
BA_ "SPN" SG_ 2365402110 Jstk6GrpYAxsLvrBkNgtvPstnStts 4592;
BA_ "SPN" SG_ 2365402110 Jstk6GrpYAxsNtrlPstnStts 4591;
BA_ "SPN" SG_ 2365402110 Jstk6ThtAxsClkwsPstvPstnStts 4597;
BA_ "SPN" SG_ 2365402110 Jstk6ThtAxsDtntPstnStts 4599;
BA_ "SPN" SG_ 2365402110 Jstk6ThtAxsNtrlPstnStts 4595;
BA_ "SPN" SG_ 2365402366 Joystick6Button10PressedStatus 4585;
BA_ "SPN" SG_ 2365402366 Joystick6Button11PressedStatus 4584;
BA_ "SPN" SG_ 2365402366 Joystick6Button12PressedStatus 4583;
BA_ "SPN" SG_ 2365402366 Joystick6Button1PressedStatus 4578;
BA_ "SPN" SG_ 2365402366 Joystick6Button2PressedStatus 4577;
BA_ "SPN" SG_ 2365402366 Joystick6Button3PressedStatus 4576;
BA_ "SPN" SG_ 2365402366 Joystick6Button4PressedStatus 4575;
BA_ "SPN" SG_ 2365402366 Joystick6Button5PressedStatus 4582;
BA_ "SPN" SG_ 2365402366 Joystick6Button6PressedStatus 4581;
BA_ "SPN" SG_ 2365402366 Joystick6Button7PressedStatus 4580;
BA_ "SPN" SG_ 2365402366 Joystick6Button8PressedStatus 4579;
BA_ "SPN" SG_ 2365402366 Joystick6Button9PressedStatus 4586;
BA_ "SPN" SG_ 2365402366 Joystick6XAxisPosition 4568;
BA_ "SPN" SG_ 2365402366 Joystick6YAxisPosition 4572;
BA_ "SPN" SG_ 2365402366 Jstk6XAxsDtntPstnStts 4574;
BA_ "SPN" SG_ 2365402366 Jstk6XAxsLvrLftNgtvPstnStts 4566;
BA_ "SPN" SG_ 2365402366 Jstk6XAxsLvrRghtPstvPstnStts 4567;
BA_ "SPN" SG_ 2365402366 Jstk6XAxsNtrlPstnStts 4565;
BA_ "SPN" SG_ 2365402366 Jstk6YAxsDtntPstnStts 4573;
BA_ "SPN" SG_ 2365402366 Jstk6YAxsLvrBkNgtvPstnStts 4570;
BA_ "SPN" SG_ 2365402366 Jstk6YAxsLvrFrwrdPstvPstnStts 4571;
BA_ "SPN" SG_ 2365402366 Jstk6YAxsNtrlPstnStts 4569;
VAL_ 2365400318 Joystick10Button10PressedStatus 3 "NotAvailable" 2 "ErrorIndicator" 1 "ButtonPressed" 0 "ButtonNotPressed" ;
VAL_ 2365400318 Joystick10Button11PressedStatus 3 "NotAvailable" 2 "ErrorIndicator" 1 "ButtonPressed" 0 "ButtonNotPressed" ;
VAL_ 2365400318 Joystick10Button12PressedStatus 3 "NotAvailable" 2 "ErrorIndicator" 1 "ButtonPressed" 0 "ButtonNotPressed" ;
VAL_ 2365400318 Joystick10Button1PressedStatus 3 "NotAvailable" 2 "ErrorIndicator" 1 "ButtonPressed" 0 "ButtonNotPressed" ;
VAL_ 2365400318 Joystick10Button2PressedStatus 3 "NotAvailable" 2 "ErrorIndicator" 1 "ButtonPressed" 0 "ButtonNotPressed" ;
VAL_ 2365400318 Joystick10Button3PressedStatus 3 "NotAvailable" 2 "ErrorIndicator" 1 "ButtonPressed" 0 "ButtonNotPressed" ;
VAL_ 2365400318 Joystick10Button4PressedStatus 3 "NotAvailable" 2 "ErrorIndicator" 1 "ButtonPressed" 0 "ButtonNotPressed" ;
VAL_ 2365400318 Joystick10Button5PressedStatus 3 "NotAvailable" 2 "ErrorIndicator" 1 "ButtonPressed" 0 "ButtonNotPressed" ;
VAL_ 2365400318 Joystick10Button6PressedStatus 3 "NotAvailable" 2 "ErrorIndicator" 1 "ButtonPressed" 0 "ButtonNotPressed" ;
VAL_ 2365400318 Joystick10Button7PressedStatus 3 "NotAvailable" 2 "ErrorIndicator" 1 "ButtonPressed" 0 "ButtonNotPressed" ;
VAL_ 2365400318 Joystick10Button8PressedStatus 3 "NotAvailable" 2 "ErrorIndicator" 1 "ButtonPressed" 0 "ButtonNotPressed" ;
VAL_ 2365400318 Joystick10Button9PressedStatus 3 "NotAvailable" 2 "ErrorIndicator" 1 "ButtonPressed" 0 "ButtonNotPressed" ;
VAL_ 2365400830 Joystick9Button10PressedStatus 3 "NotAvailable" 2 "ErrorIndicator" 1 "ButtonPressed" 0 "ButtonNotPressed" ;
VAL_ 2365400830 Joystick9Button11PressedStatus 3 "NotAvailable" 2 "ErrorIndicator" 1 "ButtonPressed" 0 "ButtonNotPressed" ;
VAL_ 2365400830 Joystick9Button12PressedStatus 3 "NotAvailable" 2 "ErrorIndicator" 1 "ButtonPressed" 0 "ButtonNotPressed" ;
VAL_ 2365400830 Joystick9Button1PressedStatus 3 "NotAvailable" 2 "ErrorIndicator" 1 "ButtonPressed" 0 "ButtonNotPressed" ;
VAL_ 2365400830 Joystick9Button2PressedStatus 3 "NotAvailable" 2 "ErrorIndicator" 1 "ButtonPressed" 0 "ButtonNotPressed" ;
VAL_ 2365400830 Joystick9Button3PressedStatus 3 "NotAvailable" 2 "ErrorIndicator" 1 "ButtonPressed" 0 "ButtonNotPressed" ;
VAL_ 2365400830 Joystick9Button4PressedStatus 3 "NotAvailable" 2 "ErrorIndicator" 1 "ButtonPressed" 0 "ButtonNotPressed" ;
VAL_ 2365400830 Joystick9Button5PressedStatus 3 "NotAvailable" 2 "ErrorIndicator" 1 "ButtonPressed" 0 "ButtonNotPressed" ;
VAL_ 2365400830 Joystick9Button6PressedStatus 3 "NotAvailable" 2 "ErrorIndicator" 1 "ButtonPressed" 0 "ButtonNotPressed" ;
VAL_ 2365400830 Joystick9Button7PressedStatus 3 "NotAvailable" 2 "ErrorIndicator" 1 "ButtonPressed" 0 "ButtonNotPressed" ;
VAL_ 2365400830 Joystick9Button8PressedStatus 3 "NotAvailable" 2 "ErrorIndicator" 1 "ButtonPressed" 0 "ButtonNotPressed" ;
VAL_ 2365400830 Joystick9Button9PressedStatus 3 "NotAvailable" 2 "ErrorIndicator" 1 "ButtonPressed" 0 "ButtonNotPressed" ;
VAL_ 2365401342 Joystick8Button10PressedStatus 3 "NotAvailable" 2 "ErrorIndicator" 1 "ButtonPressed" 0 "ButtonNotPressed" ;
VAL_ 2365401342 Joystick8Button11PressedStatus 3 "NotAvailable" 2 "ErrorIndicator" 1 "ButtonPressed" 0 "ButtonNotPressed" ;
VAL_ 2365401342 Joystick8Button12PressedStatus 3 "NotAvailable" 2 "ErrorIndicator" 1 "ButtonPressed" 0 "ButtonNotPressed" ;
VAL_ 2365401342 Joystick8Button1PressedStatus 3 "NotAvailable" 2 "ErrorIndicator" 1 "ButtonPressed" 0 "ButtonNotPressed" ;
VAL_ 2365401342 Joystick8Button2PressedStatus 3 "NotAvailable" 2 "ErrorIndicator" 1 "ButtonPressed" 0 "ButtonNotPressed" ;
VAL_ 2365401342 Joystick8Button3PressedStatus 3 "NotAvailable" 2 "ErrorIndicator" 1 "ButtonPressed" 0 "ButtonNotPressed" ;
VAL_ 2365401342 Joystick8Button4PressedStatus 3 "NotAvailable" 2 "ErrorIndicator" 1 "ButtonPressed" 0 "ButtonNotPressed" ;
VAL_ 2365401342 Joystick8Button5PressedStatus 3 "NotAvailable" 2 "ErrorIndicator" 1 "ButtonPressed" 0 "ButtonNotPressed" ;
VAL_ 2365401342 Joystick8Button6PressedStatus 3 "NotAvailable" 2 "ErrorIndicator" 1 "ButtonPressed" 0 "ButtonNotPressed" ;
VAL_ 2365401342 Joystick8Button7PressedStatus 3 "NotAvailable" 2 "ErrorIndicator" 1 "ButtonPressed" 0 "ButtonNotPressed" ;
VAL_ 2365401342 Joystick8Button8PressedStatus 3 "NotAvailable" 2 "ErrorIndicator" 1 "ButtonPressed" 0 "ButtonNotPressed" ;
VAL_ 2365401342 Joystick8Button9PressedStatus 3 "NotAvailable" 2 "ErrorIndicator" 1 "ButtonPressed" 0 "ButtonNotPressed" ;
VAL_ 2365401854 Joystick7Button10PressedStatus 3 "NotAvailable" 2 "ErrorIndicator" 1 "ButtonPressed" 0 "ButtonNotPressed" ;
VAL_ 2365401854 Joystick7Button11PressedStatus 3 "NotAvailable" 2 "ErrorIndicator" 1 "ButtonPressed" 0 "ButtonNotPressed" ;
VAL_ 2365401854 Joystick7Button12PressedStatus 3 "NotAvailable" 2 "ErrorIndicator" 1 "ButtonPressed" 0 "ButtonNotPressed" ;
VAL_ 2365401854 Joystick7Button1PressedStatus 3 "NotAvailable" 2 "ErrorIndicator" 1 "ButtonPressed" 0 "ButtonNotPressed" ;
VAL_ 2365401854 Joystick7Button2PressedStatus 3 "NotAvailable" 2 "ErrorIndicator" 1 "ButtonPressed" 0 "ButtonNotPressed" ;
VAL_ 2365401854 Joystick7Button3PressedStatus 3 "NotAvailable" 2 "ErrorIndicator" 1 "ButtonPressed" 0 "ButtonNotPressed" ;
VAL_ 2365401854 Joystick7Button4PressedStatus 3 "NotAvailable" 2 "ErrorIndicator" 1 "ButtonPressed" 0 "ButtonNotPressed" ;
VAL_ 2365401854 Joystick7Button5PressedStatus 3 "NotAvailable" 2 "ErrorIndicator" 1 "ButtonPressed" 0 "ButtonNotPressed" ;
VAL_ 2365401854 Joystick7Button6PressedStatus 3 "NotAvailable" 2 "ErrorIndicator" 1 "ButtonPressed" 0 "ButtonNotPressed" ;
VAL_ 2365401854 Joystick7Button7PressedStatus 3 "NotAvailable" 2 "ErrorIndicator" 1 "ButtonPressed" 0 "ButtonNotPressed" ;
VAL_ 2365401854 Joystick7Button8PressedStatus 3 "NotAvailable" 2 "ErrorIndicator" 1 "ButtonPressed" 0 "ButtonNotPressed" ;
VAL_ 2365401854 Joystick7Button9PressedStatus 3 "NotAvailable" 2 "ErrorIndicator" 1 "ButtonPressed" 0 "ButtonNotPressed" ;
VAL_ 2365402366 Joystick6Button10PressedStatus 3 "NotAvailable" 2 "ErrorIndicator" 1 "ButtonPressed" 0 "ButtonNotPressed" ;
VAL_ 2365402366 Joystick6Button11PressedStatus 3 "NotAvailable" 2 "ErrorIndicator" 1 "ButtonPressed" 0 "ButtonNotPressed" ;
VAL_ 2365402366 Joystick6Button12PressedStatus 3 "NotAvailable" 2 "ErrorIndicator" 1 "ButtonPressed" 0 "ButtonNotPressed" ;
VAL_ 2365402366 Joystick6Button1PressedStatus 3 "NotAvailable" 2 "ErrorIndicator" 1 "ButtonPressed" 0 "ButtonNotPressed" ;
VAL_ 2365402366 Joystick6Button2PressedStatus 3 "NotAvailable" 2 "ErrorIndicator" 1 "ButtonPressed" 0 "ButtonNotPressed" ;
VAL_ 2365402366 Joystick6Button3PressedStatus 3 "NotAvailable" 2 "ErrorIndicator" 1 "ButtonPressed" 0 "ButtonNotPressed" ;
VAL_ 2365402366 Joystick6Button4PressedStatus 3 "NotAvailable" 2 "ErrorIndicator" 1 "ButtonPressed" 0 "ButtonNotPressed" ;
VAL_ 2365402366 Joystick6Button5PressedStatus 3 "NotAvailable" 2 "ErrorIndicator" 1 "ButtonPressed" 0 "ButtonNotPressed" ;
VAL_ 2365402366 Joystick6Button6PressedStatus 3 "NotAvailable" 2 "ErrorIndicator" 1 "ButtonPressed" 0 "ButtonNotPressed" ;
VAL_ 2365402366 Joystick6Button7PressedStatus 3 "NotAvailable" 2 "ErrorIndicator" 1 "ButtonPressed" 0 "ButtonNotPressed" ;
VAL_ 2365402366 Joystick6Button8PressedStatus 3 "NotAvailable" 2 "ErrorIndicator" 1 "ButtonPressed" 0 "ButtonNotPressed" ;
VAL_ 2365402366 Joystick6Button9PressedStatus 3 "NotAvailable" 2 "ErrorIndicator" 1 "ButtonPressed" 0 "ButtonNotPressed" ;
VAL_ 2365400062 Jstk10GrpXAxsNtrlPstnStts 3 "NotAvailable" 2 "ErrorIndicator" 1 "InNeutralPos" 0 "NotInNeutralPos" ;
VAL_ 2365400062 Jstk10GrpXAxsLvrLftNgtvPstnStts 3 "NotAvailable" 2 "ErrorIndicator" 1 "OnNegativeSideOfNeutral" 0 "NotOnNegativeSideOfNeutral" ;
VAL_ 2365400062 Jst10GpXAxsLvRtPstvPstStts 3 "NotAvailable" 2 "ErrorIndicator" 1 "OnPositiveSideOfNeutral" 0 "NotOnPositiveSideOfNeutral" ;
VAL_ 2365400062 Jstk10GrpYAxsNtrlPstnStts 3 "NotAvailable" 2 "ErrorIndicator" 1 "InNeutralPos" 0 "NotInNeutralPos" ;
VAL_ 2365400062 Jstk10GrpYAxsLvrBkNgtvPstnStts 3 "NotAvailable" 2 "ErrorIndicator" 1 "OnNegativeSideOfNeutral" 0 "NotOnNegativeSideOfNeutral" ;
VAL_ 2365400062 Jst10GpYAxsLvFwdPstvPstStts 3 "NotAvailable" 2 "ErrorIndicator" 1 "OnPositiveSideOfNeutral" 0 "NotOnPositiveSideOfNeutral" ;
VAL_ 2365400062 Jstk10ThtAxsNtrlPstnStts 3 "NotAvailable" 2 "ErrorIndicator" 1 "InNeutralPos" 0 "NotInNeutralPos" ;
VAL_ 2365400062 Jst10TtAxsCtCwsNtvPstStts 3 "NotAvailable" 2 "ErrorIndicator" 1 "OnNegativeSideOfNeutral" 0 "NotOnNegativeSideOfNeutral" ;
VAL_ 2365400062 Jstk10ThtAxsClkwsPstvPstnStts 3 "NotAvailable" 2 "ErrorIndicator" 1 "OnPositiveSideOfNeutral" 0 "NotOnPositiveSideOfNeutral" ;
VAL_ 2365400062 Jstk10ThtAxsDtntPstnStts 3 "NotAvailable" 2 "ErrorIndicator" 1 "InDetentPos" 0 "NotInDetentPos" ;
VAL_ 2365400062 Jstk10GrpYAxsDtntPstnStts 3 "NotAvailable" 2 "ErrorIndicator" 1 "InDetentPos" 0 "NotInDetentPos" ;
VAL_ 2365400062 Jstk10GrpXAxsDtntPstnStts 3 "NotAvailable" 2 "ErrorIndicator" 1 "InDetentPos" 0 "NotInDetentPos" ;
VAL_ 2365400318 Jstk10XAxsNtrlPstnStts 3 "NotAvailable" 2 "ErrorIndicator" 1 "InNeutralPos" 0 "NotInNeutralPos" ;
VAL_ 2365400318 Jstk10XAxsLvrLftNgtvPstnStts 3 "NotAvailable" 2 "ErrorIndicator" 1 "OnNegativeSideOfNeutral" 0 "NotOnNegativeSideOfNeutral" ;
VAL_ 2365400318 Jstk10XAxsLvrRghtPstvPstnStts 3 "NotAvailable" 2 "ErrorIndicator" 1 "OnPositiveSideOfNeutral" 0 "NotOnPositiveSideOfNeutral" ;
VAL_ 2365400318 Jstk10YAxsNtrlPstnStts 3 "NotAvailable" 2 "ErrorIndicator" 1 "InNeutralPos" 0 "NotInNeutralPos" ;
VAL_ 2365400318 Jstk10YAxsLvrBkNgtvPstnStts 3 "NotAvailable" 2 "ErrorIndicator" 1 "OnNegativeSideOfNeutral" 0 "NotOnNegativeSideOfNeutral" ;
VAL_ 2365400318 Jstk10YAxsLvrFrwrdPstvPstnStts 3 "NotAvailable" 2 "ErrorIndicator" 1 "OnPositiveSideOfNeutral" 0 "NotOnPositiveSideOfNeutral" ;
VAL_ 2365400318 Jstk10YAxsDtntPstnStts 3 "NotAvailable" 2 "ErrorIndicator" 1 "InDetentPos" 0 "NotInDetentPos" ;
VAL_ 2365400318 Jstk10XAxsDtntPstnStts 3 "NotAvailable" 2 "ErrorIndicator" 1 "InDetentPos" 0 "NotInDetentPos" ;
VAL_ 2365400574 Jstk9GrpXAxsNtrlPstnStts 3 "NotAvailable" 2 "ErrorIndicator" 1 "InNeutralPos" 0 "NotInNeutralPos" ;
VAL_ 2365400574 Jstk9GrpXAxsLvrLftNgtvPstnStts 3 "NotAvailable" 2 "ErrorIndicator" 1 "OnNegativeSideOfNeutral" 0 "NotOnNegativeSideOfNeutral" ;
VAL_ 2365400574 Jstk9GrpXAxsLvrRghtPstvPstnStts 3 "NotAvailable" 2 "ErrorIndicator" 1 "OnPositiveSideOfNeutral" 0 "NotOnPositiveSideOfNeutral" ;
VAL_ 2365400574 Jstk9GrpYAxsNtrlPstnStts 3 "NotAvailable" 2 "ErrorIndicator" 1 "InNeutralPos" 0 "NotInNeutralPos" ;
VAL_ 2365400574 Jstk9GrpYAxsLvrBkNgtvPstnStts 3 "NotAvailable" 2 "ErrorIndicator" 1 "OnNegativeSideOfNeutral" 0 "NotOnNegativeSideOfNeutral" ;
VAL_ 2365400574 Jst9GpYAxsLvFwdPstvPstStts 3 "NotAvailable" 2 "ErrorIndicator" 1 "OnPositiveSideOfNeutral" 0 "NotOnPositiveSideOfNeutral" ;
VAL_ 2365400574 Jstk9ThtAxsNtrlPstnStts 3 "NotAvailable" 2 "ErrorIndicator" 1 "InNeutralPos" 0 "NotInNeutralPos" ;
VAL_ 2365400574 Jst9TtAxsCtCwsNtvPstStts 3 "NotAvailable" 2 "ErrorIndicator" 1 "OnNegativeSideOfNeutral" 0 "NotOnNegativeSideOfNeutral" ;
VAL_ 2365400574 Jstk9ThtAxsClkwsPstvPstnStts 3 "NotAvailable" 2 "ErrorIndicator" 1 "OnPositiveSideOfNeutral" 0 "NotOnPositiveSideOfNeutral" ;
VAL_ 2365400574 Jstk9ThtAxsDtntPstnStts 3 "NotAvailable" 2 "ErrorIndicator" 1 "InDetentPos" 0 "NotInDetentPos" ;
VAL_ 2365400574 Jstk9GrpYAxsDtntPstnStts 3 "NotAvailable" 2 "ErrorIndicator" 1 "InDetentPos" 0 "NotInDetentPos" ;
VAL_ 2365400574 Jstk9GrpXAxsDtntPstnStts 3 "NotAvailable" 2 "ErrorIndicator" 1 "InDetentPos" 0 "NotInDetentPos" ;
VAL_ 2365400830 Jstk9XAxsNtrlPstnStts 3 "NotAvailable" 2 "ErrorIndicator" 1 "InNeutralPos" 0 "NotInNeutralPos" ;
VAL_ 2365400830 Jstk9XAxsLvrLftNgtvPstnStts 3 "NotAvailable" 2 "ErrorIndicator" 1 "OnNegativeSideOfNeutral" 0 "NotOnNegativeSideOfNeutral" ;
VAL_ 2365400830 Jstk9XAxsLvrRghtPstvPstnStts 3 "NotAvailable" 2 "ErrorIndicator" 1 "OnPositiveSideOfNeutral" 0 "NotOnPositiveSideOfNeutral" ;
VAL_ 2365400830 Jstk9YAxsNtrlPstnStts 3 "NotAvailable" 2 "ErrorIndicator" 1 "InNeutralPos" 0 "NotInNeutralPos" ;
VAL_ 2365400830 Jstk9YAxsLvrBkNgtvPstnStts 3 "NotAvailable" 2 "ErrorIndicator" 1 "OnNegativeSideOfNeutral" 0 "NotOnNegativeSideOfNeutral" ;
VAL_ 2365400830 Jstk9YAxsLvrFrwrdPstvPstnStts 3 "NotAvailable" 2 "ErrorIndicator" 1 "OnPositiveSideOfNeutral" 0 "NotOnPositiveSideOfNeutral" ;
VAL_ 2365400830 Jstk9YAxsDtntPstnStts 3 "NotAvailable" 2 "ErrorIndicator" 1 "InDetentPos" 0 "NotInDetentPos" ;
VAL_ 2365400830 Jstk9XAxsDtntPstnStts 3 "NotAvailable" 2 "ErrorIndicator" 1 "InDetentPos" 0 "NotInDetentPos" ;
VAL_ 2365401086 Jstk8GrpXAxsNtrlPstnStts 3 "NotAvailable" 2 "ErrorIndicator" 1 "InNeutralPos" 0 "NotInNeutralPos" ;
VAL_ 2365401086 Jstk8GrpXAxsLvrLftNgtvPstnStts 3 "NotAvailable" 2 "ErrorIndicator" 1 "OnNegativeSideOfNeutral" 0 "NotOnNegativeSideOfNeutral" ;
VAL_ 2365401086 Jstk8GrpXAxsLvrRghtPstvPstnStts 3 "NotAvailable" 2 "ErrorIndicator" 1 "OnPositiveSideOfNeutral" 0 "NotOnPositiveSideOfNeutral" ;
VAL_ 2365401086 Jstk8GrpYAxsNtrlPstnStts 3 "NotAvailable" 2 "ErrorIndicator" 1 "InNeutralPos" 0 "NotInNeutralPos" ;
VAL_ 2365401086 Jstk8GrpYAxsLvrBkNgtvPstnStts 3 "NotAvailable" 2 "ErrorIndicator" 1 "OnNegativeSideOfNeutral" 0 "NotOnNegativeSideOfNeutral" ;
VAL_ 2365401086 Jst8GpYAxsLvFwdPstvPstStts 3 "NotAvailable" 2 "ErrorIndicator" 1 "OnPositiveSideOfNeutral" 0 "NotOnPositiveSideOfNeutral" ;
VAL_ 2365401086 Jstk8ThtAxsNtrlPstnStts 3 "NotAvailable" 2 "ErrorIndicator" 1 "InNeutralPos" 0 "NotInNeutralPos" ;
VAL_ 2365401086 Jst8TtAxsCtCwsNtvPstStts 3 "NotAvailable" 2 "ErrorIndicator" 1 "OnNegativeSideOfNeutral" 0 "NotOnNegativeSideOfNeutral" ;
VAL_ 2365401086 Jstk8ThtAxsClkwsPstvPstnStts 3 "NotAvailable" 2 "ErrorIndicator" 1 "OnPositiveSideOfNeutral" 0 "NotOnPositiveSideOfNeutral" ;
VAL_ 2365401086 Jstk8ThtAxsDtntPstnStts 3 "NotAvailable" 2 "ErrorIndicator" 1 "InDetentPos" 0 "NotInDetentPos" ;
VAL_ 2365401086 Jstk8GrpYAxsDtntPstnStts 3 "NotAvailable" 2 "ErrorIndicator" 1 "InDetentPos" 0 "NotInDetentPos" ;
VAL_ 2365401086 Jstk8GrpXAxsDtntPstnStts 3 "NotAvailable" 2 "ErrorIndicator" 1 "InDetentPos" 0 "NotInDetentPos" ;
VAL_ 2365401342 Jstk8XAxsNtrlPstnStts 3 "NotAvailable" 2 "ErrorIndicator" 1 "InNeutralPos" 0 "NotInNeutralPos" ;
VAL_ 2365401342 Jstk8XAxsLvrLftNgtvPstnStts 3 "NotAvailable" 2 "ErrorIndicator" 1 "OnNegativeSideOfNeutral" 0 "NotOnNegativeSideOfNeutral" ;
VAL_ 2365401342 Jstk8XAxsLvrRghtPstvPstnStts 3 "NotAvailable" 2 "ErrorIndicator" 1 "OnPositiveSideOfNeutral" 0 "NotOnPositiveSideOfNeutral" ;
VAL_ 2365401342 Jstk8YAxsNtrlPstnStts 3 "NotAvailable" 2 "ErrorIndicator" 1 "InNeutralPos" 0 "NotInNeutralPos" ;
VAL_ 2365401342 Jstk8YAxsLvrBkNgtvPstnStts 3 "NotAvailable" 2 "ErrorIndicator" 1 "OnNegativeSideOfNeutral" 0 "NotOnNegativeSideOfNeutral" ;
VAL_ 2365401342 Jstk8YAxsLvrFrwrdPstvPstnStts 3 "NotAvailable" 2 "ErrorIndicator" 1 "OnPositiveSideOfNeutral" 0 "NotOnPositiveSideOfNeutral" ;
VAL_ 2365401342 Jstk8YAxsDtntPstnStts 3 "NotAvailable" 2 "ErrorIndicator" 1 "InDetentPos" 0 "NotInDetentPos" ;
VAL_ 2365401342 Jstk8XAxsDtntPstnStts 3 "NotAvailable" 2 "ErrorIndicator" 1 "InDetentPos" 0 "NotInDetentPos" ;
VAL_ 2365401598 Jstk7GrpXAxsNtrlPstnStts 3 "NotAvailable" 2 "ErrorIndicator" 1 "InNeutralPos" 0 "NotInNeutralPos" ;
VAL_ 2365401598 Jstk7GrpXAxsLvrLftNgtvPstnStts 3 "NotAvailable" 2 "ErrorIndicator" 1 "OnNegativeSideOfNeutral" 0 "NotOnNegativeSideOfNeutral" ;
VAL_ 2365401598 Jstk7GrpXAxsLvrRghtPstvPstnStts 3 "NotAvailable" 2 "ErrorIndicator" 1 "OnPositiveSideOfNeutral" 0 "NotOnPositiveSideOfNeutral" ;
VAL_ 2365401598 Jstk7GrpYAxsNtrlPstnStts 3 "NotAvailable" 2 "ErrorIndicator" 1 "InNeutralPos" 0 "NotInNeutralPos" ;
VAL_ 2365401598 Jstk7GrpYAxsLvrBkNgtvPstnStts 3 "NotAvailable" 2 "ErrorIndicator" 1 "OnNegativeSideOfNeutral" 0 "NotOnNegativeSideOfNeutral" ;
VAL_ 2365401598 Jst7GpYAxsLvFwdPstvPstStts 3 "NotAvailable" 2 "ErrorIndicator" 1 "OnPositiveSideOfNeutral" 0 "NotOnPositiveSideOfNeutral" ;
VAL_ 2365401598 Jstk7ThtAxsNtrlPstnStts 3 "NotAvailable" 2 "ErrorIndicator" 1 "InNeutralPos" 0 "NotInNeutralPos" ;
VAL_ 2365401598 Jst7TtAxsCtCwsNtvPstStts 3 "NotAvailable" 2 "ErrorIndicator" 1 "OnNegativeSideOfNeutral" 0 "NotOnNegativeSideOfNeutral" ;
VAL_ 2365401598 Jstk7ThtAxsClkwsPstvPstnStts 3 "NotAvailable" 2 "ErrorIndicator" 1 "OnPositiveSideOfNeutral" 0 "NotOnPositiveSideOfNeutral" ;
VAL_ 2365401598 Jstk7ThtAxsDtntPstnStts 3 "NotAvailable" 2 "ErrorIndicator" 1 "InDetentPos" 0 "NotInDetentPos" ;
VAL_ 2365401598 Jstk7GrpYAxsDtntPstnStts 3 "NotAvailable" 2 "ErrorIndicator" 1 "InDetentPos" 0 "NotInDetentPos" ;
VAL_ 2365401598 Jstk7GrpXAxsDtntPstnStts 3 "NotAvailable" 2 "ErrorIndicator" 1 "InDetentPos" 0 "NotInDetentPos" ;
VAL_ 2365401854 Jstk7XAxsNtrlPstnStts 3 "NotAvailable" 2 "ErrorIndicator" 1 "InNeutralPos" 0 "NotInNeutralPos" ;
VAL_ 2365401854 Jstk7XAxsLvrLftNgtvPstnStts 3 "NotAvailable" 2 "ErrorIndicator" 1 "OnNegativeSideOfNeutral" 0 "NotOnNegativeSideOfNeutral" ;
VAL_ 2365401854 Jstk7XAxsLvrRghtPstvPstnStts 3 "NotAvailable" 2 "ErrorIndicator" 1 "OnPositiveSideOfNeutral" 0 "NotOnPositiveSideOfNeutral" ;
VAL_ 2365401854 Jstk7YAxsNtrlPstnStts 3 "NotAvailable" 2 "ErrorIndicator" 1 "InNeutralPos" 0 "NotInNeutralPos" ;
VAL_ 2365401854 Jstk7YAxsLvrBkNgtvPstnStts 3 "NotAvailable" 2 "ErrorIndicator" 1 "OnNegativeSideOfNeutral" 0 "NotOnNegativeSideOfNeutral" ;
VAL_ 2365401854 Jstk7YAxsLvrFrwrdPstvPstnStts 3 "NotAvailable" 2 "ErrorIndicator" 1 "OnPositiveSideOfNeutral" 0 "NotOnPositiveSideOfNeutral" ;
VAL_ 2365401854 Jstk7YAxsDtntPstnStts 3 "NotAvailable" 2 "ErrorIndicator" 1 "InDetentPos" 0 "NotInDetentPos" ;
VAL_ 2365401854 Jstk7XAxsDtntPstnStts 3 "NotAvailable" 2 "ErrorIndicator" 1 "InDetentPos" 0 "NotInDetentPos" ;
VAL_ 2365402110 Jstk6GrpXAxsNtrlPstnStts 3 "NotAvailable" 2 "ErrorIndicator" 1 "InNeutralPos" 0 "NotInNeutralPos" ;
VAL_ 2365402110 Jstk6GrpXAxsLvrLftNgtvPstnStts 3 "NotAvailable" 2 "ErrorIndicator" 1 "OnNegativeSideOfNeutral" 0 "NotOnNegativeSideOfNeutral" ;
VAL_ 2365402110 Jstk6GrpXAxsLvrRghtPstvPstnStts 3 "NotAvailable" 2 "ErrorIndicator" 1 "OnPositiveSideOfNeutral" 0 "NotOnPositiveSideOfNeutral" ;
VAL_ 2365402110 Jstk6GrpYAxsNtrlPstnStts 3 "NotAvailable" 2 "ErrorIndicator" 1 "InNeutralPos" 0 "NotInNeutralPos" ;
VAL_ 2365402110 Jstk6GrpYAxsLvrBkNgtvPstnStts 3 "NotAvailable" 2 "ErrorIndicator" 1 "OnNegativeSideOfNeutral" 0 "NotOnNegativeSideOfNeutral" ;
VAL_ 2365402110 Jst6GpYAxsLvFwdPstvPstStts 3 "NotAvailable" 2 "ErrorIndicator" 1 "OnPositiveSideOfNeutral" 0 "NotOnPositiveSideOfNeutral" ;
VAL_ 2365402110 Jstk6ThtAxsNtrlPstnStts 3 "NotAvailable" 2 "ErrorIndicator" 1 "InNeutralPos" 0 "NotInNeutralPos" ;
VAL_ 2365402110 Jst6TtAxsCtCwsNtvPstStts 3 "NotAvailable" 2 "ErrorIndicator" 1 "OnNegativeSideOfNeutral" 0 "NotOnNegativeSideOfNeutral" ;
VAL_ 2365402110 Jstk6ThtAxsClkwsPstvPstnStts 3 "NotAvailable" 2 "ErrorIndicator" 1 "OnPositiveSideOfNeutral" 0 "NotOnPositiveSideOfNeutral" ;
VAL_ 2365402110 Jstk6ThtAxsDtntPstnStts 3 "NotAvailable" 2 "ErrorIndicator" 1 "InDetentPos" 0 "NotInDetentPos" ;
VAL_ 2365402110 Jstk6GrpYAxsDtntPstnStts 3 "NotAvailable" 2 "ErrorIndicator" 1 "InDetentPos" 0 "NotInDetentPos" ;
VAL_ 2365402110 Jstk6GrpXAxsDtntPstnStts 3 "NotAvailable" 2 "ErrorIndicator" 1 "InDetentPos" 0 "NotInDetentPos" ;
VAL_ 2365402366 Jstk6XAxsNtrlPstnStts 3 "NotAvailable" 2 "ErrorIndicator" 1 "InNeutralPos" 0 "NotInNeutralPos" ;
VAL_ 2365402366 Jstk6XAxsLvrLftNgtvPstnStts 3 "NotAvailable" 2 "ErrorIndicator" 1 "OnNegativeSideOfNeutral" 0 "NotOnNegativeSideOfNeutral" ;
VAL_ 2365402366 Jstk6XAxsLvrRghtPstvPstnStts 3 "NotAvailable" 2 "ErrorIndicator" 1 "OnPositiveSideOfNeutral" 0 "NotOnPositiveSideOfNeutral" ;
VAL_ 2365402366 Jstk6YAxsNtrlPstnStts 3 "NotAvailable" 2 "ErrorIndicator" 1 "InNeutralPos" 0 "NotInNeutralPos" ;
VAL_ 2365402366 Jstk6YAxsLvrBkNgtvPstnStts 3 "NotAvailable" 2 "ErrorIndicator" 1 "OnNegativeSideOfNeutral" 0 "NotOnNegativeSideOfNeutral" ;
VAL_ 2365402366 Jstk6YAxsLvrFrwrdPstvPstnStts 3 "NotAvailable" 2 "ErrorIndicator" 1 "OnPositiveSideOfNeutral" 0 "NotOnPositiveSideOfNeutral" ;
VAL_ 2365402366 Jstk6YAxsDtntPstnStts 3 "NotAvailable" 2 "ErrorIndicator" 1 "InDetentPos" 0 "NotInDetentPos" ;
VAL_ 2365402366 Jstk6XAxsDtntPstnStts 3 "NotAvailable" 2 "ErrorIndicator" 1 "InDetentPos" 0 "NotInDetentPos" ;
